VERSION ""

NS_ :

BS_:

BU_:

BO_ 258 VCLEFT_doorStatus: 8 Vector__XXX
 SG_ VCLEFT_mirrorDipped : 63|1@1+ (1,0) [0|0] "" Vector__XXX
 SG_ VCLEFT_frontHandlePulledPersist : 62|1@1+ (1,0) [0|0] "" Vector__XXX
 SG_ VCLEFT_rearHandlePulledPersist : 61|1@1+ (1,0) [0|0] "" Vector__XXX
 SG_ VCLEFT_mirrorHeatState : 58|3@1+ (1,0) [0|0] "" Vector__XXX
 SG_ VCLEFT_mirrorRecallState : 55|3@1+ (1,0) [0|0] "" Vector__XXX
 SG_ VCLEFT_mirrorFoldState : 52|3@1+ (1,0) [0|0] "" Vector__XXX
 SG_ VCLEFT_mirrorState : 49|3@1+ (1,0) [0|0] "" Vector__XXX
 SG_ VCLEFT_mirrorTiltYPosition : 41|8@1+ (0.02,0) [0|0] "" Vector__XXX
 SG_ VCLEFT_mirrorTiltXPosition : 33|8@1+ (0.02,0) [0|0] "" Vector__XXX
 SG_ VCLEFT_rearIntSwitchPressed : 32|1@1+ (1,0) [0|0] "" Vector__XXX
 SG_ VCLEFT_frontIntSwitchPressed : 31|1@1+ (1,0) [0|0] "" Vector__XXX
 SG_ VCLEFT_rearIntSwitchFaulted : 29|1@1+ (1,0) [0|0] "" Vector__XXX
 SG_ VCLEFT_frontIntSwitchFaulted : 28|1@1+ (1,0) [0|0] "" Vector__XXX
 SG_ VCLEFT_lastDoorReqSourceRear : 25|3@1+ (1,0) [0|0] "" Vector__XXX
 SG_ VCLEFT_lastDoorReqSourceFront : 22|3@1+ (1,0) [0|0] "" Vector__XXX
 SG_ VCLEFT_rearLatchStatus : 18|4@1+ (1,0) [0|0] "" Vector__XXX
 SG_ VCLEFT_frontLatchStatus : 14|4@1+ (1,0) [0|0] "" Vector__XXX
 SG_ VCLEFT_rearRelActuatorSwitch : 13|1@1+ (1,0) [0|0] "" Vector__XXX
 SG_ VCLEFT_frontRelActuatorSwitch : 12|1@1+ (1,0) [0|0] "" Vector__XXX
 SG_ VCLEFT_rearHandlePulled : 11|1@1+ (1,0) [0|0] "" Vector__XXX
 SG_ VCLEFT_frontHandlePulled : 10|1@1+ (1,0) [0|0] "" Vector__XXX
 SG_ VCLEFT_rearLatchSwitch : 9|1@1+ (1,0) [0|0] "" Vector__XXX
 SG_ VCLEFT_frontLatchSwitch : 8|1@1+ (1,0) [0|0] "" Vector__XXX
 SG_ VCLEFT_doorClosureStatusRear : 4|4@1+ (1,0) [0|0] "" Vector__XXX
 SG_ VCLEFT_doorClosureStatusFront : 0|4@1+ (1,0) [0|0] "" Vector__XXX

BO_ 259 VCRIGHT_doorStatus: 8 Vector__XXX
 SG_ VCRIGHT_rearHandlePulledPersist : 63|1@1+ (1,0) [0|0] "" Vector__XXX
 SG_ VCRIGHT_mirrorRecallState : 60|3@1+ (1,0) [0|0] "" Vector__XXX
 SG_ VCRIGHT_trunkLatchStatus : 56|4@1+ (1,0) [0|0] "" Vector__XXX
 SG_ VCRIGHT_mirrorDipped : 55|1@1+ (1,0) [0|0] "" Vector__XXX
 SG_ VCRIGHT_mirrorFoldState : 52|3@1+ (1,0) [0|0] "" Vector__XXX
 SG_ VCRIGHT_mirrorState : 49|3@1+ (1,0) [0|0] "" Vector__XXX
 SG_ VCRIGHT_mirrorTiltYPosition : 41|8@1+ (0.02,0) [0|0] "" Vector__XXX
 SG_ VCRIGHT_mirrorTiltXPosition : 33|8@1+ (0.02,0) [0|0] "" Vector__XXX
 SG_ VCRIGHT_rearIntSwitchPressed : 32|1@1+ (1,0) [0|0] "" Vector__XXX
 SG_ VCRIGHT_frontIntSwitchPressed : 31|1@1+ (1,0) [0|0] "" Vector__XXX
 SG_ VCRIGHT_frontHandlePulledPersist : 30|1@1+ (1,0) [0|0] "" Vector__XXX
 SG_ VCRIGHT_rearIntSwitchFaulted : 29|1@1+ (1,0) [0|0] "" Vector__XXX
 SG_ VCRIGHT_frontIntSwitchFaulted : 28|1@1+ (1,0) [0|0] "" Vector__XXX
 SG_ VCRIGHT_lastDoorReqSourceRear : 25|3@1+ (1,0) [0|0] "" Vector__XXX
 SG_ VCRIGHT_lastDoorReqSourceFront : 22|3@1+ (1,0) [0|0] "" Vector__XXX
 SG_ VCRIGHT_rearLatchStatus : 18|4@1+ (1,0) [0|0] "" Vector__XXX
 SG_ VCRIGHT_frontLatchStatus : 14|4@1+ (1,0) [0|0] "" Vector__XXX
 SG_ VCRIGHT_rearRelActuatorSwitch : 13|1@1+ (1,0) [0|0] "" Vector__XXX
 SG_ VCRIGHT_frontRelActuatorSwitch : 12|1@1+ (1,0) [0|0] "" Vector__XXX
 SG_ VCRIGHT_rearHandlePulled : 11|1@1+ (1,0) [0|0] "" Vector__XXX
 SG_ VCRIGHT_frontHandlePulled : 10|1@1+ (1,0) [0|0] "" Vector__XXX
 SG_ VCRIGHT_rearLatchSwitch : 9|1@1+ (1,0) [0|0] "" Vector__XXX
 SG_ VCRIGHT_frontLatchSwitch : 8|1@1+ (1,0) [0|0] "" Vector__XXX
 SG_ VCRIGHT_doorClosureStatusRear : 4|4@1+ (1,0) [0|0] "" Vector__XXX
 SG_ VCRIGHT_doorClosureStatusFront : 0|4@1+ (1,0) [0|0] "" Vector__XXX

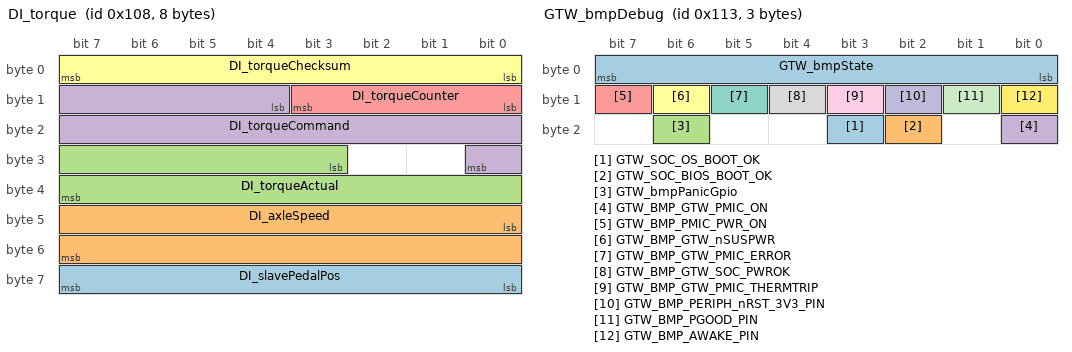
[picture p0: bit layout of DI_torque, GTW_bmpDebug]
BO_ 264 DI_torque: 8 VEH
 SG_ DI_slavePedalPos : 56|8@1+ (0.4,0) [0|100] "%"  X
 SG_ DI_axleSpeed : 40|16@1- (0.1,0) [0|0] "RPM"  X
 SG_ DI_torqueActual : 27|13@1- (2,0) [0|0] "Nm"  X
 SG_ DI_torqueCommand : 12|13@1- (2,0) [0|0] "Nm"  X
 SG_ DI_torqueCounter : 8|4@1+ (1,0) [0|0] ""  X
 SG_ DI_torqueChecksum : 0|8@1+ (1,0) [0|0] ""  X

BO_ 275 GTW_bmpDebug: 3 Vector__XXX
 SG_ GTW_SOC_OS_BOOT_OK : 19|1@1+ (1,0) [0|0] "" Vector__XXX
 SG_ GTW_SOC_BIOS_BOOT_OK : 18|1@1+ (1,0) [0|0] "" Vector__XXX
 SG_ GTW_bmpPanicGpio : 22|1@0+ (1,0) [0|0] "" Vector__XXX
 SG_ GTW_BMP_GTW_PMIC_ON : 16|1@1+ (1,0) [0|0] "" Vector__XXX
 SG_ GTW_BMP_PMIC_PWR_ON : 15|1@1+ (1,0) [0|0] "" Vector__XXX
 SG_ GTW_BMP_GTW_nSUSPWR : 14|1@1+ (1,0) [0|0] "" Vector__XXX
 SG_ GTW_BMP_GTW_PMIC_ERROR : 13|1@1+ (1,0) [0|0] "" Vector__XXX
 SG_ GTW_BMP_GTW_SOC_PWROK : 12|1@1+ (1,0) [0|0] "" Vector__XXX
 SG_ GTW_BMP_GTW_PMIC_THERMTRIP : 11|1@1+ (1,0) [0|0] "" Vector__XXX
 SG_ GTW_BMP_PERIPH_nRST_3V3_PIN : 10|1@1+ (1,0) [0|0] "" Vector__XXX
 SG_ GTW_BMP_PGOOD_PIN : 9|1@1+ (1,0) [0|0] "" Vector__XXX
 SG_ GTW_BMP_AWAKE_PIN : 8|1@1+ (1,0) [0|0] "" Vector__XXX
 SG_ GTW_bmpState : 7|8@0+ (1,0) [0|0] "" Vector__XXX

BO_ 280 DI_systemStatus: 8 Vector__XXX
 SG_ DI_vehicleAcceleration : 52|12@1- (0.01,0) [0|0] "" Vector__XXX
 SG_ DI_regenLight : 51|1@1+ (1,0) [0|0] "" Vector__XXX
 SG_ DI_autonomyControlActive : 50|1@1+ (1,0) [0|0] "" Vector__XXX
 SG_ DI_trackModeState : 48|2@1+ (1,0) [0|0] "" Vector__XXX
 SG_ DI_keepDrivePowerStateRequest : 47|1@1+ (1,0) [0|0] "" Vector__XXX
 SG_ DI_brakeSource : 46|1@1+ (1,0) [0|0] "" Vector__XXX
 SG_ DI_epbRequest : 44|2@1+ (1,0) [0|0] "" Vector__XXX
 SG_ DI_dynoModeAvailable : 43|1@1+ (1,0) [0|0] "" Vector__XXX
 SG_ DI_tractionControlMode : 40|3@1+ (1,0) [0|0] "" Vector__XXX
 SG_ DI_accelPedalPos : 32|8@1+ (0.4,0) [0|0] "" Vector__XXX
 SG_ DI_hvilSystemStatus : 27|2@1+ (1,0) [0|0] "" Vector__XXX
 SG_ DI_driveBlocked : 24|3@1+ (1,0) [0|0] "" Vector__XXX
 SG_ DI_gear : 21|3@1+ (1,0) [0|0] "" Vector__XXX
 SG_ DI_brakePedalState : 19|2@1+ (1,0) [0|0] "" Vector__XXX
 SG_ DI_systemState : 16|3@1+ (1,0) [0|0] "" Vector__XXX
 SG_ DI_immobilizerState : 13|3@1+ (1,0) [0|0] "" Vector__XXX
 SG_ DI_systemStatusCounter : 8|4@1+ (1,0) [0|0] "" Vector__XXX
 SG_ DI_systemStatusChecksum : 0|8@1+ (1,0) [0|0] "" Vector__XXX

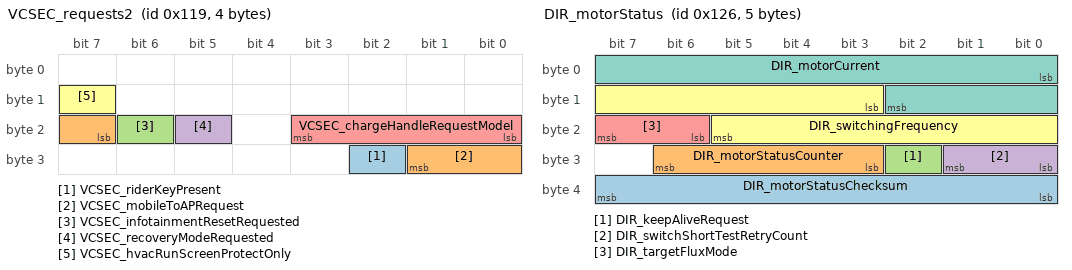
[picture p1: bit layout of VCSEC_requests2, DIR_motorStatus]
BO_ 281 VCSEC_requests2: 4 Vector__XXX
 SG_ VCSEC_riderKeyPresent : 26|1@1+ (1,0) [0|0] "" Vector__XXX
 SG_ VCSEC_mobileToAPRequest : 23|3@1+ (1,0) [0|0] "" Vector__XXX
 SG_ VCSEC_infotainmentResetRequested : 22|1@1+ (1,0) [0|0] "" Vector__XXX
 SG_ VCSEC_recoveryModeRequested : 21|1@1+ (1,0) [0|0] "" Vector__XXX
 SG_ VCSEC_chargeHandleRequestModel : 16|4@1+ (1,0) [0|0] "" Vector__XXX
 SG_ VCSEC_hvacRunScreenProtectOnly : 15|1@1+ (1,0) [0|0] "" Vector__XXX

BO_ 290 VCLEFT_doorStatus2: 8 Vector__XXX
 SG_ VCLEFT_mirrorTiltYOffset m1 : 56|8@1- (0.02,0) [0|0] "" Vector__XXX
 SG_ VCLEFT_rearHandlePWM m0 : 56|7@1+ (1,0) [0|0] "" Vector__XXX
 SG_ VCLEFT_frontHandlePWM m0 : 48|7@1+ (1,0) [0|0] "" Vector__XXX
 SG_ VCLEFT_mirrorTiltXOffset m1 : 48|8@1- (0.02,0) [0|0] "" Vector__XXX
 SG_ VCLEFT_mirrorDimmed m0 : 47|1@1+ (1,0) [0|0] "" Vector__XXX
 SG_ VCLEFT_BPillarCameraHeaterCurrent m1 : 40|6@1+ (0.02,0) [0|0] "" Vector__XXX
 SG_ VCLEFT_mirrorFoldCurrent m0 : 40|7@1- (0.05,0) [0|0] "" Vector__XXX
 SG_ VCLEFT_rearHandle5vEnable m0 : 39|1@1+ (1,0) [0|0] "" Vector__XXX
 SG_ VCLEFT_frontHandle5vEnable m0 : 38|1@1+ (1,0) [0|0] "" Vector__XXX
 SG_ VCLEFT_rearHandleDebounceStatus m0 : 35|3@1+ (1,0) [0|0] "" Vector__XXX
 SG_ VCLEFT_frontHandleDebounceStatus m0 : 32|3@1+ (1,0) [0|0] "" Vector__XXX
 SG_ VCLEFT_mirrorFoldType m0 : 30|2@1+ (1,0) [0|0] "" Vector__XXX
 SG_ VCLEFT_rearHandleRawStatus m0 : 27|3@1+ (1,0) [0|0] "" Vector__XXX
 SG_ VCLEFT_frontHandleRawStatus m0 : 24|3@1+ (1,0) [0|0] "" Vector__XXX
 SG_ VCLEFT_rearDoorState m0 : 20|3@1+ (1,0) [0|0] "" Vector__XXX
 SG_ VCLEFT_frontDoorState m0 : 17|3@1+ (1,0) [0|0] "" Vector__XXX
 SG_ VCLEFT_BPillarCameraHeaterState m1 : 16|3@1+ (1,0) [0|0] "" Vector__XXX
 SG_ VCLEFT_vehicleInMotion m0 : 16|1@1+ (1,0) [0|0] "" Vector__XXX
 SG_ VCLEFT_frontLatchRelDuty m1 : 8|8@1+ (1,0) [0|0] "" Vector__XXX
 SG_ VCLEFT_rearLatchRelDuty m0 : 8|8@1+ (1,0) [0|0] "" Vector__XXX
 SG_ VCLEFT_doorStatus2Index M : 0|1@1+ (1,0) [0|0] "" Vector__XXX

BO_ 291 VCRIGHT_doorStatus2: 8 Vector__XXX
 SG_ VCRIGHT_trunkHomeSwitch m0 : 63|1@1+ (1,0) [0|0] "" Vector__XXX
 SG_ VCRIGHT_trunkPawlSwitch m0 : 62|1@1+ (1,0) [0|0] "" Vector__XXX
 SG_ VCRIGHT_trunkRatchetSwitch m0 : 61|1@1+ (1,0) [0|0] "" Vector__XXX
 SG_ VCRIGHT_mirrorTiltYOffset m1 : 56|8@1- (0.02,0) [0|0] "" Vector__XXX
 SG_ VCRIGHT_mirrorTiltXOffset m1 : 48|8@1- (0.02,0) [0|0] "" Vector__XXX
 SG_ VCRIGHT_rearDefrostCurrentFiltered m0 : 48|7@1+ (1,0) [0|0] "" Vector__XXX
 SG_ VCRIGHT_gloveboxOutput m0 : 47|1@1+ (1,0) [0|0] "" Vector__XXX
 SG_ VCRIGHT_BPillarCameraHeaterCurrent m1 : 40|6@1+ (0.02,0) [0|0] "" Vector__XXX
 SG_ VCRIGHT_mirrorFoldCurrent m0 : 40|7@1- (0.05,0) [0|0] "" Vector__XXX
 SG_ VCRIGHT_rearHandle5vEnable m0 : 39|1@1+ (1,0) [0|0] "" Vector__XXX
 SG_ VCRIGHT_frontHandle5vEnable m0 : 38|1@1+ (1,0) [0|0] "" Vector__XXX
 SG_ VCRIGHT_rearHandleDebounceStatus m0 : 35|3@1+ (1,0) [0|0] "" Vector__XXX
 SG_ VCRIGHT_frontHandleDebounceStatus m0 : 32|3@1+ (1,0) [0|0] "" Vector__XXX
 SG_ VCRIGHT_mirrorFoldType m0 : 30|2@1+ (1,0) [0|0] "" Vector__XXX
 SG_ VCRIGHT_rearHandleRawStatus m0 : 27|3@1+ (1,0) [0|0] "" Vector__XXX
 SG_ VCRIGHT_frontHandleRawStatus m0 : 24|3@1+ (1,0) [0|0] "" Vector__XXX
 SG_ VCRIGHT_mirrorDimmed m0 : 23|1@1+ (1,0) [0|0] "" Vector__XXX
 SG_ VCRIGHT_rearDoorState m0 : 20|3@1+ (1,0) [0|0] "" Vector__XXX
 SG_ VCRIGHT_frontDoorState m0 : 17|3@1+ (1,0) [0|0] "" Vector__XXX
 SG_ VCRIGHT_BPillarCameraHeaterState m1 : 16|3@1+ (1,0) [0|0] "" Vector__XXX
 SG_ VCRIGHT_vehicleInMotion m0 : 16|1@1+ (1,0) [0|0] "" Vector__XXX
 SG_ VCRIGHT_frontLatchRelDuty m1 : 8|8@1+ (1,0) [0|0] "" Vector__XXX
 SG_ VCRIGHT_rearLatchRelDuty m0 : 8|8@1+ (1,0) [0|0] "" Vector__XXX
 SG_ VCRIGHT_doorStatus2Index M : 0|1@1+ (1,0) [0|0] "" Vector__XXX

BO_ 294 DIR_motorStatus: 5 Vector__XXX
 SG_ DIR_motorStatusChecksum : 32|8@1+ (1,0) [0|0] "" Vector__XXX
 SG_ DIR_motorStatusCounter : 27|4@1+ (1,0) [0|0] "" Vector__XXX
 SG_ DIR_keepAliveRequest : 26|1@1+ (1,0) [0|0] "" Vector__XXX
 SG_ DIR_switchShortTestRetryCount : 24|2@1+ (1,0) [0|0] "" Vector__XXX
 SG_ DIR_targetFluxMode : 22|2@1+ (1,0) [0|0] "" Vector__XXX
 SG_ DIR_switchingFrequency : 11|11@1+ (0.01,0) [0|0] "" Vector__XXX
 SG_ DIR_motorCurrent : 0|11@1+ (1,0) [0|0] "" Vector__XXX

BO_ 296 DI_systemLimits: 6 Vector__XXX
 SG_ DI_immobilizerAuthLevel : 33|2@1+ (1,0) [0|0] "" Vector__XXX
 SG_ DI_undersideAbuse : 32|1@1+ (1,0) [0|0] "" Vector__XXX
 SG_ DI_limitClosureNotClosed : 31|1@1+ (1,0) [0|0] "" Vector__XXX
 SG_ DI_proximity : 30|1@1+ (1,0) [0|0] "" Vector__XXX
 SG_ DI_vehicleSpeedLimitReason : 25|5@1+ (1,0) [0|0] "" Vector__XXX
 SG_ DI_vehicleSpeedLimit : 16|9@1+ (1,0) [0|0] "" Vector__XXX
 SG_ DI_vehicleSpeedLimitType : 14|2@1+ (1,0) [0|0] "" Vector__XXX
 SG_ DI_limitCdp : 13|1@1+ (1,0) [0|0] "" Vector__XXX
 SG_ DI_limitSystemSpinDownLearning : 12|1@1+ (1,0) [0|0] "" Vector__XXX
 SG_ DI_limitBmsMiaFreeze : 11|1@1+ (1,0) [0|0] "" Vector__XXX
 SG_ DI_limitVehicleSpeed : 10|1@1+ (1,0) [0|0] "" Vector__XXX
 SG_ DI_limitRegenTorque : 9|1@1+ (1,0) [0|0] "" Vector__XXX
 SG_ DI_limitDriveTorque : 8|1@1+ (1,0) [0|0] "" Vector__XXX
 SG_ DI_limitShift : 7|1@1+ (1,0) [0|0] "" Vector__XXX
 SG_ DI_limitSystemGPO : 6|1@1+ (1,0) [0|0] "" Vector__XXX
 SG_ DI_limitSystemLimp : 5|1@1+ (1,0) [0|0] "" Vector__XXX
 SG_ DI_limitObstacleDetection : 4|1@1+ (1,0) [0|0] "" Vector__XXX
 SG_ DI_limitVBatHigh : 3|1@1+ (1,0) [0|0] "" Vector__XXX
 SG_ DI_limitVBatLow : 2|1@1+ (1,0) [0|0] "" Vector__XXX
 SG_ DI_limitIBat : 1|1@1+ (1,0) [0|0] "" Vector__XXX
 SG_ DI_limitRegenPower : 0|1@1+ (1,0) [0|0] "" Vector__XXX

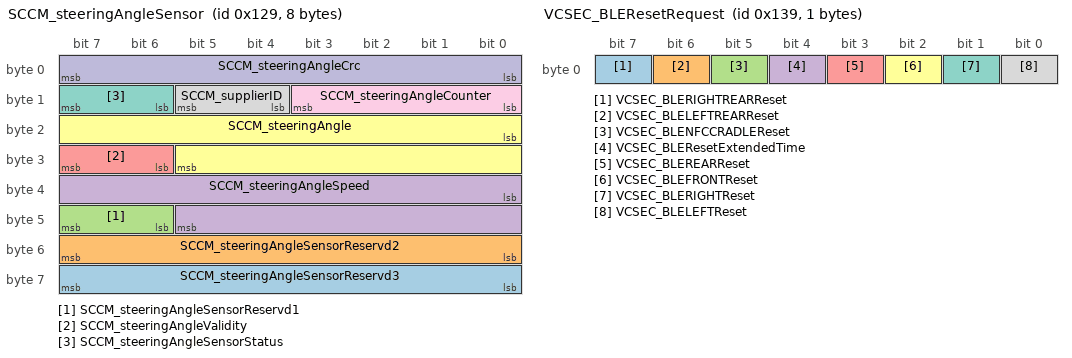
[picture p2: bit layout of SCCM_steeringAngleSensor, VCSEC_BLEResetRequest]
BO_ 297 SCCM_steeringAngleSensor: 8 Vector__XXX
 SG_ SCCM_steeringAngleSensorReservd3 : 56|8@1+ (1,0) [0|0] "" Vector__XXX
 SG_ SCCM_steeringAngleSensorReservd2 : 48|8@1+ (1,0) [0|0] "" Vector__XXX
 SG_ SCCM_steeringAngleSensorReservd1 : 46|2@1+ (1,0) [0|0] "" Vector__XXX
 SG_ SCCM_steeringAngleSpeed : 32|14@1+ (0.5,-4096) [0|0] "" Vector__XXX
 SG_ SCCM_steeringAngleValidity : 30|2@1+ (1,0) [0|0] "" Vector__XXX
 SG_ SCCM_steeringAngle : 16|14@1+ (0.1,-819.2) [0|0] "" Vector__XXX
 SG_ SCCM_steeringAngleSensorStatus : 14|2@1+ (1,0) [0|0] "" Vector__XXX
 SG_ SCCM_supplierID : 12|2@1+ (1,0) [0|0] "" Vector__XXX
 SG_ SCCM_steeringAngleCounter : 8|4@1+ (1,0) [0|0] "" Vector__XXX
 SG_ SCCM_steeringAngleCrc : 0|8@1+ (1,0) [0|0] "" Vector__XXX

BO_ 306 BMS_hvBusStatus: 6 VEH
 SG_ BMS_currentUnfiltered : 32|16@1- (-0.05,822) [0|0] "A"  X
 SG_ BMS_packCurrent : 16|15@1- (-0.1,0) [0|0] "A"  X
 SG_ BMS_packVoltage : 0|16@1+ (0.01,0) [0|0] "V"  X

BO_ 313 VCSEC_BLEResetRequest: 1 Vector__XXX
 SG_ VCSEC_BLERIGHTREARReset : 7|1@1+ (1,0) [0|0] "" Vector__XXX
 SG_ VCSEC_BLELEFTREARReset : 6|1@1+ (1,0) [0|0] "" Vector__XXX
 SG_ VCSEC_BLENFCCRADLEReset : 5|1@1+ (1,0) [0|0] "" Vector__XXX
 SG_ VCSEC_BLEResetExtendedTime : 4|1@1+ (1,0) [0|0] "" Vector__XXX
 SG_ VCSEC_BLEREARReset : 3|1@1+ (1,0) [0|0] "" Vector__XXX
 SG_ VCSEC_BLEFRONTReset : 2|1@1+ (1,0) [0|0] "" Vector__XXX
 SG_ VCSEC_BLERIGHTReset : 1|1@1+ (1,0) [0|0] "" Vector__XXX
 SG_ VCSEC_BLELEFTReset : 0|1@1+ (1,0) [0|0] "" Vector__XXX

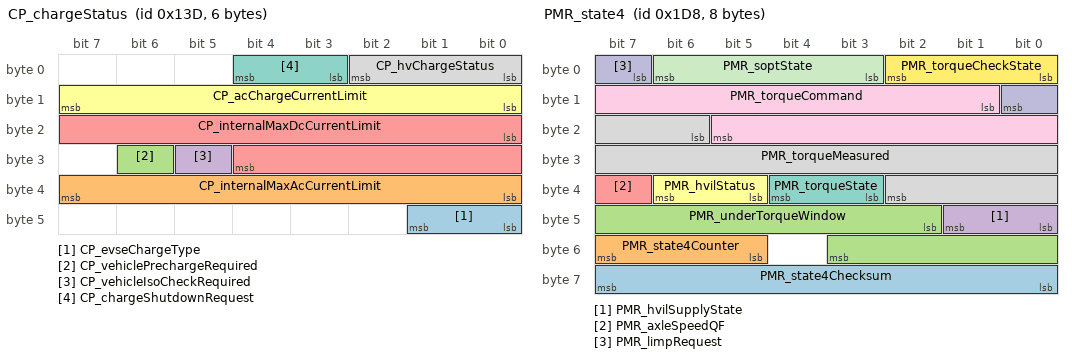
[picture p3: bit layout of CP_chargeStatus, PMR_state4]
BO_ 317 CP_chargeStatus: 6 VEH
 SG_ CP_evseChargeType : 40|2@1+ (1,0) [0|2] ""  Receiver
 SG_ CP_internalMaxAcCurrentLimit : 32|8@1+ (0.5,0) [0|127.5] "A"  Receiver
 SG_ CP_vehiclePrechargeRequired : 30|1@1+ (1,0) [0|1] ""  Receiver
 SG_ CP_vehicleIsoCheckRequired : 29|1@1+ (1,0) [0|1] ""  Receiver
 SG_ CP_internalMaxDcCurrentLimit : 16|13@1+ (0.146502,0) [0|1200] "A"  Receiver
 SG_ CP_acChargeCurrentLimit : 8|8@1+ (0.5,0) [0|127.5] "A"  Receiver
 SG_ CP_chargeShutdownRequest : 3|2@1+ (1,0) [0|2] ""  Receiver
 SG_ CP_hvChargeStatus : 0|3@1+ (1,0) [0|6] ""  Receiver

BO_ 322 VCLEFT_liftgateStatus: 8 Vector__XXX
 SG_ VCLEFT_liftgateLatchRequest m0 : 61|3@1+ (1,0) [0|0] "" Vector__XXX
 SG_ VCLEFT_liftgateAboveCrossoverAngle m0 : 59|1@1+ (1,0) [0|0] "" Vector__XXX
 SG_ VCLEFT_liftgateCloseWarnChimeRequest m0 : 56|1@1+ (1,0) [0|0] "" Vector__XXX
 SG_ VCLEFT_liftgateGeofenceState m0 : 48|2@1+ (1,0) [0|0] "" Vector__XXX
 SG_ VCLEFT_liftgateNewSaveHeight m0 : 40|8@1+ (1,0) [0|0] "" Vector__XXX
 SG_ VCLEFT_liftgateNewHeightNudge m0 : 39|1@1+ (1,0) [0|0] "" Vector__XXX
 SG_ VCLEFT_liftgateHeight m1 : 38|8@1+ (1,0) [0|0] "" Vector__XXX
 SG_ VCLEFT_liftgateRequestSource m0 : 35|4@1+ (1,0) [0|0] "" Vector__XXX
 SG_ VCLEFT_liftgateStaticStrutMode m0 : 32|3@1+ (1,0) [0|0] "" Vector__XXX
 SG_ VCLEFT_liftgateSpeed m1 : 28|10@1- (0.1,0) [0|0] "" Vector__XXX
 SG_ VCLEFT_liftgateEstimatedStrutTemp m0 : 24|8@1+ (1,-60) [0|0] "" Vector__XXX
 SG_ VCLEFT_liftgatePhysicalChimeRequest m0 : 21|3@1+ (1,0) [0|0] "" Vector__XXX
 SG_ VCLEFT_liftgatePosition m1 : 21|7@1- (1,46) [0|0] "" Vector__XXX
 SG_ VCLEFT_liftgateUIChimeRequest m0 : 18|3@1+ (1,0) [0|0] "" Vector__XXX
 SG_ VCLEFT_liftgatePositionCalibrated m0 : 17|1@1+ (1,0) [0|0] "" Vector__XXX
 SG_ VCLEFT_liftgateMvmntNotAllowedCondition m0 : 14|3@1+ (1,0) [0|0] "" Vector__XXX
 SG_ VCLEFT_liftgateStrutCurrent m1 : 11|10@1- (0.1,0) [0|0] "" Vector__XXX
 SG_ VCLEFT_liftgateStoppingCondition m0 : 10|4@1+ (1,0) [0|0] "" Vector__XXX
 SG_ VCLEFT_liftgateState m0 : 3|4@1+ (1,0) [0|0] "" Vector__XXX
 SG_ VCLEFT_liftgateStrutDutyCycle m1 : 3|8@1- (1,0) [0|0] "" Vector__XXX
 SG_ VCLEFT_liftgateStatusIndex M : 0|2@1+ (1,0) [0|0] "" Vector__XXX

BO_ 470 DIR_limits: 8 Vector__XXX
 SG_ DIR_pstgDisableSW3PS : 63|1@1+ (1,0) [0|0] "" Vector__XXX
 SG_ DIR_pstgDisableHW3PS : 62|1@1+ (1,0) [0|0] "" Vector__XXX
 SG_ DIR_currentLimit : 46|16@1+ (0.1,0) [0|0] "" Vector__XXX
 SG_ DIR_magnetFluxError : 38|8@1- (8e-05,0) [0|0] "" Vector__XXX
 SG_ DIR_statorTempFromResist : 30|8@1+ (1,-40) [0|0] "" Vector__XXX
 SG_ DIR_limitStatorHousingTemp : 29|1@1+ (1,0) [0|0] "" Vector__XXX
 SG_ DIR_limitUnitSpinDownLearning : 28|1@1+ (1,0) [0|0] "" Vector__XXX
 SG_ DIR_limithvDcCableTemp : 27|1@1+ (1,0) [0|0] "" Vector__XXX
 SG_ DIR_limitRotorTemp : 26|1@1+ (1,0) [0|0] "" Vector__XXX
 SG_ DIR_limitposDcBusbarTemp : 25|1@1+ (1,0) [0|0] "" Vector__XXX
 SG_ DIR_limitnegDcBusbarTemp : 24|1@1+ (1,0) [0|0] "" Vector__XXX
 SG_ DIR_limitdcLinkCapTemp : 23|1@1+ (1,0) [0|0] "" Vector__XXX
 SG_ DIR_limitphaseOutLugTemp : 22|1@1+ (1,0) [0|0] "" Vector__XXX
 SG_ DIR_limitphaseOutBusBarWeldTemp : 21|1@1+ (1,0) [0|0] "" Vector__XXX
 SG_ DIR_limitphaseOutBusbarTemp : 20|1@1+ (1,0) [0|0] "" Vector__XXX
 SG_ DIR_limitClutch : 19|1@1+ (1,0) [0|0] "" Vector__XXX
 SG_ DIR_limitStatorFrequency : 18|1@1+ (1,0) [0|0] "" Vector__XXX
 SG_ DIR_limitOilPumpFluidTemp : 17|1@1+ (1,0) [0|0] "" Vector__XXX
 SG_ DIR_limitShockTorque : 16|1@1+ (1,0) [0|0] "" Vector__XXX
 SG_ DIR_limitUnitGPO : 15|1@1+ (1,0) [0|0] "" Vector__XXX
 SG_ DIR_limitDiff : 14|1@1+ (1,0) [0|0] "" Vector__XXX
 SG_ DIR_limitMotorSpeed : 13|1@1+ (1,0) [0|0] "" Vector__XXX
 SG_ DIR_limitDcCapTemp : 12|1@1+ (1,0) [0|0] "" Vector__XXX
 SG_ DIR_limitBaseSpeed : 11|1@1+ (1,0) [0|0] "" Vector__XXX
 SG_ DIR_limitTCRegen : 10|1@1+ (1,0) [0|0] "" Vector__XXX
 SG_ DIR_limitTCDrive : 9|1@1+ (1,0) [0|0] "" Vector__XXX
 SG_ DIR_limitMotorVoltage : 8|1@1+ (1,0) [0|0] "" Vector__XXX
 SG_ DIR_limitMotorCurrent : 7|1@1+ (1,0) [0|0] "" Vector__XXX
 SG_ DIR_limitDischargePower : 6|1@1+ (1,0) [0|0] "" Vector__XXX
 SG_ DIR_limitDeltaFluidTemp : 5|1@1+ (1,0) [0|0] "" Vector__XXX
 SG_ DIR_limitUnitLimp : 4|1@1+ (1,0) [0|0] "" Vector__XXX
 SG_ DIR_limitPoleTemp : 3|1@1+ (1,0) [0|0] "" Vector__XXX
 SG_ DIR_limitStatorTemp : 2|1@1+ (1,0) [0|0] "" Vector__XXX
 SG_ DIR_limitInverterTemp : 1|1@1+ (1,0) [0|0] "" Vector__XXX
 SG_ DIR_limitPCBTemp : 0|1@1+ (1,0) [0|0] "" Vector__XXX

BO_ 472 PMR_state4: 8 Vector__XXX
 SG_ PMR_state4Checksum : 56|8@1+ (1,0) [0|0] "" Vector__XXX
 SG_ PMR_state4Counter : 53|3@1+ (1,0) [0|0] "" Vector__XXX
 SG_ PMR_underTorqueWindow : 42|10@1+ (0.005,0) [0|0] "" Vector__XXX
 SG_ PMR_hvilSupplyState : 40|2@1+ (1,0) [0|0] "" Vector__XXX
 SG_ PMR_axleSpeedQF : 39|1@1+ (1,0) [0|0] "" Vector__XXX
 SG_ PMR_hvilStatus : 37|2@1+ (1,0) [0|0] "" Vector__XXX
 SG_ PMR_torqueState : 35|2@1+ (1,0) [0|0] "" Vector__XXX
 SG_ PMR_torqueMeasured : 22|13@1- (2,0) [0|0] "" Vector__XXX
 SG_ PMR_torqueCommand : 9|13@1- (2,0) [0|0] "" Vector__XXX
 SG_ PMR_limpRequest : 7|2@1+ (1,0) [0|0] "" Vector__XXX
 SG_ PMR_soptState : 3|4@1+ (1,0) [0|0] "" Vector__XXX
 SG_ PMR_torqueCheckState : 0|3@1+ (1,0) [0|0] "" Vector__XXX

BO_ 473 VCSEC_IsoTpUDPPipeUI: 3 Vector__XXX
 SG_ VCSEC_IsoTpUDPPipeUI2 : 16|8@1+ (1,0) [0|0] "" Vector__XXX
 SG_ VCSEC_IsoTpUDPPipeUI1 : 8|8@1+ (1,0) [0|0] "" Vector__XXX
 SG_ VCSEC_IsoTpUDPPipeUI0 : 0|8@1+ (1,0) [0|0] "" Vector__XXX

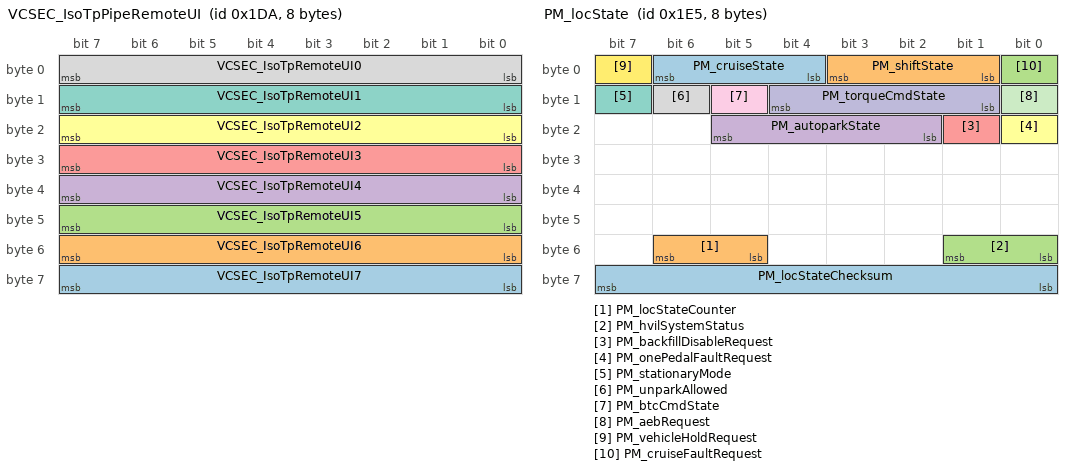
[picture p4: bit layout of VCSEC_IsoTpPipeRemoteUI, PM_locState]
BO_ 474 VCSEC_IsoTpPipeRemoteUI: 8 Vector__XXX
 SG_ VCSEC_IsoTpRemoteUI7 : 56|8@1+ (1,0) [0|0] "" Vector__XXX
 SG_ VCSEC_IsoTpRemoteUI6 : 48|8@1+ (1,0) [0|0] "" Vector__XXX
 SG_ VCSEC_IsoTpRemoteUI5 : 40|8@1+ (1,0) [0|0] "" Vector__XXX
 SG_ VCSEC_IsoTpRemoteUI4 : 32|8@1+ (1,0) [0|0] "" Vector__XXX
 SG_ VCSEC_IsoTpRemoteUI3 : 24|8@1+ (1,0) [0|0] "" Vector__XXX
 SG_ VCSEC_IsoTpRemoteUI2 : 16|8@1+ (1,0) [0|0] "" Vector__XXX
 SG_ VCSEC_IsoTpRemoteUI1 : 8|8@1+ (1,0) [0|0] "" Vector__XXX
 SG_ VCSEC_IsoTpRemoteUI0 : 0|8@1+ (1,0) [0|0] "" Vector__XXX

BO_ 485 PM_locState: 8 Vector__XXX
 SG_ PM_locStateChecksum : 56|8@1+ (1,0) [0|0] "" Vector__XXX
 SG_ PM_locStateCounter : 53|2@1+ (1,0) [0|0] "" Vector__XXX
 SG_ PM_hvilSystemStatus : 48|2@1+ (1,0) [0|0] "" Vector__XXX
 SG_ PM_autoparkState : 18|4@1+ (1,0) [0|0] "" Vector__XXX
 SG_ PM_backfillDisableRequest : 17|1@1+ (1,0) [0|0] "" Vector__XXX
 SG_ PM_onePedalFaultRequest : 16|1@1+ (1,0) [0|0] "" Vector__XXX
 SG_ PM_stationaryMode : 15|1@1+ (1,0) [0|0] "" Vector__XXX
 SG_ PM_unparkAllowed : 14|1@1+ (1,0) [0|0] "" Vector__XXX
 SG_ PM_btcCmdState : 13|1@1+ (1,0) [0|0] "" Vector__XXX
 SG_ PM_torqueCmdState : 9|4@1+ (1,0) [0|0] "" Vector__XXX
 SG_ PM_aebRequest : 8|1@1+ (1,0) [0|0] "" Vector__XXX
 SG_ PM_vehicleHoldRequest : 7|1@1+ (1,0) [0|0] "" Vector__XXX
 SG_ PM_cruiseState : 4|3@1+ (1,0) [0|0] "" Vector__XXX
 SG_ PM_shiftState : 1|3@1+ (1,0) [0|0] "" Vector__XXX
 SG_ PM_cruiseFaultRequest : 0|1@1+ (1,0) [0|0] "" Vector__XXX

BO_ 504 VCLEFT_intrusionSensorStatus: 4 Vector__XXX
 SG_ VCLEFT_intrusionUltraTripped : 26|1@1+ (1,0) [0|0] "" Vector__XXX
 SG_ VCLEFT_intrusionTiltTripped : 25|1@1+ (1,0) [0|0] "" Vector__XXX
 SG_ VCLEFT_sirenMIA : 24|1@1+ (1,0) [0|0] "" Vector__XXX
 SG_ VCLEFT_DBG_System_Error : 23|1@1+ (1,0) [0|0] "" Vector__XXX
 SG_ VCLEFT_DBG_LM_SelfTest_Status : 22|1@1+ (1,0) [0|0] "" Vector__XXX
 SG_ VCLEFT_DBG_USS_SelfTest_Status : 21|1@1+ (1,0) [0|0] "" Vector__XXX
 SG_ VCLEFT_DBG_Eeprom_ST_Status : 20|1@1+ (1,0) [0|0] "" Vector__XXX
 SG_ VCLEFT_DBG_Reserved_08 : 19|1@1+ (1,0) [0|0] "" Vector__XXX
 SG_ VCLEFT_DBG_Reserved_07 : 18|1@1+ (1,0) [0|0] "" Vector__XXX
 SG_ VCLEFT_DBG_Siren_is_sounding : 17|1@1+ (1,0) [0|0] "" Vector__XXX
 SG_ VCLEFT_DBG_Invalid_Parameter : 16|1@1+ (1,0) [0|0] "" Vector__XXX
 SG_ VCLEFT_DBG_Siren_Int_Trigger : 15|1@1+ (1,0) [0|0] "" Vector__XXX
 SG_ VCLEFT_DBG_Siren_ST_Status : 14|1@1+ (1,0) [0|0] "" Vector__XXX
 SG_ VCLEFT_DBG_LM_Alarm_Status : 13|1@1+ (1,0) [0|0] "" Vector__XXX
 SG_ VCLEFT_DBG_USS_Alarm_Status : 12|1@1+ (1,0) [0|0] "" Vector__XXX
 SG_ VCLEFT_DBG_Veh_Settings_Status : 8|4@1+ (1,0) [0|0] "" Vector__XXX
 SG_ VCLEFT_DBG_SelfTest_Status : 7|1@1+ (1,0) [0|0] "" Vector__XXX
 SG_ VCLEFT_DBG_Suspensions_Status : 6|1@1+ (1,0) [0|0] "" Vector__XXX
 SG_ VCLEFT_DBG_Window_Status : 5|1@1+ (1,0) [0|0] "" Vector__XXX
 SG_ VCLEFT_DBG_Heater_Status : 4|1@1+ (1,0) [0|0] "" Vector__XXX
 SG_ VCLEFT_DBG_Air_Cond_Status : 3|1@1+ (1,0) [0|0] "" Vector__XXX
 SG_ VCLEFT_DBG_System_Status : 0|3@1+ (1,0) [0|0] "" Vector__XXX

BO_ 505 VCSEC_requests: 8 Vector__XXX
 SG_ VCSEC_frontTrunkRequestReason : 54|3@1+ (1,0) [0|0] "" Vector__XXX
 SG_ VCSEC_frontTrunkClosureRequest : 51|3@1+ (1,0) [0|0] "" Vector__XXX
 SG_ VCSEC_chargeportRequestReason : 47|3@1+ (1,0) [0|0] "" Vector__XXX
 SG_ VCSEC_snapshotRequested : 43|4@1+ (1,0) [0|0] "" Vector__XXX
 SG_ VCSEC_closeAllStatus : 41|2@1+ (1,0) [0|0] "" Vector__XXX
 SG_ VCSEC_driveAttemptedWithoutAuth : 36|4@1+ (1,0) [0|0] "" Vector__XXX
 SG_ VCSEC_rdMapDumpRequested : 35|1@1+ (1,0) [0|0] "" Vector__XXX
 SG_ VCSEC_rearTrunkRequestReason : 32|3@1+ (1,0) [0|0] "" Vector__XXX
 SG_ VCSEC_rearRightRequestReason : 29|3@1+ (1,0) [0|0] "" Vector__XXX
 SG_ VCSEC_rearLeftRequestReason : 26|3@1+ (1,0) [0|0] "" Vector__XXX
 SG_ VCSEC_frontRightRequestReason : 23|3@1+ (1,0) [0|0] "" Vector__XXX
 SG_ VCSEC_frontLeftRequestReason : 20|3@1+ (1,0) [0|0] "" Vector__XXX
 SG_ VCSEC_rearTrunkClosureRequest : 17|3@1+ (1,0) [0|0] "" Vector__XXX
 SG_ VCSEC_rearRightClosureRequest : 14|3@1+ (1,0) [0|0] "" Vector__XXX
 SG_ VCSEC_rearLeftClosureRequest : 11|3@1+ (1,0) [0|0] "" Vector__XXX
 SG_ VCSEC_frontRightClosureRequest : 8|3@1+ (1,0) [0|0] "" Vector__XXX
 SG_ VCSEC_frontLeftClosureRequest : 5|3@1+ (1,0) [0|0] "" Vector__XXX
 SG_ VCSEC_presentHandles : 4|1@1+ (1,0) [0|0] "" Vector__XXX
 SG_ VCSEC_chargePortRequest : 0|2@1+ (1,0) [0|0] "" Vector__XXX

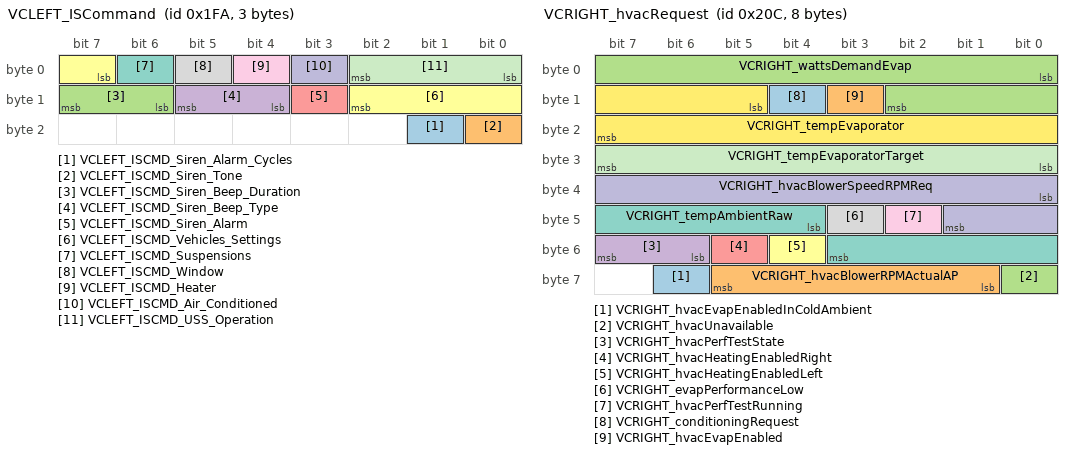
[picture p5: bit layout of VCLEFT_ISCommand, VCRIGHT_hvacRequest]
BO_ 506 VCLEFT_ISCommand: 3 Vector__XXX
 SG_ VCLEFT_ISCMD_Siren_Alarm_Cycles : 17|1@1+ (1,0) [0|0] "" Vector__XXX
 SG_ VCLEFT_ISCMD_Siren_Tone : 16|1@1+ (1,0) [0|0] "" Vector__XXX
 SG_ VCLEFT_ISCMD_Siren_Beep_Duration : 14|2@1+ (1,0) [0|0] "" Vector__XXX
 SG_ VCLEFT_ISCMD_Siren_Beep_Type : 12|2@1+ (1,0) [0|0] "" Vector__XXX
 SG_ VCLEFT_ISCMD_Siren_Alarm : 11|1@1+ (1,0) [0|0] "" Vector__XXX
 SG_ VCLEFT_ISCMD_Vehicles_Settings : 7|4@1+ (1,0) [0|0] "" Vector__XXX
 SG_ VCLEFT_ISCMD_Suspensions : 6|1@1+ (1,0) [0|0] "" Vector__XXX
 SG_ VCLEFT_ISCMD_Window : 5|1@1+ (1,0) [0|0] "" Vector__XXX
 SG_ VCLEFT_ISCMD_Heater : 4|1@1+ (1,0) [0|0] "" Vector__XXX
 SG_ VCLEFT_ISCMD_Air_Conditioned : 3|1@1+ (1,0) [0|0] "" Vector__XXX
 SG_ VCLEFT_ISCMD_USS_Operation : 0|3@1+ (1,0) [0|0] "" Vector__XXX

BO_ 507 VCLEFT_TLCStatus: 8 Vector__XXX
 SG_ VCLEFT_TLCTotalCurrent m0 : 56|8@1+ (0.1,0) [0|0] "" Vector__XXX
 SG_ VCLEFT_TLCReverseCurrent m0 : 48|8@1+ (0.1,0) [0|0] "" Vector__XXX
 SG_ VCLEFT_TLCState_Reverse m1 : 41|3@1+ (1,0) [0|0] "" Vector__XXX
 SG_ VCLEFT_TLCFogCurrent m0 : 40|8@1+ (0.1,0) [0|0] "" Vector__XXX
 SG_ VCLEFT_TLCState_Fog m1 : 38|3@1+ (1,0) [0|0] "" Vector__XXX
 SG_ VCLEFT_TLCState_Stop m1 : 35|3@1+ (1,0) [0|0] "" Vector__XXX
 SG_ VCLEFT_TLCState_Tail m1 : 32|3@1+ (1,0) [0|0] "" Vector__XXX
 SG_ VCLEFT_TLCStopCurrent m0 : 32|8@1+ (0.1,0) [0|0] "" Vector__XXX
 SG_ VCLEFT_TLCState_RightTurn m1 : 29|3@1+ (1,0) [0|0] "" Vector__XXX
 SG_ VCLEFT_TLCState_LeftTurn m1 : 26|3@1+ (1,0) [0|0] "" Vector__XXX
 SG_ VCLEFT_TLCTailCurrent m0 : 24|8@1+ (0.1,0) [0|0] "" Vector__XXX
 SG_ VCLEFT_TLCRightTurnVoltage m1 : 18|8@1+ (0.1,0) [0|0] "" Vector__XXX
 SG_ VCLEFT_TLCRightTurnCurrent m0 : 16|8@1+ (0.1,0) [0|0] "" Vector__XXX
 SG_ VCLEFT_TLCLeftTurnVoltage m1 : 10|8@1+ (0.1,0) [0|0] "" Vector__XXX
 SG_ VCLEFT_TLCLeftTurnCurrent m0 : 8|8@1+ (0.1,0) [0|0] "" Vector__XXX
 SG_ VCLEFT_TLCTemperature m1 : 2|8@1- (1,68) [0|0] "" Vector__XXX
 SG_ VCLEFT_TLCStatusIndex M : 0|2@1+ (1,0) [0|0] "" Vector__XXX

BO_ 513 VCFRONT_loggingAndVitals10Hz: 8 Vector__XXX
 SG_ VCFRONT_frunkSwitchGroupState m1 : 62|2@1+ (1,0) [0|0] "" Vector__XXX
 SG_ VCFRONT_ccrExvState m3 : 59|4@1+ (1,0) [0|0] "" Vector__XXX
 SG_ VCFRONT_recircExvState m2 : 59|4@1+ (1,0) [0|0] "" Vector__XXX
 SG_ VCFRONT_frunkStateDBG m1 : 58|4@1+ (1,0) [0|0] "" Vector__XXX
 SG_ VCFRONT_thermalHvPowerBudget m0 : 57|7@1+ (0.2,0) [0|0] "" Vector__XXX
 SG_ VCFRONT_compSleepRequest m0 : 56|1@1+ (1,0) [0|0] "" Vector__XXX
 SG_ VCFRONT_cclExvState m3 : 55|4@1+ (1,0) [0|0] "" Vector__XXX
 SG_ VCFRONT_compLiqPumpOutState m1 : 55|3@1+ (1,0) [0|0] "" Vector__XXX
 SG_ VCFRONT_evapExvState m2 : 55|4@1+ (1,0) [0|0] "" Vector__XXX
 SG_ VCFRONT_hpReqTransScavenge m1 : 54|1@1+ (1,0) [0|0] "" Vector__XXX
 SG_ VCFRONT_chillerExvState m2 : 51|4@1+ (1,0) [0|0] "" Vector__XXX
 SG_ VCFRONT_hpReqCoolantMode m1 : 51|3@1+ (1,0) [0|0] "" Vector__XXX
 SG_ VCFRONT_lccExvState m3 : 51|4@1+ (1,0) [0|0] "" Vector__XXX
 SG_ VCFRONT_hpBatteryLoadType m1 : 49|2@1+ (1,0) [0|0] "" Vector__XXX
 SG_ VCFRONT_hpCabinLoadType m1 : 47|2@1+ (1,0) [0|0] "" Vector__XXX
 SG_ VCFRONT_pressureRefrigLiquid m0 : 47|9@1+ (0.08,0) [0|0] "" Vector__XXX
 SG_ VCFRONT_hpQuietModeEnabled m1 : 46|1@1+ (1,0) [0|0] "" Vector__XXX
 SG_ VCFRONT_hpBlendType m1 : 44|2@1+ (1,0) [0|0] "" Vector__XXX
 SG_ VCFRONT_ccrExvFlow m2 : 43|8@1+ (0.5,0) [0|0] "" Vector__XXX
 SG_ VCFRONT_ccrExvFlowTarget m3 : 43|8@1+ (0.5,0) [0|0] "" Vector__XXX
 SG_ VCFRONT_hpDominantLoad m1 : 41|3@1+ (1,0) [0|0] "" Vector__XXX
 SG_ VCFRONT_activeLouverOpenPosTarg m0 : 40|7@1+ (1,0) [0|0] "" Vector__XXX
 SG_ VCFRONT_hpLowSideHX m1 : 39|2@1+ (1,0) [0|0] "" Vector__XXX
 SG_ VCFRONT_hpHighSideHX m1 : 37|2@1+ (1,0) [0|0] "" Vector__XXX
 SG_ VCFRONT_solenoidEngaged m1 : 36|1@1+ (1,0) [0|0] "" Vector__XXX
 SG_ VCFRONT_cclExvFlow m2 : 35|8@1+ (0.5,0) [0|0] "" Vector__XXX
 SG_ VCFRONT_cclExvFlowTarget m3 : 35|8@1+ (0.5,0) [0|0] "" Vector__XXX
 SG_ VCFRONT_compFaultSeverity m1 : 34|2@1+ (1,0) [0|0] "" Vector__XXX
 SG_ VCFRONT_coolantValveMode m1 : 32|2@1+ (1,0) [0|0] "" Vector__XXX
 SG_ VCFRONT_exvFlowTarget m0 : 32|8@1+ (0.5,0) [0|0] "" Vector__XXX
 SG_ VCFRONT_lccExvFlow m2 : 27|8@1+ (0.5,0) [0|0] "" Vector__XXX
 SG_ VCFRONT_lccExvFlowTarget m3 : 27|8@1+ (0.5,0) [0|0] "" Vector__XXX
 SG_ VCFRONT_compDemandChiller m1 : 25|7@1+ (1,0) [0|0] "" Vector__XXX
 SG_ VCFRONT_radiatorFanRPMActual m0 : 24|8@1+ (40,0) [0|0] "" Vector__XXX
 SG_ VCFRONT_solenoidEvapState m1 : 23|2@1+ (1,0) [0|0] "" Vector__XXX
 SG_ VCFRONT_exvState m1 : 19|4@1+ (1,0) [0|0] "" Vector__XXX
 SG_ VCFRONT_recircExvFlow m2 : 19|8@1+ (0.5,0) [0|0] "" Vector__XXX
 SG_ VCFRONT_recircExvFlowTarget m3 : 19|8@1+ (0.5,0) [0|0] "" Vector__XXX
 SG_ VCFRONT_pumpPowertrainRPMActual m0 : 16|8@1+ (30,0) [0|0] "" Vector__XXX
 SG_ VCFRONT_compDemandEvap m1 : 12|7@1+ (1,0) [0|0] "" Vector__XXX
 SG_ VCFRONT_evapExvFlow m2 : 11|8@1+ (0.5,0) [0|0] "" Vector__XXX
 SG_ VCFRONT_evapExvFlowTarget m3 : 11|8@1+ (0.5,0) [0|0] "" Vector__XXX
 SG_ VCFRONT_compressorState m1 : 10|2@1+ (1,0) [0|0] "" Vector__XXX
 SG_ VCFRONT_pumpBatteryRPMActual m0 : 8|8@1+ (30,0) [0|0] "" Vector__XXX
 SG_ VCFRONT_chillerExvFlow m2 : 3|8@1+ (0.5,0) [0|0] "" Vector__XXX
 SG_ VCFRONT_chillerExvFlowTarget m3 : 3|8@1+ (0.5,0) [0|0] "" Vector__XXX
 SG_ VCFRONT_fanDemand m1 : 3|7@1+ (1,0) [0|0] "" Vector__XXX
 SG_ VCFRONT_loggingAndVitals10HzIndex M : 0|3@1+ (1,0) [0|0] "" Vector__XXX

BO_ 516 PCS_chgStatus: 8 Vector__XXX
 SG_ PCS_dcacBidirectionalAllowed : 61|1@1+ (1,0) [0|0] "" Vector__XXX
 SG_ PCS_hwVariantType : 59|2@1+ (1,0) [0|0] "" Vector__XXX
 SG_ PCS_powerTransferShutdownRequest : 57|2@1+ (1,0) [0|0] "" Vector__XXX
 SG_ PCS_chgPwmEnableLine : 56|1@1+ (1,0) [0|0] "" Vector__XXX
 SG_ PCS_chgPHCLineCurrentRequest : 48|8@1+ (0.1,0) [0|0] "" Vector__XXX
 SG_ PCS_chgPHBLineCurrentRequest : 40|8@1+ (0.1,0) [0|0] "" Vector__XXX
 SG_ PCS_chgPHALineCurrentRequest : 32|8@1+ (0.1,0) [0|0] "" Vector__XXX
 SG_ PCS_chgMaxAcPowerAvailable : 24|8@1+ (0.1,0) [0|0] "" Vector__XXX
 SG_ PCS_chgInstantAcPowerAvailable : 16|8@1+ (0.1,0) [0|0] "" Vector__XXX
 SG_ PCS_chgPHCEnable : 12|1@1+ (1,0) [0|0] "" Vector__XXX
 SG_ PCS_chgHighPowerActive : 11|1@1+ (1,0) [0|0] "" Vector__XXX
 SG_ PCS_hvInletConductorEnergizedAc : 10|1@1+ (1,0) [0|0] "" Vector__XXX
 SG_ PCS_chgPHBEnable : 9|1@1+ (1,0) [0|0] "" Vector__XXX
 SG_ PCS_chgPHAEnable : 8|1@1+ (1,0) [0|0] "" Vector__XXX
 SG_ PCS_gridConfig : 6|2@1+ (1,0) [0|0] "" Vector__XXX
 SG_ PCS_powerTransferStatus : 4|2@1+ (1,0) [0|0] "" Vector__XXX
 SG_ PCS_chgMainState : 0|4@1+ (1,0) [0|0] "" Vector__XXX

BO_ 522 HVP_contactorState: 6 Vector__XXX
 SG_ HVP_fcLinkAllowedToEnergize : 44|2@1+ (1,0) [0|0] "" Vector__XXX
 SG_ HVP_hvilDiag : 40|4@1+ (1,0) [0|0] "" Vector__XXX
 SG_ HVP_pyroTestInProgress : 37|1@1+ (1,0) [0|0] "" Vector__XXX
 SG_ HVP_dcLinkAllowedToEnergize : 36|1@1+ (1,0) [0|0] "" Vector__XXX
 SG_ HVP_packCtrsClosingAllowed : 35|1@1+ (1,0) [0|0] "" Vector__XXX
 SG_ HVP_packCtrsOpenRequested : 34|1@1+ (1,0) [0|0] "" Vector__XXX
 SG_ HVP_packCtrsOpenNowRequested : 33|1@1+ (1,0) [0|0] "" Vector__XXX
 SG_ HVP_packCtrsResetRequestRequired : 32|1@1+ (1,0) [0|0] "" Vector__XXX
 SG_ HVP_packCtrsRequestStatus : 30|2@1+ (1,0) [0|0] "" Vector__XXX
 SG_ HVP_fcCtrsClosingAllowed : 29|1@1+ (1,0) [0|0] "" Vector__XXX
 SG_ HVP_fcCtrsOpenRequested : 28|1@1+ (1,0) [0|0] "" Vector__XXX
 SG_ HVP_fcCtrsOpenNowRequested : 27|1@1+ (1,0) [0|0] "" Vector__XXX
 SG_ HVP_fcCtrsResetRequestRequired : 26|1@1+ (1,0) [0|0] "" Vector__XXX
 SG_ HVP_fcCtrsRequestStatus : 24|2@1+ (1,0) [0|0] "" Vector__XXX
 SG_ HVP_fcContactorSetState : 19|4@1+ (1,0) [0|0] "" Vector__XXX
 SG_ HVP_fcContPositiveState : 16|3@1+ (1,0) [0|0] "" Vector__XXX
 SG_ HVP_contactorsBlocked : 15|1@1+ (1,0) [0|0] "" Vector__XXX
 SG_ HVP_fcContNegativeState : 12|3@1+ (1,0) [0|0] "" Vector__XXX
 SG_ HVP_packContactorSetState : 8|4@1+ (1,0) [0|0] "" Vector__XXX
 SG_ HVP_fcContNegativeAuxOpen : 7|1@1+ (1,0) [0|0] "" Vector__XXX
 SG_ HVP_fcContPositiveAuxOpen : 6|1@1+ (1,0) [0|0] "" Vector__XXX
 SG_ HVP_packContPositiveState : 3|3@1+ (1,0) [0|0] "" Vector__XXX
 SG_ HVP_packContNegativeState : 0|3@1+ (1,0) [0|0] "" Vector__XXX

BO_ 524 VCRIGHT_hvacRequest: 8 Vector__XXX
 SG_ VCRIGHT_hvacEvapEnabledInColdAmbient : 62|1@1+ (1,0) [0|0] "" Vector__XXX
 SG_ VCRIGHT_hvacBlowerRPMActualAP : 57|5@1+ (200,0) [0|0] "" Vector__XXX
 SG_ VCRIGHT_hvacUnavailable : 56|1@1+ (1,0) [0|0] "" Vector__XXX
 SG_ VCRIGHT_hvacPerfTestState : 54|2@1+ (1,0) [0|0] "" Vector__XXX
 SG_ VCRIGHT_hvacHeatingEnabledRight : 53|1@1+ (1,0) [0|0] "" Vector__XXX
 SG_ VCRIGHT_hvacHeatingEnabledLeft : 52|1@1+ (1,0) [0|0] "" Vector__XXX
 SG_ VCRIGHT_tempAmbientRaw : 44|8@1+ (0.5,-40) [0|0] "" Vector__XXX
 SG_ VCRIGHT_evapPerformanceLow : 43|1@1+ (1,0) [0|0] "" Vector__XXX
 SG_ VCRIGHT_hvacPerfTestRunning : 42|1@1+ (1,0) [0|0] "" Vector__XXX
 SG_ VCRIGHT_hvacBlowerSpeedRPMReq : 32|10@1+ (5,0) [0|0] "" Vector__XXX
 SG_ VCRIGHT_tempEvaporatorTarget : 24|8@1+ (0.2,0) [0|0] "" Vector__XXX
 SG_ VCRIGHT_tempEvaporator : 13|11@1+ (0.1,-40) [0|0] "" Vector__XXX
 SG_ VCRIGHT_conditioningRequest : 12|1@1+ (1,0) [0|0] "" Vector__XXX
 SG_ VCRIGHT_hvacEvapEnabled : 11|1@1+ (1,0) [0|0] "" Vector__XXX
 SG_ VCRIGHT_wattsDemandEvap : 0|11@1+ (5,0) [0|0] "" Vector__XXX

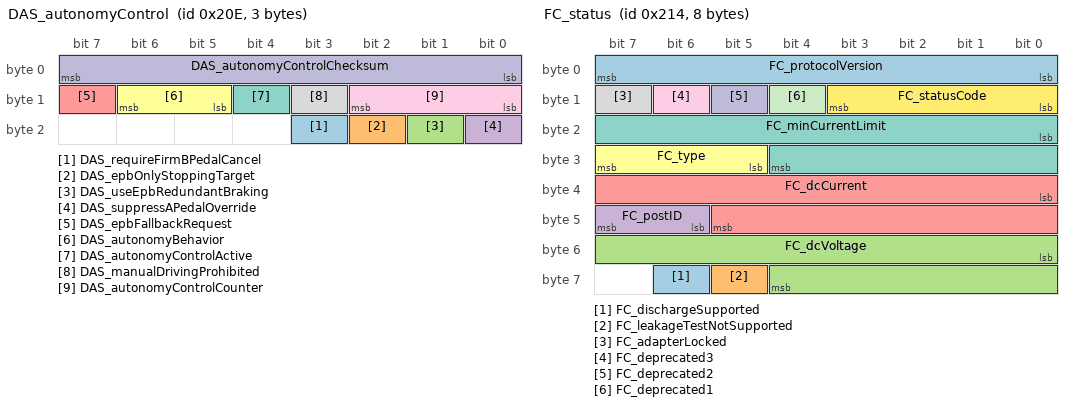
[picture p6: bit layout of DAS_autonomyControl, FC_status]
BO_ 526 DAS_autonomyControl: 3 Vector__XXX
 SG_ DAS_requireFirmBPedalCancel : 19|1@1+ (1,0) [0|0] "" Vector__XXX
 SG_ DAS_epbOnlyStoppingTarget : 18|1@1+ (1,0) [0|0] "" Vector__XXX
 SG_ DAS_useEpbRedundantBraking : 17|1@1+ (1,0) [0|0] "" Vector__XXX
 SG_ DAS_suppressAPedalOverride : 16|1@1+ (1,0) [0|0] "" Vector__XXX
 SG_ DAS_epbFallbackRequest : 15|1@1+ (1,0) [0|0] "" Vector__XXX
 SG_ DAS_autonomyBehavior : 13|2@1+ (1,0) [0|0] "" Vector__XXX
 SG_ DAS_autonomyControlActive : 12|1@1+ (1,0) [0|0] "" Vector__XXX
 SG_ DAS_manualDrivingProhibited : 11|1@1+ (1,0) [0|0] "" Vector__XXX
 SG_ DAS_autonomyControlCounter : 8|3@1+ (1,0) [0|0] "" Vector__XXX
 SG_ DAS_autonomyControlChecksum : 0|8@1+ (1,0) [0|0] "" Vector__XXX

BO_ 529 RCM_status: 6 Vector__XXX
 SG_ RCM_pedProEDR2State : 46|2@1+ (1,0) [0|0] "" Vector__XXX
 SG_ RCM_pedProEDR1State : 44|2@1+ (1,0) [0|0] "" Vector__XXX
 SG_ RCM_occupantClassificationSource : 43|1@1+ (1,0) [0|0] "" Vector__XXX
 SG_ RCM_driverOrientationInitStatus : 40|3@1+ (1,0) [0|0] "" Vector__XXX
 SG_ RCM_edr3State : 38|2@1+ (1,0) [0|0] "" Vector__XXX
 SG_ RCM_imuOffsetLearnState : 36|2@1+ (1,0) [0|0] "" Vector__XXX
 SG_ RCM_keepPowerReason : 32|4@1+ (1,0) [0|0] "" Vector__XXX
 SG_ RCM_edr2State : 30|2@1+ (1,0) [0|0] "" Vector__XXX
 SG_ RCM_edr1State : 28|2@1+ (1,0) [0|0] "" Vector__XXX
 SG_ RCM_seatTrackPositionPass : 26|2@1+ (1,0) [0|0] "" Vector__XXX
 SG_ RCM_seatTrackPositionDrvr : 24|2@1+ (1,0) [0|0] "" Vector__XXX
 SG_ RCM_vinLearnFlag : 22|2@1+ (1,0) [0|0] "" Vector__XXX
 SG_ RCM_alrSwitchStatus : 20|2@1+ (1,0) [0|0] "" Vector__XXX
 SG_ RCM_airbagCutoffStatus : 18|2@1+ (1,0) [0|0] "" Vector__XXX
 SG_ RCM_passAirbagIndicatorRequest : 16|2@1+ (1,0) [0|0] "" Vector__XXX
 SG_ RCM_warningIndicatorState : 14|2@1+ (1,0) [0|0] "" Vector__XXX
 SG_ RCM_armStatus : 12|2@1+ (1,0) [0|0] "" Vector__XXX
 SG_ RCM_statusCounter : 8|4@1+ (1,0) [0|0] "" Vector__XXX
 SG_ RCM_statusChecksum : 0|8@1+ (1,0) [0|0] "" Vector__XXX

BO_ 530 BMS_status: 8 VEH
 SG_ BMS_minPackTemperature : 56|8@1+ (0.5,-40) [0|0] "DegC"  X
 SG_ BMS_ecuLogUploadRequest : 54|2@1+ (1,0) [0|0] ""  X
 SG_ BMS_pcsPwmEnabled : 53|1@1+ (1,0) [0|0] ""  X
 SG_ BMS_chargeRetryCount : 49|4@1+ (1,0) [0|0] ""  X
 SG_ BMS_chgPowerAvailable : 39|12@1+ (0.125,0) [0|0] "kW"  X
 SG_ BMS_okToShipByLand : 37|1@1+ (1,0) [0|0] ""  X
 SG_ BMS_okToShipByAir : 36|1@1+ (1,0) [0|0] ""  X
 SG_ BMS_diLimpRequest : 35|1@1+ (1,0) [0|0] ""  X
 SG_ BMS_uiChargeStatus : 32|3@1+ (1,0) [0|0] ""  X
 SG_ BMS_keepWarmRequest : 30|1@1+ (1,0) [0|0] ""  X
 SG_ BMS_chargeRequest : 29|1@1+ (1,0) [0|0] ""  X
 SG_ BMS_isolationResistance : 19|10@1+ (10,0) [0|0] "kOhm"  X
 SG_ BMS_hvState : 16|3@1+ (1,0) [0|0] ""  X
 SG_ BMS_state : 11|4@1+ (1,0) [0|0] ""  X
 SG_ BMS_contactorState : 8|3@1+ (1,0) [0|0] ""  X
 SG_ BMS_cpMiaOnHvs : 6|1@1+ (1,0) [0|0] ""  X
 SG_ BMS_activeHeatingWorthwhile : 5|1@1+ (1,0) [0|0] ""  X
 SG_ BMS_updateAllowed : 4|1@1+ (1,0) [0|0] ""  X
 SG_ BMS_preconditionAllowed : 3|1@1+ (1,0) [0|0] ""  X
 SG_ BMS_notEnoughPowerForSupport : 2|1@1+ (1,0) [0|0] ""  X
 SG_ BMS_notEnoughPowerForDrive : 1|1@1+ (1,0) [0|0] ""  X
 SG_ BMS_hvacPowerRequest : 0|1@1+ (1,0) [0|0] ""  X

BO_ 531 UI_cruiseControl: 3 VEH
 SG_ UI_cruiseControlChecksum : 16|8@1+ (1,0) [0|0] ""  X
 SG_ UI_cruiseControlCounter : 11|4@1+ (1,0) [0|0] ""  X
 SG_ UI_cruiseSpeedCommand : 8|3@1+ (1,0) [0|0] ""  X
 SG_ UI_speedLimitTick : 0|8@1+ (1,0) [0|0] "speed"  X

BO_ 532 FC_status: 8 Vector__XXX
 SG_ FC_dischargeSupported : 62|1@1+ (1,0) [0|0] "" Vector__XXX
 SG_ FC_leakageTestNotSupported : 61|1@1+ (1,0) [0|0] "" Vector__XXX
 SG_ FC_dcVoltage : 48|13@1+ (0.07324218755,0) [0|0] "" Vector__XXX
 SG_ FC_postID : 46|2@1+ (1,0) [0|0] "" Vector__XXX
 SG_ FC_dcCurrent : 32|14@1- (0.0732421875,0) [0|0] "" Vector__XXX
 SG_ FC_type : 29|3@1+ (1,0) [0|0] "" Vector__XXX
 SG_ FC_minCurrentLimit : 16|13@1+ (0.1,0) [0|0] "" Vector__XXX
 SG_ FC_adapterLocked : 15|1@1+ (1,0) [0|0] "" Vector__XXX
 SG_ FC_deprecated3 : 14|1@1+ (1,0) [0|0] "" Vector__XXX
 SG_ FC_deprecated2 : 13|1@1+ (1,0) [0|0] "" Vector__XXX
 SG_ FC_deprecated1 : 12|1@1+ (1,0) [0|0] "" Vector__XXX
 SG_ FC_statusCode : 8|4@1+ (1,0) [0|0] "" Vector__XXX
 SG_ FC_protocolVersion : 0|8@1+ (1,0) [0|0] "" Vector__XXX

BO_ 533 FC_status2: 1 Vector__XXX
 SG_ FC_externalIsolationResistance : 0|8@1+ (40,0) [0|0] "" Vector__XXX

BO_ 535 FC_status3: 8 Vector__XXX
 SG_ FC_generation m0 : 32|8@1+ (1,0) [0|0] "" Vector__XXX
 SG_ FC_evRelocationRecommended m1 : 29|1@1+ (1,0) [0|0] "" Vector__XXX
 SG_ FC_emergencyShutdownSupported m0 : 28|1@1+ (1,0) [0|0] "" Vector__XXX
 SG_ FC_evseDeratingReason m1 : 24|5@1+ (1,0) [0|0] "" Vector__XXX
 SG_ FC_uiStopType m0 : 24|4@1+ (1,0) [0|0] "" Vector__XXX
 SG_ FC_coolingType m0 : 20|4@1+ (1,0) [0|0] "" Vector__XXX
 SG_ FC_brand m0 : 16|4@1+ (1,0) [0|0] "" Vector__XXX
 SG_ FC_billingEnergy m1 : 8|16@1+ (0.0152590219,0) [0|0] "" Vector__XXX
 SG_ FC_class m0 : 8|8@1+ (1,0) [0|0] "" Vector__XXX
 SG_ FC_status3DummySig : 7|1@1+ (1,0) [0|0] "" Vector__XXX
 SG_ FC_status3DataSelect M : 0|7@1+ (1,0) [0|0] "" Vector__XXX

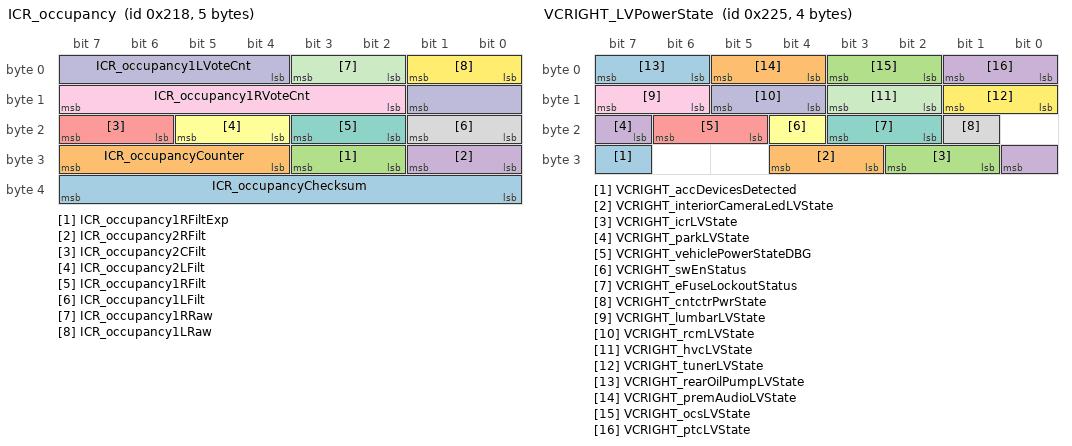
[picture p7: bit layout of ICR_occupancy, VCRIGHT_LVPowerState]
BO_ 536 ICR_occupancy: 5 Vector__XXX
 SG_ ICR_occupancyChecksum : 32|8@1+ (1,0) [0|0] "" Vector__XXX
 SG_ ICR_occupancyCounter : 28|4@1+ (1,0) [0|0] "" Vector__XXX
 SG_ ICR_occupancy1RFiltExp : 26|2@1+ (1,0) [0|0] "" Vector__XXX
 SG_ ICR_occupancy2RFilt : 24|2@1+ (1,0) [0|0] "" Vector__XXX
 SG_ ICR_occupancy2CFilt : 22|2@1+ (1,0) [0|0] "" Vector__XXX
 SG_ ICR_occupancy2LFilt : 20|2@1+ (1,0) [0|0] "" Vector__XXX
 SG_ ICR_occupancy1RFilt : 18|2@1+ (1,0) [0|0] "" Vector__XXX
 SG_ ICR_occupancy1LFilt : 16|2@1+ (1,0) [0|0] "" Vector__XXX
 SG_ ICR_occupancy1RVoteCnt : 10|6@1- (1,0) [0|0] "" Vector__XXX
 SG_ ICR_occupancy1LVoteCnt : 4|6@1- (1,0) [0|0] "" Vector__XXX
 SG_ ICR_occupancy1RRaw : 2|2@1+ (1,0) [0|0] "" Vector__XXX
 SG_ ICR_occupancy1LRaw : 0|2@1+ (1,0) [0|0] "" Vector__XXX

BO_ 537 VCSEC_TPMSData: 7 Vector__XXX
 SG_ VCSEC_TPMSTemperatureCompensatedPressure0 m0 : 43|9@1+ (0.025,0) [0|0] "" Vector__XXX
 SG_ VCSEC_TPMSTemperatureCompensatedPressure1 m1 : 43|9@1+ (0.025,0) [0|0] "" Vector__XXX
 SG_ VCSEC_TPMSTemperatureCompensatedPressure2 m2 : 43|9@1+ (0.025,0) [0|0] "" Vector__XXX
 SG_ VCSEC_TPMSTemperatureCompensatedPressure3 m3 : 43|9@1+ (0.025,0) [0|0] "" Vector__XXX
 SG_ VCSEC_TPMSLastKnownPressureRR m5 : 40|8@1+ (0.025,0) [0|0] "" Vector__XXX
 SG_ VCSEC_TPMSLocation0 m0 : 40|3@1+ (1,0) [0|0] "" Vector__XXX
 SG_ VCSEC_TPMSLocation1 m1 : 40|3@1+ (1,0) [0|0] "" Vector__XXX
 SG_ VCSEC_TPMSLocation2 m2 : 40|3@1+ (1,0) [0|0] "" Vector__XXX
 SG_ VCSEC_TPMSLocation3 m3 : 40|3@1+ (1,0) [0|0] "" Vector__XXX
 SG_ VCSEC_TPMSFeature0TimeS m4 : 36|11@1+ (1,0) [0|0] "" Vector__XXX
 SG_ VCSEC_TPMSBatVoltage0 m0 : 32|8@1+ (0.01,1.5) [0|0] "" Vector__XXX
 SG_ VCSEC_TPMSBatVoltage1 m1 : 32|8@1+ (0.01,1.5) [0|0] "" Vector__XXX
 SG_ VCSEC_TPMSBatVoltage2 m2 : 32|8@1+ (0.01,1.5) [0|0] "" Vector__XXX
 SG_ VCSEC_TPMSBatVoltage3 m3 : 32|8@1+ (0.01,1.5) [0|0] "" Vector__XXX
 SG_ VCSEC_TPMSFeature0Count m4 : 32|4@1+ (1,0) [0|0] "" Vector__XXX
 SG_ VCSEC_TPMSLastKnownPressureRL m5 : 32|8@1+ (0.025,0) [0|0] "" Vector__XXX
 SG_ VCSEC_TPMSFeature1 m4 : 27|3@1+ (1,0) [0|0] "" Vector__XXX
 SG_ VCSEC_TPMSFeature0 m4 : 24|3@1+ (1,0) [0|0] "" Vector__XXX
 SG_ VCSEC_TPMSLastKnownPressureFR m5 : 24|8@1+ (0.025,0) [0|0] "" Vector__XXX
 SG_ VCSEC_TPMSTemperature0 m0 : 24|8@1+ (1,-40) [0|0] "" Vector__XXX
 SG_ VCSEC_TPMSTemperature1 m1 : 24|8@1+ (1,-40) [0|0] "" Vector__XXX
 SG_ VCSEC_TPMSTemperature2 m2 : 24|8@1+ (1,-40) [0|0] "" Vector__XXX
 SG_ VCSEC_TPMSTemperature3 m3 : 24|8@1+ (1,-40) [0|0] "" Vector__XXX
 SG_ VCSEC_TPMSLastKnownPressureFL m5 : 16|8@1+ (0.025,0) [0|0] "" Vector__XXX
 SG_ VCSEC_TPMSRecommendedColdPressureRear m4 : 16|8@1+ (0.025,0) [0|0] "" Vector__XXX
 SG_ VCSEC_TPMSPressure0 m0 : 15|9@1+ (0.025,0) [0|0] "" Vector__XXX
 SG_ VCSEC_TPMSPressure1 m1 : 15|9@1+ (0.025,0) [0|0] "" Vector__XXX
 SG_ VCSEC_TPMSPressure2 m2 : 15|9@1+ (0.025,0) [0|0] "" Vector__XXX
 SG_ VCSEC_TPMSPressure3 m3 : 15|9@1+ (0.025,0) [0|0] "" Vector__XXX
 SG_ VCSEC_TPMSRecommendedColdPressureFront m4 : 8|8@1+ (0.025,0) [0|0] "" Vector__XXX
 SG_ VCSEC_TPMSAutonomyStatusMIATimeS m5 : 5|9@1+ (1,0) [0|0] "" Vector__XXX
 SG_ VCSEC_TPMSPressureRateOfChange0 m0 : 5|10@1- (0.02,0) [0|0] "" Vector__XXX
 SG_ VCSEC_TPMSPressureRateOfChange1 m1 : 5|10@1- (0.02,0) [0|0] "" Vector__XXX
 SG_ VCSEC_TPMSPressureRateOfChange2 m2 : 5|10@1- (0.02,0) [0|0] "" Vector__XXX
 SG_ VCSEC_TPMSPressureRateOfChange3 m3 : 5|10@1- (0.02,0) [0|0] "" Vector__XXX
 SG_ VCSEC_TPMSCapabilityConfigurablePressure0 m0 : 4|1@1+ (1,0) [0|0] "" Vector__XXX
 SG_ VCSEC_TPMSCapabilityConfigurablePressure1 m1 : 4|1@1+ (1,0) [0|0] "" Vector__XXX
 SG_ VCSEC_TPMSCapabilityConfigurablePressure2 m2 : 4|1@1+ (1,0) [0|0] "" Vector__XXX
 SG_ VCSEC_TPMSCapabilityConfigurablePressure3 m3 : 4|1@1+ (1,0) [0|0] "" Vector__XXX
 SG_ VCSEC_TPMSAutonomyStatus m5 : 3|2@1+ (1,0) [0|0] "" Vector__XXX
 SG_ VCSEC_TPMSCapabilityPressureInAdv0 m0 : 3|1@1+ (1,0) [0|0] "" Vector__XXX
 SG_ VCSEC_TPMSCapabilityPressureInAdv1 m1 : 3|1@1+ (1,0) [0|0] "" Vector__XXX
 SG_ VCSEC_TPMSCapabilityPressureInAdv2 m2 : 3|1@1+ (1,0) [0|0] "" Vector__XXX
 SG_ VCSEC_TPMSCapabilityPressureInAdv3 m3 : 3|1@1+ (1,0) [0|0] "" Vector__XXX
 SG_ VCSEC_TPMSDataIndex M : 0|3@1+ (1,0) [0|0] "" Vector__XXX

BO_ 541 CP_evseStatus: 8 Vector__XXX
 SG_ CP_teslaDcState : 58|4@1+ (1,0) [0|0] "" Vector__XXX
 SG_ CP_acChargeType : 56|2@1+ (1,0) [0|0] "" Vector__XXX
 SG_ CP_acChargeState : 52|3@1+ (1,0) [0|0] "" Vector__XXX
 SG_ CP_gbdcChargeAttempts : 50|2@1+ (1,0) [0|0] "" Vector__XXX
 SG_ CP_gbdcFailureReason : 48|2@1+ (1,0) [0|0] "" Vector__XXX
 SG_ CP_gbdcStopChargeReason : 44|4@1+ (1,0) [0|0] "" Vector__XXX
 SG_ CP_gbState : 40|4@1+ (1,0) [0|0] "" Vector__XXX
 SG_ CP_evseChargeType_UI : 38|2@1+ (1,0) [0|0] "" Vector__XXX
 SG_ CP_teslaSwcanState : 34|4@1+ (1,0) [0|0] "" Vector__XXX
 SG_ CP_cableCurrentLimit : 24|7@1+ (1,0) [0|0] "" Vector__XXX
 SG_ CP_plcSupported : 23|1@1+ (1,0) [0|0] "" Vector__XXX
 SG_ CP_iecPilotState : 19|4@1+ (1,0) [0|0] "" Vector__XXX
 SG_ CP_cableType : 16|3@1+ (1,0) [0|0] "" Vector__XXX
 SG_ CP_pilotCurrent : 8|8@1+ (0.5,0) [0|0] "" Vector__XXX
 SG_ CP_digitalCommsEstablished : 7|1@1+ (1,0) [0|0] "" Vector__XXX
 SG_ CP_pilot : 4|3@1+ (1,0) [0|0] "" Vector__XXX
 SG_ CP_proximity : 2|2@1+ (1,0) [0|0] "" Vector__XXX
 SG_ CP_evseRequest : 1|1@1+ (1,0) [0|0] "" Vector__XXX
 SG_ CP_evseAccept : 0|1@1+ (1,0) [0|0] "" Vector__XXX

BO_ 545 VCFRONT_LVPowerState: 8 Vector__XXX
 SG_ VCFRONT_LVPowerStateChecksum : 56|8@1+ (1,0) [0|0] "" Vector__XXX
 SG_ VCFRONT_LVPowerStateCounter : 52|4@1+ (1,0) [0|0] "" Vector__XXX
 SG_ VCFRONT_LVShuttingDown : 51|1@1+ (1,0) [0|0] "" Vector__XXX
 SG_ VCFRONT_inAccessoryPlus : 50|1@1+ (1,0) [0|0] "" Vector__XXX
 SG_ VCFRONT_uiHiCurrentLVState m0 : 48|2@1+ (1,0) [0|0] "" Vector__XXX
 SG_ VCFRONT_vcrightHiCurrentLVState m0 : 46|2@1+ (1,0) [0|0] "" Vector__XXX
 SG_ VC_noAccDeviceDetectedWhileIdle m1 : 46|1@1+ (1,0) [0|0] "" Vector__XXX
 SG_ VCFRONT_vcleftHiCurrentLVState m0 : 44|2@1+ (1,0) [0|0] "" Vector__XXX
 SG_ VCFRONT_ocsLVRequest m0 : 42|2@1+ (1,0) [0|0] "" Vector__XXX
 SG_ VC_persistAccPortPowerState m1 : 41|3@1+ (1,0) [0|0] "" Vector__XXX
 SG_ VCFRONT_oilPumpRearLVRequest m0 : 40|2@1+ (1,0) [0|0] "" Vector__XXX
 SG_ VC_accPortPowerRequest m1 : 40|1@1+ (1,0) [0|0] "" Vector__XXX
 SG_ VC_persistAccPowerRequestOverridden m1 : 39|1@1+ (1,0) [0|0] "" Vector__XXX
 SG_ VCFRONT_oilPumpFrontLVState m0 : 38|2@1+ (1,0) [0|0] "" Vector__XXX
 SG_ VCFRONT_difLVState m0 : 36|2@1+ (1,0) [0|0] "" Vector__XXX
 SG_ VCFRONT_dirLVRequest m0 : 34|2@1+ (1,0) [0|0] "" Vector__XXX
 SG_ VC_autonomyBehavior m1 : 34|2@1+ (1,0) [0|0] "" Vector__XXX
 SG_ VCFRONT_das2HighCurrentLVState m0 : 32|2@1+ (1,0) [0|0] "" Vector__XXX
 SG_ VC_hvStateRequest m1 : 31|3@1+ (1,0) [0|0] "" Vector__XXX
 SG_ VCFRONT_das1HighCurrentLVState m0 : 30|2@1+ (1,0) [0|0] "" Vector__XXX
 SG_ VC_dcdcSupportRequest m1 : 30|1@1+ (1,0) [0|0] "" Vector__XXX
 SG_ VCFRONT_MCUGraphicsLVState m1 : 28|2@1+ (1,0) [0|0] "" Vector__XXX
 SG_ VCFRONT_amplifierLVRequest m0 : 28|2@1+ (1,0) [0|0] "" Vector__XXX
 SG_ VCFRONT_espValveLVState m1 : 26|2@1+ (1,0) [0|0] "" Vector__XXX
 SG_ VCFRONT_tunerLVRequest m0 : 26|2@1+ (1,0) [0|0] "" Vector__XXX
 SG_ VCFRONT_MCUAudioLVState m1 : 24|2@1+ (1,0) [0|0] "" Vector__XXX
 SG_ VCFRONT_iBoosterLVState m0 : 24|2@1+ (1,0) [0|0] "" Vector__XXX
 SG_ VCFRONT_hcmrLVState m1 : 22|2@1+ (1,0) [0|0] "" Vector__XXX
 SG_ VCFRONT_rcmLVRequest m0 : 22|2@1+ (1,0) [0|0] "" Vector__XXX
 SG_ VCFRONT_hcmlLVState m1 : 20|2@1+ (1,0) [0|0] "" Vector__XXX
 SG_ VCFRONT_tpmsLVRequest m0 : 20|2@1+ (1,0) [0|0] "" Vector__XXX
 SG_ VCFRONT_CMPDLVState m1 : 18|2@1+ (1,0) [0|0] "" Vector__XXX
 SG_ VCFRONT_sccmLVRequest m0 : 18|2@1+ (1,0) [0|0] "" Vector__XXX
 SG_ VCFRONT_pcsLVState m1 : 16|2@1+ (1,0) [0|0] "" Vector__XXX
 SG_ VCFRONT_ptcLVRequest m0 : 16|2@1+ (1,0) [0|0] "" Vector__XXX
 SG_ VCFRONT_hvacCompLVState m0 : 14|2@1+ (1,0) [0|0] "" Vector__XXX
 SG_ VCFRONT_tasLVState m1 : 14|2@1+ (1,0) [0|0] "" Vector__XXX
 SG_ VCFRONT_hvcLVRequest m1 : 12|2@1+ (1,0) [0|0] "" Vector__XXX
 SG_ VCFRONT_radcLVState m0 : 12|2@1+ (1,0) [0|0] "" Vector__XXX
 SG_ VCFRONT_epasLVState m1 : 10|2@1+ (1,0) [0|0] "" Vector__XXX
 SG_ VCFRONT_espLVState m0 : 10|2@1+ (1,0) [0|0] "" Vector__XXX
 SG_ VCFRONT_cpLVRequest m1 : 8|2@1+ (1,0) [0|0] "" Vector__XXX
 SG_ VCFRONT_parkLVState m0 : 8|2@1+ (1,0) [0|0] "" Vector__XXX
 SG_ VCFRONT_vehiclePowerState : 5|2@1+ (1,0) [0|0] "" Vector__XXX
 SG_ VCFRONT_LVPowerStateIndex M : 0|5@1+ (1,0) [0|0] "" Vector__XXX

BO_ 548 PCS_dcdcStatus: 8 Vector__XXX
 SG_ PCS_dcdcInitialPrechargeSubState : 59|5@1+ (1,0) [0|0] "" Vector__XXX
 SG_ PCS_dcdcPrechargeRestartCnt : 56|3@1+ (1,0) [0|0] "" Vector__XXX
 SG_ PCS_ecuLogUploadRequest : 54|2@1+ (1,0) [0|0] "" Vector__XXX
 SG_ PCS_dcdcSupportingFixedLvTarget : 53|1@1+ (1,0) [0|0] "" Vector__XXX
 SG_ PCS_dcdcPwmEnableLine : 52|1@1+ (1,0) [0|0] "" Vector__XXX
 SG_ PCS_dcdcDischargeRtyCnt : 48|4@1+ (1,0) [0|0] "" Vector__XXX
 SG_ PCS_dcdcLvSupportRtyCnt : 44|4@1+ (1,0) [0|0] "" Vector__XXX
 SG_ PCS_dcdcPrechargeRtyCnt : 41|3@1+ (1,0) [0|0] "" Vector__XXX
 SG_ PCS_dcdcMaxOutputCurrentAllowed : 29|12@1+ (0.1,0) [0|0] "" Vector__XXX
 SG_ PCS_dcdcOutputIsLimited : 28|1@1+ (1,0) [0|0] "" Vector__XXX
 SG_ PCS_okToBePowerCycled : 27|1@1+ (1,0) [0|0] "" Vector__XXX
 SG_ PCS_dcdcFaulted : 15|1@1+ (1,0) [0|0] "" Vector__XXX
 SG_ PCS_dcdcSubState : 10|5@1+ (1,0) [0|0] "" Vector__XXX
 SG_ PCS_dcdcPchgHVBusLowRDetected : 9|1@1+ (1,0) [0|0] "" Vector__XXX
 SG_ PCS_coldSleepAllowed : 8|1@1+ (1,0) [0|0] "" Vector__XXX
 SG_ PCS_dcdcHvBusDischargeStatus : 4|2@1+ (1,0) [0|0] "" Vector__XXX
 SG_ PCS_dcdcLvSupportStatus : 2|2@1+ (1,0) [0|0] "" Vector__XXX
 SG_ PCS_dcdcPrechargeStatus : 0|2@1+ (1,0) [0|0] "" Vector__XXX

BO_ 549 VCRIGHT_LVPowerState: 4 Vector__XXX
 SG_ VCRIGHT_accDevicesDetected : 31|1@1+ (1,0) [0|0] "" Vector__XXX
 SG_ VCRIGHT_interiorCameraLedLVState : 27|2@1+ (1,0) [0|0] "" Vector__XXX
 SG_ VCRIGHT_icrLVState : 25|2@1+ (1,0) [0|0] "" Vector__XXX
 SG_ VCRIGHT_parkLVState : 23|2@1+ (1,0) [0|0] "" Vector__XXX
 SG_ VCRIGHT_vehiclePowerStateDBG : 21|2@1+ (1,0) [0|0] "" Vector__XXX
 SG_ VCRIGHT_swEnStatus : 20|1@1+ (1,0) [0|0] "" Vector__XXX
 SG_ VCRIGHT_eFuseLockoutStatus : 18|2@1+ (1,0) [0|0] "" Vector__XXX
 SG_ VCRIGHT_cntctrPwrState : 17|1@1+ (1,0) [0|0] "" Vector__XXX
 SG_ VCRIGHT_lumbarLVState : 14|2@1+ (1,0) [0|0] "" Vector__XXX
 SG_ VCRIGHT_rcmLVState : 12|2@1+ (1,0) [0|0] "" Vector__XXX
 SG_ VCRIGHT_hvcLVState : 10|2@1+ (1,0) [0|0] "" Vector__XXX
 SG_ VCRIGHT_tunerLVState : 8|2@1+ (1,0) [0|0] "" Vector__XXX
 SG_ VCRIGHT_rearOilPumpLVState : 6|2@1+ (1,0) [0|0] "" Vector__XXX
 SG_ VCRIGHT_premAudioLVState : 4|2@1+ (1,0) [0|0] "" Vector__XXX
 SG_ VCRIGHT_ocsLVState : 2|2@1+ (1,0) [0|0] "" Vector__XXX
 SG_ VCRIGHT_ptcLVState : 0|2@1+ (1,0) [0|0] "" Vector__XXX

BO_ 552 EPBR_internalStatus: 8 Vector__XXX
 SG_ EPBR_internalStatusChecksum : 56|8@1+ (1,0) [0|0] "" Vector__XXX
 SG_ EPBR_internalStatusCounter : 52|4@1+ (1,0) [0|0] "" Vector__XXX
 SG_ EPBR_learnedEpbConfig : 48|4@1+ (1,0) [0|0] "" Vector__XXX
 SG_ EPBR_esmSpeedClass : 45|3@1+ (1,0) [0|0] "" Vector__XXX
 SG_ EPBR_internalCDPRequest : 44|1@1+ (1,0) [0|0] "" Vector__XXX
 SG_ EPBR_driverIsLeavingAnySpeedLocal : 43|1@1+ (1,0) [0|0] "" Vector__XXX
 SG_ EPBR_driverIsLeavingLocal : 42|1@1+ (1,0) [0|0] "" Vector__XXX
 SG_ EPBR_telltaleLocal : 39|3@1+ (1,0) [0|0] "" Vector__XXX
 SG_ EPBR_chimeRequestLocal : 33|3@1+ (1,0) [0|0] "" Vector__XXX
 SG_ EPBR_localCdpState : 30|2@1+ (1,0) [0|0] "" Vector__XXX
 SG_ EPBR_localServiceModeActive : 29|1@1+ (1,0) [0|0] "" Vector__XXX
 SG_ EPBR_summonFaultReason : 24|5@1+ (1,0) [0|0] "" Vector__XXX
 SG_ EPBR_esmOperationTrigger : 18|6@1+ (1,0) [0|0] "" Vector__XXX
 SG_ EPBR_csmFaultReason : 13|5@1+ (1,0) [0|0] "" Vector__XXX
 SG_ EPBR_pistonTouchingRotor : 12|1@1+ (1,0) [0|0] "" Vector__XXX
 SG_ EPBR_disconnected : 11|1@1+ (1,0) [0|0] "" Vector__XXX
 SG_ EPBR_summonState : 8|3@1+ (1,0) [0|0] "" Vector__XXX
 SG_ EPBR_unitFaultStatus : 5|2@1+ (1,0) [0|0] "" Vector__XXX
 SG_ EPBR_unitStatus : 0|5@1+ (1,0) [0|0] "" Vector__XXX

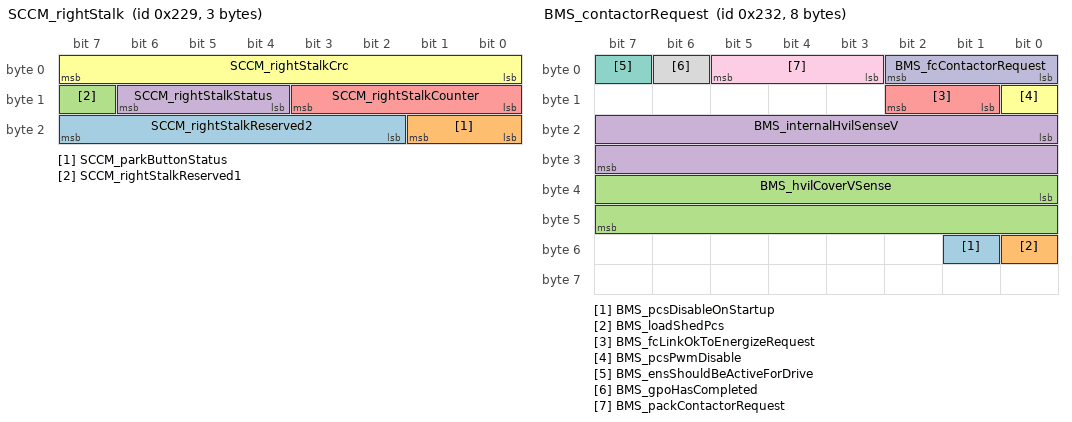
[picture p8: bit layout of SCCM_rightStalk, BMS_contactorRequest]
BO_ 553 SCCM_rightStalk: 3 Vector__XXX
 SG_ SCCM_rightStalkReserved2 : 18|6@1+ (1,0) [0|0] "" Vector__XXX
 SG_ SCCM_parkButtonStatus : 16|2@1+ (1,0) [0|0] "" Vector__XXX
 SG_ SCCM_rightStalkReserved1 : 15|1@1+ (1,0) [0|0] "" Vector__XXX
 SG_ SCCM_rightStalkStatus : 12|3@1+ (1,0) [0|0] "" Vector__XXX
 SG_ SCCM_rightStalkCounter : 8|4@1+ (1,0) [0|0] "" Vector__XXX
 SG_ SCCM_rightStalkCrc : 0|8@1+ (1,0) [0|0] "" Vector__XXX

BO_ 554 HVP_hvsControl: 4 Vector__XXX
 SG_ HVP_dcLinkVoltageFiltered : 20|11@1- (1,0) [0|0] "" Vector__XXX
 SG_ HVP_pcsDcdcHwEnabled : 19|1@1+ (1,0) [0|0] "" Vector__XXX
 SG_ HVP_pcsChargeHwEnabled : 18|1@1+ (1,0) [0|0] "" Vector__XXX
 SG_ HVP_pcsControlRequest : 16|2@1+ (1,0) [0|0] "" Vector__XXX
 SG_ HVP_dcLinkVoltageRequest : 0|16@1- (0.1,0) [0|0] "" Vector__XXX

BO_ 555 DAS_matrixHighBeamRequest: 8 Vector__XXX
 SG_ DAS_azimuthSegmentLightRequests : 0|64@1+ (1,0) [0|0] "" Vector__XXX

BO_ 562 BMS_contactorRequest: 8 Vector__XXX
 SG_ BMS_pcsDisableOnStartup : 49|1@1+ (1,0) [0|0] "" Vector__XXX
 SG_ BMS_loadShedPcs : 48|1@1+ (1,0) [0|0] "" Vector__XXX
 SG_ BMS_hvilCoverVSense : 32|16@1+ (0.001,0) [0|0] "" Vector__XXX
 SG_ BMS_internalHvilSenseV : 16|16@1+ (0.001,0) [0|0] "" Vector__XXX
 SG_ BMS_fcLinkOkToEnergizeRequest : 9|2@1+ (1,0) [0|0] "" Vector__XXX
 SG_ BMS_pcsPwmDisable : 8|1@1+ (1,0) [0|0] "" Vector__XXX
 SG_ BMS_ensShouldBeActiveForDrive : 7|1@1+ (1,0) [0|0] "" Vector__XXX
 SG_ BMS_gpoHasCompleted : 6|1@1+ (1,0) [0|0] "" Vector__XXX
 SG_ BMS_packContactorRequest : 3|3@1+ (1,0) [0|0] "" Vector__XXX
 SG_ BMS_fcContactorRequest : 0|3@1+ (1,0) [0|0] "" Vector__XXX

BO_ 564 DCDC_power: 8 Vector__XXX
 SG_ DCDC_powerChecksum : 56|8@1+ (1,0) [0|0] "" Vector__XXX
 SG_ DCDC_powerCounter : 52|4@1+ (1,0) [0|0] "" Vector__XXX
 SG_ DCDC_powerMuxIndex M : 50|2@1+ (1,0) [0|0] "" Vector__XXX
 SG_ DCDC_type m0 : 45|2@1+ (1,0) [0|0] "" Vector__XXX
 SG_ DCDC_auxiliaryStageSaturationWarning m0 : 44|1@1+ (1,0) [0|0] "" Vector__XXX
 SG_ DCDC_packSideContLvOutputPowerLimit m1 : 40|10@1+ (10,0) [0|0] "" Vector__XXX
 SG_ DCDC_instantLvOutputPowerLimit m0 : 34|10@1+ (10,0) [0|0] "" Vector__XXX
 SG_ DCDC_minTargetContLvOutputPowerLimit m1 : 30|10@1+ (10,0) [0|0] "" Vector__XXX
 SG_ DCDC_continuousLvOutputPowerLimit m0 : 24|10@1+ (10,0) [0|0] "" Vector__XXX
 SG_ DCDC_severeOvLvInputPowerLimit m1 : 20|10@1+ (10,0) [0|0] "" Vector__XXX
 SG_ DCDC_filteredLvOutputPowerEstimated m0 : 12|12@1- (10,0) [0|0] "" Vector__XXX
 SG_ DCDC_severeUvLvOutputPowerLimit m1 : 10|10@1+ (10,0) [0|0] "" Vector__XXX
 SG_ DCDC_instantLvOutputPowerEstimated m0 : 0|12@1- (10,0) [0|0] "" Vector__XXX
 SG_ DCDC_transientLvOutputPowerLimit m1 : 0|10@1+ (10,0) [0|0] "" Vector__XXX

BO_ 568 UI_driverAssistMapData: 8 Vector__XXX
 SG_ UI_mapDataChecksum : 56|8@1+ (1,0) [0|0] "" Vector__XXX
 SG_ UI_mapDataCounter : 52|4@1+ (1,0) [0|0] "" Vector__XXX
 SG_ UI_scaEnabled : 51|1@1+ (1,0) [0|0] "" Vector__XXX
 SG_ UI_pmmEnabled : 50|1@1+ (1,0) [0|0] "" Vector__XXX
 SG_ UI_autosteerRestricted : 49|1@1+ (1,0) [0|0] "" Vector__XXX
 SG_ UI_acceptBottsDots : 48|1@1+ (1,0) [0|0] "" Vector__XXX
 SG_ UI_rejectHandsOn : 47|1@1+ (1,0) [0|0] "" Vector__XXX
 SG_ UI_rejectAutosteer : 46|1@1+ (1,0) [0|0] "" Vector__XXX
 SG_ UI_rejectRightFreeSpace : 45|1@1+ (1,0) [0|0] "" Vector__XXX
 SG_ UI_rejectLeftFreeSpace : 44|1@1+ (1,0) [0|0] "" Vector__XXX
 SG_ UI_rejectNav : 43|1@1+ (1,0) [0|0] "" Vector__XXX
 SG_ UI_rejectHPP : 42|1@1+ (1,0) [0|0] "" Vector__XXX
 SG_ UI_rejectRightLane : 41|1@1+ (1,0) [0|0] "" Vector__XXX
 SG_ UI_rejectLeftLane : 40|1@1+ (1,0) [0|0] "" Vector__XXX
 SG_ UI_nextBranchRightOffRamp : 39|1@1+ (1,0) [0|0] "" Vector__XXX
 SG_ UI_nextBranchLeftOffRamp : 38|1@1+ (1,0) [0|0] "" Vector__XXX
 SG_ UI_controlledAccess : 37|1@1+ (1,0) [0|0] "" Vector__XXX
 SG_ UI_nextBranchDist : 32|5@1+ (10,0) [0|0] "" Vector__XXX
 SG_ UI_perpendicularAutoparkEnabled : 31|1@1+ (1,0) [0|0] "" Vector__XXX
 SG_ UI_parallelAutoparkEnabled : 30|1@1+ (1,0) [0|0] "" Vector__XXX
 SG_ UI_navRouteActive : 29|1@1+ (1,0) [0|0] "" Vector__XXX
 SG_ UI_gpsRoadMatch : 28|1@1+ (1,0) [0|0] "" Vector__XXX
 SG_ UI_streetCount : 26|2@1+ (1,0) [0|0] "" Vector__XXX
 SG_ UI_countryCode : 16|10@1+ (1,0) [0|0] "" Vector__XXX
 SG_ UI_mapSpeedLimitType : 13|3@1+ (1,0) [0|0] "" Vector__XXX
 SG_ UI_mapSpeedLimit : 8|5@1+ (1,0) [0|0] "" Vector__XXX
 SG_ UI_mapSpeedUnits : 7|1@1+ (1,0) [0|0] "" Vector__XXX
 SG_ UI_inSuperchargerGeofence : 6|1@1+ (1,0) [0|0] "" Vector__XXX
 SG_ UI_roadClass : 3|3@1+ (1,0) [0|0] "" Vector__XXX
 SG_ UI_mapSpeedLimitDependency : 0|3@1+ (1,0) [0|0] "" Vector__XXX

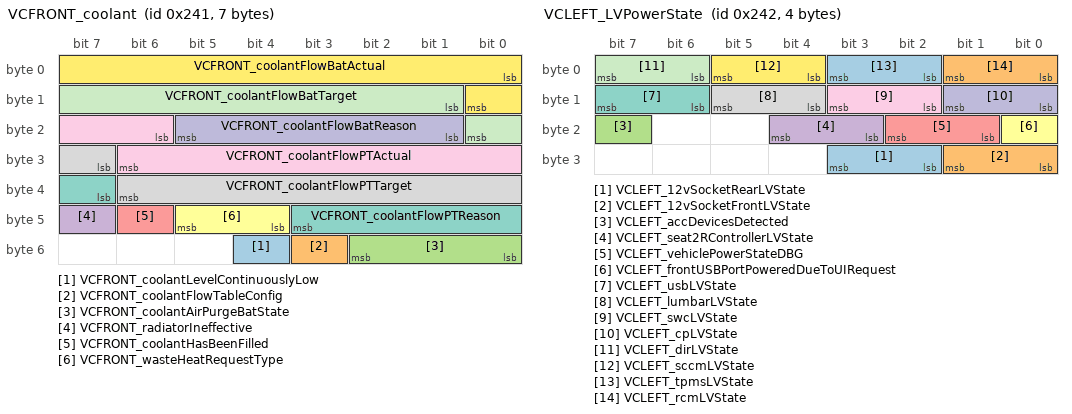
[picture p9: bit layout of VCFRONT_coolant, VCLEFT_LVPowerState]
BO_ 577 VCFRONT_coolant: 7 Vector__XXX
 SG_ VCFRONT_coolantLevelContinuouslyLow : 52|1@1+ (1,0) [0|0] "" Vector__XXX
 SG_ VCFRONT_coolantFlowTableConfig : 51|1@1+ (1,0) [0|0] "" Vector__XXX
 SG_ VCFRONT_coolantAirPurgeBatState : 48|3@1+ (1,0) [0|0] "" Vector__XXX
 SG_ VCFRONT_radiatorIneffective : 47|1@1+ (1,0) [0|0] "" Vector__XXX
 SG_ VCFRONT_coolantHasBeenFilled : 46|1@1+ (1,0) [0|0] "" Vector__XXX
 SG_ VCFRONT_wasteHeatRequestType : 44|2@1+ (1,0) [0|0] "" Vector__XXX
 SG_ VCFRONT_coolantFlowPTReason : 39|5@1+ (1,0) [0|0] "" Vector__XXX
 SG_ VCFRONT_coolantFlowPTTarget : 31|8@1+ (0.2,0) [0|0] "" Vector__XXX
 SG_ VCFRONT_coolantFlowPTActual : 22|9@1+ (0.1,0) [0|0] "" Vector__XXX
 SG_ VCFRONT_coolantFlowBatReason : 17|5@1+ (1,0) [0|0] "" Vector__XXX
 SG_ VCFRONT_coolantFlowBatTarget : 9|8@1+ (0.2,0) [0|0] "" Vector__XXX
 SG_ VCFRONT_coolantFlowBatActual : 0|9@1+ (0.1,0) [0|0] "" Vector__XXX

BO_ 578 VCLEFT_LVPowerState: 4 Vector__XXX
 SG_ VCLEFT_12vSocketRearLVState : 26|2@1+ (1,0) [0|0] "" Vector__XXX
 SG_ VCLEFT_12vSocketFrontLVState : 24|2@1+ (1,0) [0|0] "" Vector__XXX
 SG_ VCLEFT_accDevicesDetected : 23|1@1+ (1,0) [0|0] "" Vector__XXX
 SG_ VCLEFT_seat2RControllerLVState : 19|2@1+ (1,0) [0|0] "" Vector__XXX
 SG_ VCLEFT_vehiclePowerStateDBG : 17|2@1+ (1,0) [0|0] "" Vector__XXX
 SG_ VCLEFT_frontUSBPortPoweredDueToUIRequest : 16|1@1+ (1,0) [0|0] "" Vector__XXX
 SG_ VCLEFT_usbLVState : 14|2@1+ (1,0) [0|0] "" Vector__XXX
 SG_ VCLEFT_lumbarLVState : 12|2@1+ (1,0) [0|0] "" Vector__XXX
 SG_ VCLEFT_swcLVState : 10|2@1+ (1,0) [0|0] "" Vector__XXX
 SG_ VCLEFT_cpLVState : 8|2@1+ (1,0) [0|0] "" Vector__XXX
 SG_ VCLEFT_dirLVState : 6|2@1+ (1,0) [0|0] "" Vector__XXX
 SG_ VCLEFT_sccmLVState : 4|2@1+ (1,0) [0|0] "" Vector__XXX
 SG_ VCLEFT_tpmsLVState : 2|2@1+ (1,0) [0|0] "" Vector__XXX
 SG_ VCLEFT_rcmLVState : 0|2@1+ (1,0) [0|0] "" Vector__XXX

BO_ 579 VCRIGHT_hvacStatus: 8 Vector__XXX
 SG_ VCRIGHT_hvacOverheatProtActive m3 : 63|1@1+ (1,0) [0|0] "" Vector__XXX
 SG_ VCRIGHT_hvacModelInitStatus m0 : 60|4@1+ (1,0) [0|0] "" Vector__XXX
 SG_ VCRIGHT_extendedHvacPerfTestSupportState m2 : 59|4@1+ (1,0) [0|0] "" Vector__XXX
 SG_ VCRIGHT_hvacLimitedReasonLeft m3 : 59|3@1+ (1,0) [0|0] "" Vector__XXX
 SG_ VCRIGHT_hvacSystemNominal m0 : 59|1@1+ (1,0) [0|0] "" Vector__XXX
 SG_ VCRIGHT_hvacDuctTargetRight m1 : 56|8@1+ (0.5,-40) [0|0] "" Vector__XXX
 SG_ VCRIGHT_hvacLimitedReasonRight m3 : 56|3@1+ (1,0) [0|0] "" Vector__XXX
 SG_ VCRIGHT_hvacSecondRowState m0 : 56|3@1+ (1,0) [0|0] "" Vector__XXX
 SG_ VCRIGHT_tempDuctRightLower m4 : 56|8@1+ (0.5,-22) [0|0] "" Vector__XXX
 SG_ VCRIGHT_hvacVentStatus m0 : 54|2@1+ (1,0) [0|0] "" Vector__XXX
 SG_ VCRIGHT_windshieldCameraHeaterDutyRequest m2 : 54|5@1+ (5,0) [0|0] "" Vector__XXX
 SG_ VCRIGHT_hvacRefHighPowerRequest m2 : 53|1@1+ (1,0) [0|0] "" Vector__XXX
 SG_ VCRIGHT_hvacPowerState m0 : 51|3@1+ (1,0) [0|0] "" Vector__XXX
 SG_ VCRIGHT_hvacACRunning m0 : 50|1@1+ (1,0) [0|0] "" Vector__XXX
 SG_ VCRIGHT_hvacDuctTargetLeft m1 : 48|8@1+ (0.5,-40) [0|0] "" Vector__XXX
 SG_ VCRIGHT_hvacRecirc m0 : 48|2@1+ (1,0) [0|0] "" Vector__XXX
 SG_ VCRIGHT_minsToSunset m3 : 48|8@1+ (10,0) [0|0] "" Vector__XXX
 SG_ VCRIGHT_refrigDistCommanded m2 : 48|1@1+ (1,0) [0|0] "" Vector__XXX
 SG_ VCRIGHT_tempDuctLeftLower m4 : 48|8@1+ (0.5,-22) [0|0] "" Vector__XXX
 SG_ VCRIGHT_hvacBlowerSegment m0 : 44|4@1+ (1,0) [0|0] "" Vector__XXX
 SG_ VCRIGHT_hvacAirDistributionMode m0 : 41|3@1+ (1,0) [0|0] "" Vector__XXX
 SG_ VCRIGHT_minsToSunrise m3 : 40|8@1+ (10,0) [0|0] "" Vector__XXX
 SG_ VCRIGHT_solarLoadOnVehicle m2 : 40|8@1+ (4,0) [0|0] "" Vector__XXX
 SG_ VCRIGHT_autoHvacBlowerShouldLimit m2 : 37|1@1+ (1,0) [0|0] "" Vector__XXX
 SG_ VCRIGHT_hvacQdotRight m4 : 34|14@1+ (1,-8191) [0|0] "" Vector__XXX
 SG_ VCRIGHT_blowerTorqueIndex m5 : 32|7@1+ (1,0) [0|0] "" Vector__XXX
 SG_ VCRIGHT_hvacAirflowReason m2 : 32|5@1+ (1,0) [0|0] "" Vector__XXX
 SG_ VCRIGHT_tempDuctRight m1 : 32|8@1+ (0.5,-22) [0|0] "" Vector__XXX
 SG_ VCRIGHT_solarElevation m3 : 31|9@1- (0.5,0) [0|0] "" Vector__XXX
 SG_ VCRIGHT_hvacCabinAtTempTarget m2 : 30|1@1+ (1,0) [0|0] "" Vector__XXX
 SG_ VCRIGHT_hvacCabinTempEst m0 : 30|11@1+ (0.1,-40) [0|0] "" Vector__XXX
 SG_ VCRIGHT_tempMonitorNotNominal m2 : 29|1@1+ (1,0) [0|0] "" Vector__XXX
 SG_ VCRIGHT_COPNotRunningReasonFiltered m0 : 27|3@1+ (1,0) [0|0] "" Vector__XXX
 SG_ VCRIGHT_autoDefogStatus m3 : 26|2@1+ (1,0) [0|0] "" Vector__XXX
 SG_ VCRIGHT_hvacCabinTempEstValid m0 : 26|1@1+ (1,0) [0|0] "" Vector__XXX
 SG_ VCRIGHT_hvacMassflowRefrigSystem m1 : 24|8@1+ (1,0) [0|0] "" Vector__XXX
 SG_ VCRIGHT_steeringWheelHeatStatus m3 : 24|2@1+ (1,0) [0|0] "" Vector__XXX
 SG_ VCRIGHT_dogModeState m0 : 22|4@1+ (1,0) [0|0] "" Vector__XXX
 SG_ VCRIGHT_hvacRequestsAutoIntake m3 : 22|1@1+ (1,0) [0|0] "" Vector__XXX
 SG_ VCRIGHT_passengerPresentHvacCycle m3 : 21|1@1+ (1,0) [0|0] "" Vector__XXX
 SG_ VCRIGHT_childModeHVACState m0 : 20|2@1+ (1,0) [0|0] "" Vector__XXX
 SG_ VCRIGHT_hvacQdotLeft m4 : 20|14@1+ (1,-8191) [0|0] "" Vector__XXX
 SG_ VCRIGHT_hvacEvapInletTempEstimate m2 : 19|10@1+ (0.13,-40) [0|0] "" Vector__XXX
 SG_ VCRIGHT_hpSplitTempsEnabled m2 : 18|1@1+ (1,0) [0|0] "" Vector__XXX
 SG_ VCRIGHT_hvacFrontLeftSeatHeatStatus m4 : 18|2@1+ (1,0) [0|0] "" Vector__XXX
 SG_ VCRIGHT_hvacRequestsFullAuto m3 : 17|3@1+ (1,0) [0|0] "" Vector__XXX
 SG_ VCRIGHT_tempDuctLeft m1 : 16|8@1+ (0.5,-22) [0|0] "" Vector__XXX
 SG_ VCRIGHT_coolingDownStatus m0 : 15|5@1+ (3,7) [0|0] "" Vector__XXX
 SG_ VCRIGHT_hvacManualToAutoNotify m3 : 14|3@1+ (1,0) [0|0] "" Vector__XXX
 SG_ VCRIGHT_hvacRecircDoorPercent m1 : 10|6@1+ (1.6,0) [0|0] "" Vector__XXX
 SG_ VCRIGHT_tempDuctLeftUpper m4 : 10|8@1+ (0.5,-22) [0|0] "" Vector__XXX
 SG_ VCRIGHT_tempDuctRightUpper m2 : 10|8@1+ (0.5,-22) [0|0] "" Vector__XXX
 SG_ VCRIGHT_warmingUpStatus m0 : 10|5@1+ (3,7) [0|0] "" Vector__XXX
 SG_ VCRIGHT_autoSwingAvailable m4 : 9|1@1+ (1,0) [0|0] "" Vector__XXX
 SG_ VCRIGHT_enableTripleCameraFanPowerInSleep m2 : 9|1@1+ (1,0) [0|0] "" Vector__XXX
 SG_ VCRIGHT_foggingControllerResetReason m5 : 9|15@1+ (1,0) [0|0] "" Vector__XXX
 SG_ VCRIGHT_hvacSeatFrontLeftTempTarget m3 : 6|8@1+ (0.5,-40) [0|0] "" Vector__XXX
 SG_ VCRIGHT_hvacFrontRightSeatHeatStatus m3 : 4|2@1+ (1,0) [0|0] "" Vector__XXX
 SG_ VCRIGHT_hvacStatusIndex M : 0|3@1+ (1,0) [0|0] "" Vector__XXX

BO_ 580 FC_limits: 8 Vector__XXX
 SG_ FC_minVoltageLimit : 48|13@1+ (0.0732421875,0) [0|0] "" Vector__XXX
 SG_ FC_maxVoltageLimit : 32|13@1+ (0.07324218755,0) [0|0] "" Vector__XXX
 SG_ FC_currentLimit : 16|13@1+ (0.0732421875,0) [0|0] "" Vector__XXX
 SG_ FC_powerLimit : 0|13@1+ (0.062255859376,0) [0|0] "" Vector__XXX

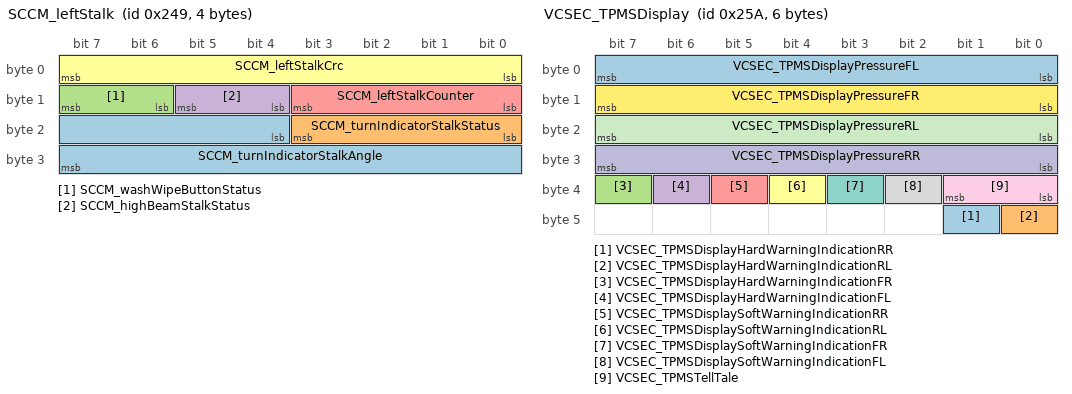
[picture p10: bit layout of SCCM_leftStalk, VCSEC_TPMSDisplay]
BO_ 585 SCCM_leftStalk: 4 Vector__XXX
 SG_ SCCM_turnIndicatorStalkAngle : 20|12@1+ (0.1,-180) [0|0] "" Vector__XXX
 SG_ SCCM_turnIndicatorStalkStatus : 16|4@1+ (1,0) [0|0] "" Vector__XXX
 SG_ SCCM_washWipeButtonStatus : 14|2@1+ (1,0) [0|0] "" Vector__XXX
 SG_ SCCM_highBeamStalkStatus : 12|2@1+ (1,0) [0|0] "" Vector__XXX
 SG_ SCCM_leftStalkCounter : 8|4@1+ (1,0) [0|0] "" Vector__XXX
 SG_ SCCM_leftStalkCrc : 0|8@1+ (1,0) [0|0] "" Vector__XXX

BO_ 586 HVP_cpControl: 1 Vector__XXX
 SG_ HVP_cpFaultLine : 2|1@1+ (1,0) [0|0] "" Vector__XXX
 SG_ HVP_cpLatchDriveHwEnabled : 1|1@1+ (1,0) [0|0] "" Vector__XXX
 SG_ HVP_cpDoorDriveEnable : 0|1@1+ (1,0) [0|0] "" Vector__XXX

BO_ 594 BMS_powerAvailable: 8 VEH
 SG_ BMS_inverterTQF : 56|2@1+ (1,0) [0|3] ""  X
 SG_ BMS_hvacPowerBudget : 50|10@1+ (0.02,0) [0|0] "kW"  X
 SG_ BMS_powerLimitsState : 48|1@1+ (1,0) [0|0] ""  X
 SG_ BMS_maxStationaryHeatPower : 32|10@1+ (0.01,0) [0|0] "kW"  X
 SG_ BMS_maxDischargePower : 16|16@1+ (0.01,0) [0|0] "kW"  X
 SG_ BMS_maxRegenPower : 0|16@1+ (0.01,0) [0|0] "kW"  X

BO_ 595 UI_ventPanelControlRequest: 8 Vector__XXX
 SG_ UI_hvacReqActiveVents m0 : 60|2@1+ (1,0) [0|0] "" Vector__XXX
 SG_ UI_ventPanelRightLateralMode m0 : 58|2@1+ (1,0) [0|0] "" Vector__XXX
 SG_ UI_ventPanelLeftLateralMode m0 : 56|2@1+ (1,0) [0|0] "" Vector__XXX
 SG_ UI_ventPanelRightLateralSplit m0 : 48|8@1+ (0.5,0) [0|0] "" Vector__XXX
 SG_ UI_ventPanelRightPositionY m0 : 40|8@1+ (0.5,0) [0|0] "" Vector__XXX
 SG_ UI_ventPanelRightPositionX m0 : 32|8@1+ (0.5,0) [0|0] "" Vector__XXX
 SG_ UI_ventPanelLeftLateralSplit m0 : 24|8@1+ (0.5,0) [0|0] "" Vector__XXX
 SG_ UI_ventPanelLeftPositionY m0 : 16|8@1+ (0.5,0) [0|0] "" Vector__XXX
 SG_ UI_ventPanelLeftPositionX m0 : 8|8@1+ (0.5,0) [0|0] "" Vector__XXX
 SG_ UI_ventPanelControlRequestIndex M : 0|1@1+ (1,0) [0|0] "" Vector__XXX

BO_ 599 DI_speed: 8 VEH
 SG_ DI_uiSpeedUnits : 32|1@1+ (1,0) [0|0] ""  X
 SG_ DI_uiSpeed : 24|8@1+ (1,0) [0|0] ""  X
 SG_ DI_vehicleSpeed : 12|12@1+ (0.08,-40) [0|0] "kph"  X
 SG_ DI_speedCounter : 8|4@1+ (1,0) [0|0] ""  X
 SG_ DI_speedChecksum : 0|8@1+ (1,0) [0|0] ""  X

BO_ 602 VCSEC_TPMSDisplay: 6 Vector__XXX
 SG_ VCSEC_TPMSDisplayHardWarningIndicationRR : 41|1@1+ (1,0) [0|0] "" Vector__XXX
 SG_ VCSEC_TPMSDisplayHardWarningIndicationRL : 40|1@1+ (1,0) [0|0] "" Vector__XXX
 SG_ VCSEC_TPMSDisplayHardWarningIndicationFR : 39|1@1+ (1,0) [0|0] "" Vector__XXX
 SG_ VCSEC_TPMSDisplayHardWarningIndicationFL : 38|1@1+ (1,0) [0|0] "" Vector__XXX
 SG_ VCSEC_TPMSDisplaySoftWarningIndicationRR : 37|1@1+ (1,0) [0|0] "" Vector__XXX
 SG_ VCSEC_TPMSDisplaySoftWarningIndicationRL : 36|1@1+ (1,0) [0|0] "" Vector__XXX
 SG_ VCSEC_TPMSDisplaySoftWarningIndicationFR : 35|1@1+ (1,0) [0|0] "" Vector__XXX
 SG_ VCSEC_TPMSDisplaySoftWarningIndicationFL : 34|1@1+ (1,0) [0|0] "" Vector__XXX
 SG_ VCSEC_TPMSTellTale : 32|2@1+ (1,0) [0|0] "" Vector__XXX
 SG_ VCSEC_TPMSDisplayPressureRR : 24|8@1+ (0.025,0) [0|0] "" Vector__XXX
 SG_ VCSEC_TPMSDisplayPressureRL : 16|8@1+ (0.025,0) [0|0] "" Vector__XXX
 SG_ VCSEC_TPMSDisplayPressureFR : 8|8@1+ (0.025,0) [0|0] "" Vector__XXX
 SG_ VCSEC_TPMSDisplayPressureFL : 0|8@1+ (0.025,0) [0|0] "" Vector__XXX

BO_ 603 APP_status: 8 Vector__XXX
 SG_ APP_statusChecksum : 56|8@1+ (1,0) [0|0] "" Vector__XXX
 SG_ APP_statusCounter : 52|4@1+ (1,0) [0|0] "" Vector__XXX
 SG_ APP_suspendResumeAvailable : 51|1@1+ (1,0) [0|0] "" Vector__XXX
 SG_ APP_uiEthFailoverDisabled : 50|1@1+ (1,0) [0|0] "" Vector__XXX
 SG_ APP_autonomySystemHealth : 49|1@1+ (1,0) [0|0] "" Vector__XXX
 SG_ APP_autoparkVersionIdentifier : 47|2@1+ (1,0) [0|0] "" Vector__XXX
 SG_ APP_sentryState : 44|3@1+ (1,0) [0|0] "" Vector__XXX
 SG_ APP_summonVersionIdentifier : 42|2@1+ (1,0) [0|0] "" Vector__XXX
 SG_ APP_socOperatingMode : 40|2@1+ (1,0) [0|0] "" Vector__XXX
 SG_ APP_DDAWSystemStatus : 37|3@1+ (1,0) [0|0] "" Vector__XXX
 SG_ APP_sendingBUCStream : 35|1@1+ (1,0) [0|0] "" Vector__XXX
 SG_ APP_unifiedObjectStackSupported : 33|2@1+ (1,0) [0|0] "" Vector__XXX
 SG_ APP_excessiveAccelPedalWarning : 32|1@1+ (1,0) [0|0] "" Vector__XXX
 SG_ APP_fsdRevokeCount : 29|3@1+ (1,0) [0|0] "" Vector__XXX
 SG_ APP_teslaVisionUnsupportedReason : 26|3@1+ (1,0) [0|0] "" Vector__XXX
 SG_ APP_teslaVisionSupported : 24|2@1+ (1,0) [0|0] "" Vector__XXX
 SG_ APP_fsdRevokeStrikeoutCount : 21|3@1+ (1,0) [0|0] "" Vector__XXX
 SG_ APP_fsdSuspendState : 19|2@1+ (1,0) [0|0] "" Vector__XXX
 SG_ APP_summonUnavailableReason : 14|5@1+ (1,0) [0|0] "" Vector__XXX
 SG_ APP_allowApActivationWithBrake : 13|1@1+ (1,0) [0|0] "" Vector__XXX
 SG_ APP_clipRecordingStatus : 10|3@1+ (1,0) [0|0] "" Vector__XXX
 SG_ APP_factorySummonStatus : 6|4@1+ (1,0) [0|0] "" Vector__XXX
 SG_ APP_cameraHeaterRequest : 5|1@1+ (1,0) [0|0] "" Vector__XXX
 SG_ APP_fusedState : 3|2@1+ (1,0) [0|0] "" Vector__XXX
 SG_ APP_watchdogState : 0|3@1+ (1,0) [0|0] "" Vector__XXX

BO_ 605 CP_status: 8 Vector__XXX
 SG_ CP_evseGridFormHardwareType : 44|4@1+ (1,0) [0|0] "" Vector__XXX
 SG_ CP_userEvseModelType : 40|4@1+ (1,0) [0|0] "" Vector__XXX
 SG_ CP_inletHeaterUiState : 37|3@1+ (1,0) [0|0] "" Vector__XXX
 SG_ CP_latchEngaged : 34|1@1+ (1,0) [0|0] "" Vector__XXX
 SG_ CP_coldWeatherMode : 33|1@1+ (1,0) [0|0] "" Vector__XXX
 SG_ CP_vehicleUnlockRequest : 32|1@1+ (1,0) [0|0] "" Vector__XXX
 SG_ CP_chargeDoorOpenUI : 31|1@1+ (1,0) [0|0] "" Vector__XXX
 SG_ CP_inductiveSensorState : 28|3@1+ (1,0) [0|0] "" Vector__XXX
 SG_ CP_doorPresenceState : 25|3@1+ (1,0) [0|0] "" Vector__XXX
 SG_ CP_faultLineSensed : 24|1@1+ (1,0) [0|0] "" Vector__XXX
 SG_ CP_UHF_handleFound : 23|1@1+ (1,0) [0|0] "" Vector__XXX
 SG_ CP_ledColor : 19|4@1+ (1,0) [0|0] "" Vector__XXX
 SG_ CP_latchControlState : 16|3@1+ (1,0) [0|0] "" Vector__XXX
 SG_ CP_chargeCableState : 14|2@1+ (1,0) [0|0] "" Vector__XXX
 SG_ CP_inhibitOta : 13|1@1+ (1,0) [0|0] "" Vector__XXX
 SG_ CP_swcanRelayClosed : 12|1@1+ (1,0) [0|0] "" Vector__XXX
 SG_ CP_doorButtonPressed : 11|1@1+ (1,0) [0|0] "" Vector__XXX
 SG_ CP_doorControlState : 8|3@1+ (1,0) [0|0] "" Vector__XXX
 SG_ CP_chargeDoorOpen : 6|1@1+ (1,0) [0|0] "" Vector__XXX
 SG_ CP_permanentPowerRequest : 5|1@1+ (1,0) [0|0] "" Vector__XXX
 SG_ CP_latchState : 3|2@1+ (1,0) [0|0] "" Vector__XXX
 SG_ CP_insertEnableLine : 2|1@1+ (1,0) [0|0] "" Vector__XXX
 SG_ CP_type : 0|2@1+ (1,0) [0|0] "" Vector__XXX

BO_ 609 VCFRONT_12VBatteryStatus: 8 Vector__XXX
 SG_ VCFRONT_12VBatteryStatusChecksum : 56|8@1+ (1,0) [0|0] "" Vector__XXX
 SG_ VCFRONT_12VBatteryStatusCounter : 52|4@1+ (1,0) [0|0] "" Vector__XXX
 SG_ VCFRONT_LVBatterySPICommsDetectedDBG m4 : 51|1@1+ (1,0) [0|0] "" Vector__XXX
 SG_ VCFRONT_goodTemp12VforUpdate m1 : 51|1@1+ (1,0) [0|0] "" Vector__XXX
 SG_ VCFRONT_opportunisticDCRTestNeeded m3 : 51|1@1+ (1,0) [0|0] "" Vector__XXX
 SG_ VCFRONT_resistanceEstimationNeeded m2 : 51|1@1+ (1,0) [0|0] "" Vector__XXX
 SG_ VCFRONT_LVBatteryCannotSupportVehicle m1 : 50|1@1+ (1,0) [0|0] "" Vector__XXX
 SG_ VCFRONT_LVBatteryFctryLimOverrideOk m4 : 50|1@1+ (1,0) [0|0] "" Vector__XXX
 SG_ VCFRONT_goodLVChargeForUpdate m3 : 50|1@1+ (1,0) [0|0] "" Vector__XXX
 SG_ VCFRONT_LVBatterySupported m1 : 49|1@1+ (1,0) [0|0] "" Vector__XXX
 SG_ VCFRONT_resistanceEstimationTestsExpended m3 : 49|1@1+ (1,0) [0|0] "" Vector__XXX
 SG_ VCFRONT_LVBatteryType m2 : 48|3@1+ (1,0) [0|0] "" Vector__XXX
 SG_ VCFRONT_resistanceEstimationTestValid m3 : 48|1@1+ (1,0) [0|0] "" Vector__XXX
 SG_ VCFRONT_reverseBatteryFault m1 : 48|1@1+ (1,0) [0|0] "" Vector__XXX
 SG_ VCFRONT_voltageFloorReachedCounter m0 : 48|4@1+ (1,0) [0|0] "" Vector__XXX
 SG_ VCFRONT_LVLoadRequest : 47|1@1+ (1,0) [0|0] "" Vector__XXX
 SG_ VCFRONT_good12VforUpdate : 46|1@1+ (1,0) [0|0] "" Vector__XXX
 SG_ VCFRONT_LVBusControlsFutile m3 : 45|1@1+ (1,0) [0|0] "" Vector__XXX
 SG_ VCFRONT_firstChargePOR m0 : 45|1@1+ (1,0) [0|0] "" Vector__XXX
 SG_ VCFRONT_LVBatteryStatusForDrive m2 : 44|2@1+ (1,0) [0|0] "" Vector__XXX
 SG_ VCFRONT_firstChargeOTA m0 : 44|1@1+ (1,0) [0|0] "" Vector__XXX
 SG_ VCFRONT_LVBusControlMode m4 : 41|4@1+ (1,0) [0|0] "" Vector__XXX
 SG_ VCFRONT_goodForPCSPowerCycleLeakyBktDBG m3 : 40|5@1+ (0.0005,0) [0|0] "" Vector__XXX
 SG_ VCFRONT_LVBatteryEnergyRemainingPCT m2 : 37|7@1+ (1,0) [0|0] "" Vector__XXX
 SG_ VCFRONT_voltageSensorMismatchLeakyBktPctDBG m4 : 34|7@1+ (2,0) [0|0] "" Vector__XXX
 SG_ VCFRONT_LVBatteryLINCommsDetectedDBG m4 : 33|1@1+ (1,0) [0|0] "" Vector__XXX
 SG_ VCFRONT_IBSVoltage m1 : 32|14@1+ (0.005443676098,0) [0|0] "" Vector__XXX
 SG_ VCFRONT_silentWakeIBSCurrent m0 : 32|12@1+ (0.125,-511.875) [0|0] "" Vector__XXX
 SG_ VCFRONT_currentControlLoopIntegrationVal m5 : 30|14@1+ (0.006,0) [0|0] "" Vector__XXX
 SG_ VCFRONT_currentSensorMismatchLeakyBktPctDBG m2 : 27|7@1+ (2,0) [0|0] "" Vector__XXX
 SG_ VCFRONT_LVBatterySupportRqrdTrigger m3 : 24|14@1+ (1,0) [0|0] "" Vector__XXX
 SG_ VCFRONT_IBSVoltageRawDBG m4 : 19|14@1+ (0.005443676098,0) [0|0] "" Vector__XXX
 SG_ VCFRONT_LVBMS_LVPackCurrentSourceDBG m3 : 19|2@1+ (1,0) [0|0] "" Vector__XXX
 SG_ VCFRONT_LVBMS_LVBusVoltageSourceDBG m3 : 17|2@1+ (1,0) [0|0] "" Vector__XXX
 SG_ VCFRONT_IBSCurrent m1 : 16|16@1- (0.005,0) [0|0] "" Vector__XXX
 SG_ VCFRONT_IBSCurrentFiltered m0 : 16|16@1- (0.005,0) [0|0] "" Vector__XXX
 SG_ VCFRONT_IBSTemperature m2 : 16|11@1+ (0.1,-24) [0|0] "" Vector__XXX
 SG_ VCFRONT_voltageControlLoopIntegrationVal m5 : 16|14@1+ (0.006,0) [0|0] "" Vector__XXX
 SG_ VCFRONT_chargeNeeded m5 : 15|1@1+ (1,0) [0|0] "" Vector__XXX
 SG_ VCFRONT_PCSMia m5 : 14|1@1+ (1,0) [0|0] "" Vector__XXX
 SG_ VCFRONT_resistanceEstimationTestCounter m1 : 14|2@1+ (1,0) [0|0] "" Vector__XXX
 SG_ VCFRONT_shortedCellFaultCounter m0 : 13|3@1+ (1,0) [0|0] "" Vector__XXX
 SG_ VCFRONT_isVehicleSupported m0 : 12|1@1+ (1,0) [0|0] "" Vector__XXX
 SG_ VCFRONT_batteryLINScheduleDBG m1 : 11|3@1+ (1,0) [0|0] "" Vector__XXX
 SG_ VCFRONT_eFuseRecoveryStateDBG m1 : 8|3@1+ (1,0) [0|0] "" Vector__XXX
 SG_ VCFRONT_voltageDropCounter m0 : 8|4@1+ (1,0) [0|0] "" Vector__XXX
 SG_ VCFRONT_IBSAmpHours m4 : 5|14@1- (0.005,0) [0|0] "" Vector__XXX
 SG_ VCFRONT_12VOverchargeCounter m0 : 4|4@1+ (1,0) [0|0] "" Vector__XXX
 SG_ VCFRONT_batterySMState m1 : 4|4@1+ (1,0) [0|0] "" Vector__XXX
 SG_ VCFRONT_12VBatteryTargetVoltage m2 : 3|13@1+ (0.01,0) [0|0] "" Vector__XXX
 SG_ VCFRONT_IBSFault m0 : 3|1@1+ (1,0) [0|0] "" Vector__XXX
 SG_ VCFRONT_IBSVoltageFiltered m3 : 3|14@1+ (0.005443676098,0) [0|0] "" Vector__XXX
 SG_ VCFRONT_batterySupportRequest m1 : 3|1@1+ (1,0) [0|0] "" Vector__XXX
 SG_ VCFRONT_targetCurrent m5 : 3|11@1+ (0.125,-127) [0|0] "" Vector__XXX
 SG_ VCFRONT_voltageProfile m4 : 3|2@1+ (1,0) [0|0] "" Vector__XXX
 SG_ VCFRONT_12VBatteryStatusIndex M : 0|3@1+ (1,0) [0|0] "" Vector__XXX

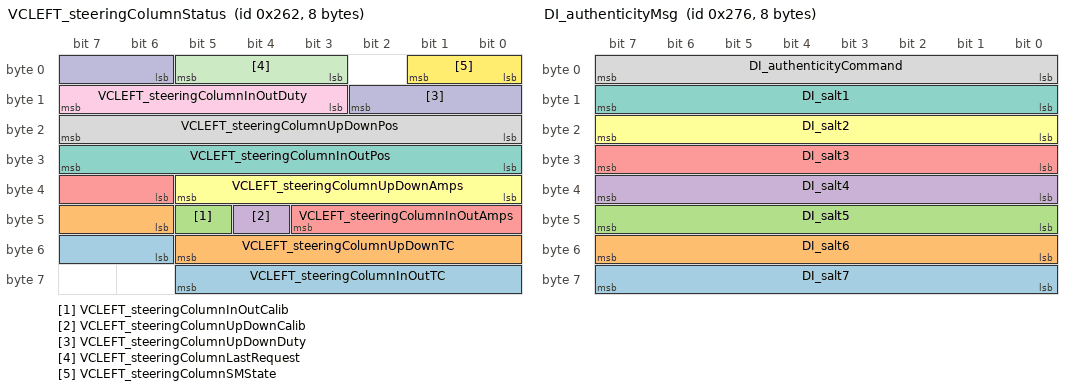
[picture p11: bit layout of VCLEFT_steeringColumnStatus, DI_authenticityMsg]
BO_ 610 VCLEFT_steeringColumnStatus: 8 Vector__XXX
 SG_ VCLEFT_steeringColumnInOutTC : 54|8@1+ (0.5,-10) [0|0] "" Vector__XXX
 SG_ VCLEFT_steeringColumnUpDownTC : 46|8@1+ (0.5,-10) [0|0] "" Vector__XXX
 SG_ VCLEFT_steeringColumnInOutCalib : 45|1@1+ (1,0) [0|0] "" Vector__XXX
 SG_ VCLEFT_steeringColumnUpDownCalib : 44|1@1+ (1,0) [0|0] "" Vector__XXX
 SG_ VCLEFT_steeringColumnInOutAmps : 38|6@1- (0.63,0) [0|0] "" Vector__XXX
 SG_ VCLEFT_steeringColumnUpDownAmps : 32|6@1- (0.63,0) [0|0] "" Vector__XXX
 SG_ VCLEFT_steeringColumnInOutPos : 24|8@1- (1,103) [0|0] "" Vector__XXX
 SG_ VCLEFT_steeringColumnUpDownPos : 16|8@1- (1,103) [0|0] "" Vector__XXX
 SG_ VCLEFT_steeringColumnInOutDuty : 11|5@1- (7,0) [0|0] "" Vector__XXX
 SG_ VCLEFT_steeringColumnUpDownDuty : 6|5@1- (7,0) [0|0] "" Vector__XXX
 SG_ VCLEFT_steeringColumnLastRequest : 3|3@1+ (1,0) [0|0] "" Vector__XXX
 SG_ VCLEFT_steeringColumnSMState : 0|2@1+ (1,0) [0|0] "" Vector__XXX

BO_ 611 VCRIGHT_logging10Hz: 8 Vector__XXX
 SG_ VCRIGHT_ptcHeaterBadRodDetectionState m2 : 56|4@1+ (1,0) [0|0] "" Vector__XXX
 SG_ VCRIGHT_windshieldRHExteriorSurface m3 : 56|8@1+ (1,0) [0|0] "" Vector__XXX
 SG_ VCRIGHT_hvacIntakePosition m1 : 53|8@1+ (0.4,0) [0|0] "" Vector__XXX
 SG_ VCRIGHT_hvacIntakeTarget m0 : 53|8@1+ (0.4,0) [0|0] "" Vector__XXX
 SG_ VCRIGHT_tempDuctRightEst m2 : 48|8@1+ (0.5,-22) [0|0] "" Vector__XXX
 SG_ VCRIGHT_hvacLowerModePosition m1 : 45|8@1+ (0.4,0) [0|0] "" Vector__XXX
 SG_ VCRIGHT_hvacLowerModeTarget m0 : 45|8@1+ (0.4,0) [0|0] "" Vector__XXX
 SG_ VCRIGHT_frontRightSeatTempTargetQuasiSS m4 : 42|6@1+ (1,20) [0|0] "" Vector__XXX
 SG_ VCRIGHT_tempDuctLeftEst m2 : 40|8@1+ (0.5,-22) [0|0] "" Vector__XXX
 SG_ VCRIGHT_frontLeftSeatTempTargetQuasiSS m4 : 36|6@1+ (0.75,20) [0|0] "" Vector__XXX
 SG_ VCRIGHT_hvacUpperModePosition m1 : 35|10@1+ (0.1,0) [0|0] "" Vector__XXX
 SG_ VCRIGHT_hvacUpperModeTarget m0 : 35|10@1+ (0.1,0) [0|0] "" Vector__XXX
 SG_ VCRIGHT_tempDatRightEst m2 : 30|9@1+ (0.5,-22) [0|0] "" Vector__XXX
 SG_ VCRIGHT_hvacRHVanePosition m1 : 27|8@1+ (0.4,0) [0|0] "" Vector__XXX
 SG_ VCRIGHT_hvacRHVaneTarget m0 : 27|8@1+ (0.4,0) [0|0] "" Vector__XXX
 SG_ VCRIGHT_tempDatLeftEst m2 : 21|9@1+ (0.5,-22) [0|0] "" Vector__XXX
 SG_ VCRIGHT_EvapPulldownBiasActive m2 : 20|1@1+ (1,0) [0|0] "" Vector__XXX
 SG_ VCRIGHT_hvacLHVanePosition m1 : 19|8@1+ (0.4,0) [0|0] "" Vector__XXX
 SG_ VCRIGHT_hvacLHVaneTarget m0 : 19|8@1+ (0.4,0) [0|0] "" Vector__XXX
 SG_ VCRIGHT_hvacIntakeActuatorState m2 : 16|2@1+ (1,0) [0|0] "" Vector__XXX
 SG_ VCRIGHT_hvacLowerModeActState m2 : 14|2@1+ (1,0) [0|0] "" Vector__XXX
 SG_ VCRIGHT_hvacUpperModeActState m2 : 12|2@1+ (1,0) [0|0] "" Vector__XXX
 SG_ VCRIGHT_hvacRHBleedPosition m1 : 11|8@1+ (0.4,0) [0|0] "" Vector__XXX
 SG_ VCRIGHT_hvacRHBleedTarget m0 : 11|8@1+ (0.4,0) [0|0] "" Vector__XXX
 SG_ VCRIGHT_hvacRHVaneActuatorState m2 : 10|2@1+ (1,0) [0|0] "" Vector__XXX
 SG_ VCRIGHT_hvacLHVaneActuatorState m2 : 8|2@1+ (1,0) [0|0] "" Vector__XXX
 SG_ VCRIGHT_hvacRHBleedActuatorState m2 : 5|2@1+ (1,0) [0|0] "" Vector__XXX
 SG_ VCRIGHT_hvacLHBleedActuatorState m2 : 3|2@1+ (1,0) [0|0] "" Vector__XXX
 SG_ VCRIGHT_hvacLHBleedPosition m1 : 3|8@1+ (0.4,0) [0|0] "" Vector__XXX
 SG_ VCRIGHT_hvacLHBleedTarget m0 : 3|8@1+ (0.4,0) [0|0] "" Vector__XXX
 SG_ VCRIGHT_logging10HzIndex M : 0|3@1+ (1,0) [0|0] "" Vector__XXX

BO_ 612 PCS_chgLineStatus: 6 Vector__XXX
 SG_ PCS_chgAcCurrentLimit : 32|10@1+ (0.1,0) [0|0] "" Vector__XXX
 SG_ PCS_chgInputPower : 24|8@1+ (0.1,0) [0|0] "" Vector__XXX
 SG_ PCS_chgAcVoltagePresent : 23|1@1+ (1,0) [0|0] "" Vector__XXX
 SG_ PCS_chgLineCurrent : 14|9@1+ (0.1,0) [0|0] "" Vector__XXX
 SG_ PCS_chgInputVoltage : 0|14@1+ (0.033,0) [0|0] "" Vector__XXX

BO_ 614 DIR_power: 8 Vector__XXX
 SG_ DIR_drivePowerMax : 48|9@1+ (1,0) [0|0] "" Vector__XXX
 SG_ DIR_excessHeatCommand : 40|8@1+ (0.08,0) [0|0] "" Vector__XXX
 SG_ DIR_heatPowerActual : 32|8@1+ (0.08,0) [0|0] "" Vector__XXX
 SG_ DIR_heatPowerMax : 24|8@1+ (0.08,0) [0|0] "" Vector__XXX
 SG_ DIR_heatPowerOptimal : 16|8@1+ (0.08,0) [0|0] "" Vector__XXX
 SG_ DIR_elecPower : 0|11@1- (0.5,0) [0|0] "" Vector__XXX

BO_ 616 DI_systemPower: 5 Vector__XXX
 SG_ DI_sysRegenPowerMax : 32|8@1+ (1,-100) [0|0] "" Vector__XXX
 SG_ DI_primaryUnitSiliconType : 26|1@1+ (1,0) [0|0] "" Vector__XXX
 SG_ DI_sysDrivePowerMax : 16|10@1+ (1,0) [0|0] "" Vector__XXX
 SG_ DI_sysHeatPowerActual : 8|8@1+ (0.08,0) [0|0] "" Vector__XXX
 SG_ DI_sysHeatPowerMax : 0|8@1+ (0.08,0) [0|0] "" Vector__XXX

BO_ 626 VCLEFT_epbmDebug: 8 Vector__XXX
 SG_ VCLEFT_epbmAutonomyBehavior m0 : 62|2@1+ (1,0) [0|0] "" Vector__XXX
 SG_ VCLEFT_epbmSystemStatus m0 : 58|4@1+ (1,0) [0|0] "" Vector__XXX
 SG_ VCLEFT_epbFaultStatus m0 : 56|2@1+ (1,0) [0|0] "" Vector__XXX
 SG_ VCLEFT_epbmFaultStatus m0 : 54|2@1+ (1,0) [0|0] "" Vector__XXX
 SG_ VCLEFT_epbUnitStatus m0 : 49|5@1+ (1,0) [0|0] "" Vector__XXX
 SG_ VCLEFT_epbmSummonState m0 : 46|3@1+ (1,0) [0|0] "" Vector__XXX
 SG_ VCLEFT_epbSummonState m0 : 43|3@1+ (1,0) [0|0] "" Vector__XXX
 SG_ VCLEFT_summonFaultReason m0 : 38|5@1+ (1,0) [0|0] "" Vector__XXX
 SG_ VCLEFT_epbmReleaseVoltage m0 : 27|11@1+ (0.01,0) [0|0] "" Vector__XXX
 SG_ VCLEFT_activeDecelAllowedLatch m1 : 23|1@1+ (1,0) [0|0] "" Vector__XXX
 SG_ VCLEFT_summonUnavailableAllowed m1 : 22|1@1+ (1,0) [0|0] "" Vector__XXX
 SG_ VCLEFT_summonFaultAllowed m1 : 21|1@1+ (1,0) [0|0] "" Vector__XXX
 SG_ VCLEFT_summonCompleteAllowed m1 : 20|1@1+ (1,0) [0|0] "" Vector__XXX
 SG_ VCLEFT_summonActiveAllowed m1 : 19|1@1+ (1,0) [0|0] "" Vector__XXX
 SG_ VCLEFT_summonArmedAllowed m1 : 18|1@1+ (1,0) [0|0] "" Vector__XXX
 SG_ VCLEFT_summonIdleAllowed m1 : 17|1@1+ (1,0) [0|0] "" Vector__XXX
 SG_ VCLEFT_epbmApplyVoltage m0 : 16|11@1+ (0.01,0) [0|0] "" Vector__XXX
 SG_ VCLEFT_epbmUnknownAllowed m1 : 16|1@1+ (1,0) [0|0] "" Vector__XXX
 SG_ VCLEFT_summonInitAllowed m1 : 15|1@1+ (1,0) [0|0] "" Vector__XXX
 SG_ VCLEFT_epbmSummonReleaseAllowed m1 : 14|1@1+ (1,0) [0|0] "" Vector__XXX
 SG_ VCLEFT_epbmSummonParkAllowed m1 : 13|1@1+ (1,0) [0|0] "" Vector__XXX
 SG_ VCLEFT_epbmSummonAllowed m1 : 12|1@1+ (1,0) [0|0] "" Vector__XXX
 SG_ VCLEFT_epbmFaultAllowed m1 : 11|1@1+ (1,0) [0|0] "" Vector__XXX
 SG_ VCLEFT_epbmReleasingAllowed m1 : 10|1@1+ (1,0) [0|0] "" Vector__XXX
 SG_ VCLEFT_epbmDynApplyingAllowed m1 : 9|1@1+ (1,0) [0|0] "" Vector__XXX
 SG_ VCLEFT_epbmParkingAllowed m1 : 8|1@1+ (1,0) [0|0] "" Vector__XXX
 SG_ VCLEFT_epbmWinchReleaseAllowed m1 : 7|1@1+ (1,0) [0|0] "" Vector__XXX
 SG_ VCLEFT_epbmWinchAllowed m1 : 6|1@1+ (1,0) [0|0] "" Vector__XXX
 SG_ VCLEFT_epbMotorCurrent m0 : 5|11@1+ (0.01,0) [0|0] "" Vector__XXX
 SG_ VCLEFT_epbmServiceAllowed m1 : 5|1@1+ (1,0) [0|0] "" Vector__XXX
 SG_ VCLEFT_epbmMotorEnabled m0 : 4|1@1+ (1,0) [0|0] "" Vector__XXX
 SG_ VCLEFT_epbmStartAllowed m1 : 4|1@1+ (1,0) [0|0] "" Vector__XXX
 SG_ VCLEFT_epbmParkAllowed m1 : 3|1@1+ (1,0) [0|0] "" Vector__XXX
 SG_ VCLEFT_epbmDynamicAllowed m1 : 2|1@1+ (1,0) [0|0] "" Vector__XXX
 SG_ VCLEFT_epbmCaliperState m0 : 1|3@1+ (1,0) [0|0] "" Vector__XXX
 SG_ VCLEFT_epbmOpenAllowed m1 : 1|1@1+ (1,0) [0|0] "" Vector__XXX
 SG_ VCLEFT_epbmDebugIndex M : 0|1@1+ (1,0) [0|0] "" Vector__XXX

BO_ 627 UI_vehicleControl: 8 Vector__XXX
 SG_ UI_rearWindowLockout : 63|1@1+ (1,0) [0|0] "" Vector__XXX
 SG_ UI_driveStateRequest : 62|1@1+ (1,0) [0|0] "" Vector__XXX
 SG_ UI_honkHorn : 61|1@1+ (1,0) [0|0] "" Vector__XXX
 SG_ UI_domeLightSwitch : 59|2@1+ (1,0) [0|0] "" Vector__XXX
 SG_ UI_wiperRequest : 56|3@1+ (1,0) [0|0] "" Vector__XXX
 SG_ UI_remoteClosureRequest : 54|2@1+ (1,0) [0|0] "" Vector__XXX
 SG_ UI_mirrorDipOnReverse : 53|1@1+ (1,0) [0|0] "" Vector__XXX
 SG_ UI_autoFoldMirrorsOn : 52|1@1+ (1,0) [0|0] "" Vector__XXX
 SG_ UI_rearRightSeatHeatReq : 50|2@1+ (1,0) [0|0] "" Vector__XXX
 SG_ UI_rearCenterSeatHeatReq : 48|2@1+ (1,0) [0|0] "" Vector__XXX
 SG_ UI_rearLeftSeatHeatReq : 46|2@1+ (1,0) [0|0] "" Vector__XXX
 SG_ UI_frontRightSeatHeatReq : 44|2@1+ (1,0) [0|0] "" Vector__XXX
 SG_ UI_frontLeftSeatHeatReq : 42|2@1+ (1,0) [0|0] "" Vector__XXX
 SG_ UI_autoHighBeamEnabled : 41|1@1+ (1,0) [0|0] "" Vector__XXX
 SG_ UI_ambientLightingEnabled : 40|1@1+ (1,0) [0|0] "" Vector__XXX
 SG_ UI_displayBrightnessLevel : 32|8@1+ (0.5,0) [0|0] "" Vector__XXX
 SG_ UI_powerOff : 31|1@1+ (1,0) [0|0] "" Vector__XXX
 SG_ UI_seeYouHomeLightingOn : 30|1@1+ (1,0) [0|0] "" Vector__XXX
 SG_ UI_remoteStartRequest : 27|3@1+ (1,0) [0|0] "" Vector__XXX
 SG_ UI_mirrorHeatRequest : 26|1@1+ (1,0) [0|0] "" Vector__XXX
 SG_ UI_mirrorFoldRequest : 24|2@1+ (1,0) [0|0] "" Vector__XXX
 SG_ UI_rearFogSwitch : 23|1@1+ (1,0) [0|0] "" Vector__XXX
 SG_ UI_stop12vSupport : 22|1@1+ (1,0) [0|0] "" Vector__XXX
 SG_ UI_intrusionSensorOn : 21|1@1+ (1,0) [0|0] "" Vector__XXX
 SG_ UI_alarmEnabled : 20|1@1+ (1,0) [0|0] "" Vector__XXX
 SG_ UI_lockRequest : 17|3@1+ (1,0) [0|0] "" Vector__XXX
 SG_ UI_childDoorLockOnLeft : 16|1@1+ (1,0) [0|0] "" Vector__XXX
 SG_ UI_globalUnlockOn : 15|1@1+ (1,0) [0|0] "" Vector__XXX
 SG_ UI_unlockOnPark : 14|1@1+ (1,0) [0|0] "" Vector__XXX
 SG_ UI_walkAwayLock : 13|1@1+ (1,0) [0|0] "" Vector__XXX
 SG_ UI_walkUpUnlock : 12|1@1+ (1,0) [0|0] "" Vector__XXX
 SG_ UI_steeringButtonMode : 9|3@1+ (1,0) [0|0] "" Vector__XXX
 SG_ UI_steeringBacklightEnabled : 8|1@1+ (1,0) [0|0] "" Vector__XXX
 SG_ UI_wiperMode : 6|2@1+ (1,0) [0|0] "" Vector__XXX
 SG_ UI_frunkRequest : 5|1@1+ (1,0) [0|0] "" Vector__XXX
 SG_ UI_summonActive : 4|1@1+ (1,0) [0|0] "" Vector__XXX
 SG_ UI_frontFogSwitch : 3|1@1+ (1,0) [0|0] "" Vector__XXX
 SG_ UI_childDoorLockOnRight : 2|1@1+ (1,0) [0|0] "" Vector__XXX
 SG_ UI_powerStateRequest : 0|2@1+ (1,0) [0|0] "" Vector__XXX

BO_ 630 DI_authenticityMsg: 8 Vector__XXX
 SG_ DI_salt7 : 56|8@1+ (1,0) [0|0] "" Vector__XXX
 SG_ DI_salt6 : 48|8@1+ (1,0) [0|0] "" Vector__XXX
 SG_ DI_salt5 : 40|8@1+ (1,0) [0|0] "" Vector__XXX
 SG_ DI_salt4 : 32|8@1+ (1,0) [0|0] "" Vector__XXX
 SG_ DI_salt3 : 24|8@1+ (1,0) [0|0] "" Vector__XXX
 SG_ DI_salt2 : 16|8@1+ (1,0) [0|0] "" Vector__XXX
 SG_ DI_salt1 : 8|8@1+ (1,0) [0|0] "" Vector__XXX
 SG_ DI_authenticityCommand : 0|8@1+ (1,0) [0|0] "" Vector__XXX

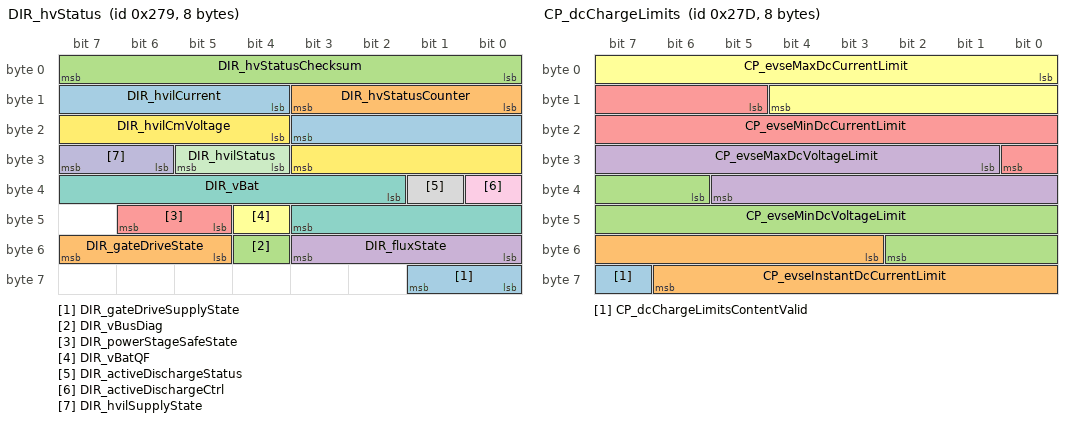
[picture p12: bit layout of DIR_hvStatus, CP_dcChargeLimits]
BO_ 633 DIR_hvStatus: 8 Vector__XXX
 SG_ DIR_gateDriveSupplyState : 56|2@1+ (1,0) [0|0] "" Vector__XXX
 SG_ DIR_gateDriveState : 53|3@1+ (1,0) [0|0] "" Vector__XXX
 SG_ DIR_vBusDiag : 52|1@1+ (1,0) [0|0] "" Vector__XXX
 SG_ DIR_fluxState : 48|4@1+ (1,0) [0|0] "" Vector__XXX
 SG_ DIR_powerStageSafeState : 45|2@1+ (1,0) [0|0] "" Vector__XXX
 SG_ DIR_vBatQF : 44|1@1+ (1,0) [0|0] "" Vector__XXX
 SG_ DIR_vBat : 34|10@1+ (1,0) [0|0] "" Vector__XXX
 SG_ DIR_activeDischargeStatus : 33|1@1+ (1,0) [0|0] "" Vector__XXX
 SG_ DIR_activeDischargeCtrl : 32|1@1+ (1,0) [0|0] "" Vector__XXX
 SG_ DIR_hvilSupplyState : 30|2@1+ (1,0) [0|0] "" Vector__XXX
 SG_ DIR_hvilStatus : 28|2@1+ (1,0) [0|0] "" Vector__XXX
 SG_ DIR_hvilCmVoltage : 20|8@1+ (0.08,0) [0|0] "" Vector__XXX
 SG_ DIR_hvilCurrent : 12|8@1+ (0.1,0) [0|0] "" Vector__XXX
 SG_ DIR_hvStatusCounter : 8|4@1+ (1,0) [0|0] "" Vector__XXX
 SG_ DIR_hvStatusChecksum : 0|8@1+ (1,0) [0|0] "" Vector__XXX

BO_ 637 CP_dcChargeLimits: 8 Vector__XXX
 SG_ CP_dcChargeLimitsContentValid : 63|1@1+ (1,0) [0|0] "" Vector__XXX
 SG_ CP_evseInstantDcCurrentLimit : 51|12@1+ (0.5,0) [0|0] "" Vector__XXX
 SG_ CP_evseMinDcVoltageLimit : 38|13@1+ (0.07324218755,0) [0|0] "" Vector__XXX
 SG_ CP_evseMaxDcVoltageLimit : 25|13@1+ (0.07324218755,0) [0|0] "" Vector__XXX
 SG_ CP_evseMinDcCurrentLimit : 13|12@1+ (0.5,0) [0|0] "" Vector__XXX
 SG_ CP_evseMaxDcCurrentLimit : 0|13@1+ (0.25,0) [0|0] "" Vector__XXX

BO_ 642 VCLEFT_hvacBlowerFeedback: 8 Vector__XXX
 SG_ VCLEFT_hvacBlowerPowerOn m0 : 61|1@1+ (1,0) [0|0] "" Vector__XXX
 SG_ VCLEFT_hvacBlowerLimitFETTemps m0 : 60|1@1+ (1,0) [0|0] "" Vector__XXX
 SG_ VCLEFT_hvacBlowerFault m0 : 59|1@1+ (1,0) [0|0] "" Vector__XXX
 SG_ VCLEFT_hvacBlowerInitd m0 : 58|1@1+ (1,0) [0|0] "" Vector__XXX
 SG_ VCLEFT_hvacBlowerIDc m0 : 51|7@1+ (0.5,0) [0|0] "" Vector__XXX
 SG_ VCLEFT_hvacBlowerFETTemp m0 : 44|7@1+ (2,-50) [0|0] "" Vector__XXX
 SG_ VCLEFT_hvacBlowerTorque m0 : 34|10@1+ (0.006,-1.5) [0|0] "" Vector__XXX
 SG_ VCLEFT_hvacBlowerRPMActual m0 : 20|10@1+ (10,0) [0|0] "" Vector__XXX
 SG_ VCLEFT_hvacBlowerRPMTarget m0 : 10|10@1+ (10,0) [0|0] "" Vector__XXX
 SG_ VCLEFT_hvacBlowerOutputDuty m0 : 3|7@1+ (1,0) [0|0] "" Vector__XXX
 SG_ VCLEFT_hvacBlowerEnabled m0 : 2|1@1+ (1,0) [0|0] "" Vector__XXX
 SG_ VCLEFT_hvacBlowerFeedbackIndex M : 0|1@1+ (1,0) [0|0] "" Vector__XXX

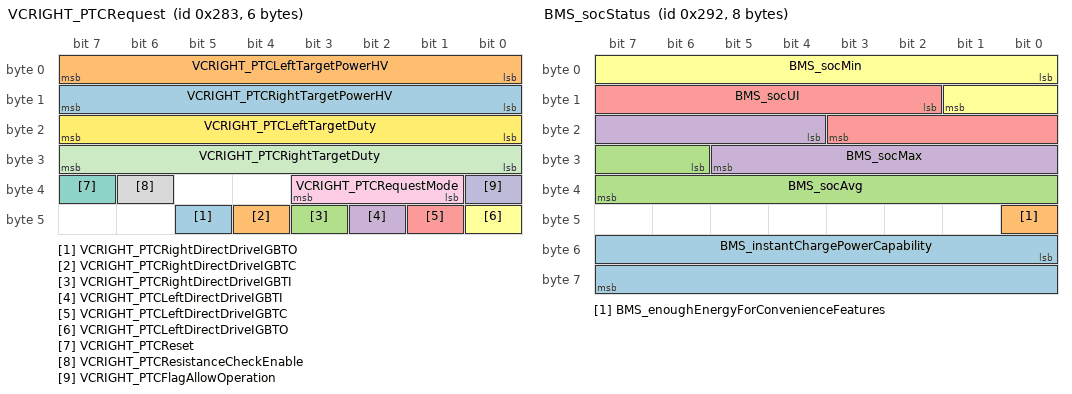
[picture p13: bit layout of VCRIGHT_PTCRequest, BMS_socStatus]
BO_ 643 VCRIGHT_PTCRequest: 6 Vector__XXX
 SG_ VCRIGHT_PTCRightDirectDriveIGBTO : 45|1@1+ (1,0) [0|0] "" Vector__XXX
 SG_ VCRIGHT_PTCRightDirectDriveIGBTC : 44|1@1+ (1,0) [0|0] "" Vector__XXX
 SG_ VCRIGHT_PTCRightDirectDriveIGBTI : 43|1@1+ (1,0) [0|0] "" Vector__XXX
 SG_ VCRIGHT_PTCLeftDirectDriveIGBTI : 42|1@1+ (1,0) [0|0] "" Vector__XXX
 SG_ VCRIGHT_PTCLeftDirectDriveIGBTC : 41|1@1+ (1,0) [0|0] "" Vector__XXX
 SG_ VCRIGHT_PTCLeftDirectDriveIGBTO : 40|1@1+ (1,0) [0|0] "" Vector__XXX
 SG_ VCRIGHT_PTCReset : 39|1@1+ (1,0) [0|0] "" Vector__XXX
 SG_ VCRIGHT_PTCResistanceCheckEnable : 38|1@1+ (1,0) [0|0] "" Vector__XXX
 SG_ VCRIGHT_PTCRequestMode : 33|3@1+ (1,0) [0|0] "" Vector__XXX
 SG_ VCRIGHT_PTCFlagAllowOperation : 32|1@1+ (1,0) [0|0] "" Vector__XXX
 SG_ VCRIGHT_PTCRightTargetDuty : 24|8@1+ (0.5,0) [0|0] "" Vector__XXX
 SG_ VCRIGHT_PTCLeftTargetDuty : 16|8@1+ (0.5,0) [0|0] "" Vector__XXX
 SG_ VCRIGHT_PTCRightTargetPowerHV : 8|8@1+ (30,0) [0|0] "" Vector__XXX
 SG_ VCRIGHT_PTCLeftTargetPowerHV : 0|8@1+ (30,0) [0|0] "" Vector__XXX

BO_ 644 UI_vehicleModes: 8 Vector__XXX
 SG_ UI_vehicleModesChecksum : 56|8@1+ (1,0) [0|0] "" Vector__XXX
 SG_ UI_vehicleModesCounter : 52|4@1+ (1,0) [0|0] "" Vector__XXX
 SG_ UI_upkeepMode : 46|1@1+ (1,0) [0|0] "" Vector__XXX
 SG_ UI_sohTestRequest : 45|1@1+ (1,0) [0|0] "" Vector__XXX
 SG_ UI_lightShowType : 42|3@1+ (1,0) [0|0] "" Vector__XXX
 SG_ UI_closureEasterEggStatus : 40|2@1+ (1,0) [0|0] "" Vector__XXX
 SG_ UI_signedCmdServiceMode : 39|1@1+ (1,0) [0|0] "" Vector__XXX
 SG_ UI_signedCmdHardLocked : 38|1@1+ (1,0) [0|0] "" Vector__XXX
 SG_ UI_premiumAmpPowerOff : 37|1@1+ (1,0) [0|0] "" Vector__XXX
 SG_ UI_serviceModePlus : 36|1@1+ (1,0) [0|0] "" Vector__XXX
 SG_ UI_diagnosticsAllowed : 35|1@1+ (1,0) [0|0] "" Vector__XXX
 SG_ UI_gameMode : 34|1@1+ (1,0) [0|0] "" Vector__XXX
 SG_ UI_valetMode : 33|1@1+ (1,0) [0|0] "" Vector__XXX
 SG_ UI_carWashMode : 32|1@1+ (1,0) [0|0] "" Vector__XXX
 SG_ UI_homelinkV2Command2 : 24|8@1+ (1,0) [0|0] "" Vector__XXX
 SG_ UI_homelinkV2Command1 : 16|8@1+ (1,0) [0|0] "" Vector__XXX
 SG_ UI_homelinkV2Command0 : 8|8@1+ (1,0) [0|0] "" Vector__XXX
 SG_ UI_hasEverBeenDelivered : 5|1@1+ (1,0) [0|0] "" Vector__XXX
 SG_ UI_isDelivered : 4|1@1+ (1,0) [0|0] "" Vector__XXX
 SG_ UI_serviceMode : 3|1@1+ (1,0) [0|0] "" Vector__XXX
 SG_ UI_showroomMode : 2|1@1+ (1,0) [0|0] "" Vector__XXX
 SG_ UI_transportMode : 1|1@1+ (1,0) [0|0] "" Vector__XXX
 SG_ UI_factoryMode : 0|1@1+ (1,0) [0|0] "" Vector__XXX

BO_ 645 UI_driverProfileRecall: 8 Vector__XXX
 SG_ UI_frontSeatTiltPos m1 : 48|12@1- (0.1,0) [0|0] "" Vector__XXX
 SG_ UI_steeringColumnInOutPos m2 : 48|8@1- (1,103) [0|0] "" Vector__XXX
 SG_ UI_modifyMirrorDipRequest m4 : 40|2@1+ (1,0) [0|0] "" Vector__XXX
 SG_ UI_frontSeatLiftPos m1 : 32|10@1- (4,0) [0|0] "" Vector__XXX
 SG_ UI_lumbarBPressurePercentage m2 : 32|7@1+ (1,0) [0|0] "" Vector__XXX
 SG_ UI_rightMirrorDipYPosition m4 : 32|8@1+ (0.02,0) [0|0] "" Vector__XXX
 SG_ UI_rightMirrorTiltYPosition m3 : 32|8@1+ (0.02,0) [0|0] "" Vector__XXX
 SG_ UI_rightMirrorDipXPosition m4 : 24|8@1+ (0.02,0) [0|0] "" Vector__XXX
 SG_ UI_rightMirrorTiltXPosition m3 : 24|8@1+ (0.02,0) [0|0] "" Vector__XXX
 SG_ UI_frontSeatBackPos m1 : 16|12@1- (0.1,0) [0|0] "" Vector__XXX
 SG_ UI_leftMirrorDipYPosition m4 : 16|8@1+ (0.02,0) [0|0] "" Vector__XXX
 SG_ UI_leftMirrorTiltYPosition m3 : 16|8@1+ (0.02,0) [0|0] "" Vector__XXX
 SG_ UI_lumbarAPressurePercentage m2 : 16|7@1+ (1,0) [0|0] "" Vector__XXX
 SG_ UI_leftMirrorDipXPosition m4 : 8|8@1+ (0.02,0) [0|0] "" Vector__XXX
 SG_ UI_leftMirrorTiltXPosition m3 : 8|8@1+ (0.02,0) [0|0] "" Vector__XXX
 SG_ UI_steeringColumnUpDownPos m2 : 8|8@1- (1,103) [0|0] "" Vector__XXX
 SG_ UI_customMirrorDipPositionsSet m4 : 5|1@1+ (1,0) [0|0] "" Vector__XXX
 SG_ UI_frontSeatTrackPos m1 : 5|10@1- (4,0) [0|0] "" Vector__XXX
 SG_ UI_columnAndLumbarRecallActive m2 : 4|1@1+ (1,0) [0|0] "" Vector__XXX
 SG_ UI_frontSeatRecallActive m1 : 4|1@1+ (1,0) [0|0] "" Vector__XXX
 SG_ UI_mirrorRecallActive m4 : 4|1@1+ (1,0) [0|0] "" Vector__XXX
 SG_ UI_driverProfileRecallStop : 3|1@1+ (1,0) [0|0] "" Vector__XXX
 SG_ UI_driverProfileRecallIndex M : 0|3@1+ (1,0) [0|0] "" Vector__XXX

BO_ 646 UI_driverProfileRecall2: 5 Vector__XXX
 SG_ UI_activeKeyRequested : 39|1@1+ (1,0) [0|0] "" Vector__XXX
 SG_ UI_driverProfilePositionAdjusted : 38|1@1+ (1,0) [0|0] "" Vector__XXX
 SG_ UI_driverProfileSelectionType : 36|2@1+ (1,0) [0|0] "" Vector__XXX
 SG_ UI_driverProfileIndex : 32|4@1+ (1,0) [0|0] "" Vector__XXX
 SG_ UI_driverProfileLinkedKeySHA1 : 0|32@1+ (1,0) [0|0] "" Vector__XXX

BO_ 648 EPBL_internalStatus: 8 Vector__XXX
 SG_ EPBL_internalStatusChecksum : 56|8@1+ (1,0) [0|0] "" Vector__XXX
 SG_ EPBL_internalStatusCounter : 52|4@1+ (1,0) [0|0] "" Vector__XXX
 SG_ EPBL_learnedEpbConfig : 48|4@1+ (1,0) [0|0] "" Vector__XXX
 SG_ EPBL_esmSpeedClass : 45|3@1+ (1,0) [0|0] "" Vector__XXX
 SG_ EPBL_internalCDPRequest : 44|1@1+ (1,0) [0|0] "" Vector__XXX
 SG_ EPBL_driverIsLeavingAnySpeedLocal : 43|1@1+ (1,0) [0|0] "" Vector__XXX
 SG_ EPBL_driverIsLeavingLocal : 42|1@1+ (1,0) [0|0] "" Vector__XXX
 SG_ EPBL_telltaleLocal : 39|3@1+ (1,0) [0|0] "" Vector__XXX
 SG_ EPBL_chimeRequestLocal : 33|3@1+ (1,0) [0|0] "" Vector__XXX
 SG_ EPBL_localCdpState : 30|2@1+ (1,0) [0|0] "" Vector__XXX
 SG_ EPBL_localServiceModeActive : 29|1@1+ (1,0) [0|0] "" Vector__XXX
 SG_ EPBL_summonFaultReason : 24|5@1+ (1,0) [0|0] "" Vector__XXX
 SG_ EPBL_esmOperationTrigger : 18|6@1+ (1,0) [0|0] "" Vector__XXX
 SG_ EPBL_csmFaultReason : 13|5@1+ (1,0) [0|0] "" Vector__XXX
 SG_ EPBL_pistonTouchingRotor : 12|1@1+ (1,0) [0|0] "" Vector__XXX
 SG_ EPBL_disconnected : 11|1@1+ (1,0) [0|0] "" Vector__XXX
 SG_ EPBL_summonState : 8|3@1+ (1,0) [0|0] "" Vector__XXX
 SG_ EPBL_unitFaultStatus : 5|2@1+ (1,0) [0|0] "" Vector__XXX
 SG_ EPBL_unitStatus : 0|5@1+ (1,0) [0|0] "" Vector__XXX

BO_ 649 VCLEFT_logging10Hz: 8 Vector__XXX
 SG_ VCLEFT_hvacBlowerRsOnlineActive m0 : 63|1@1+ (1,0) [0|0] "" Vector__XXX
 SG_ VCLEFT_hvacBlowerSpiError m0 : 62|1@1+ (1,0) [0|0] "" Vector__XXX
 SG_ VCLEFT_hvacBlowerITerm m0 : 55|7@1+ (0.05,-1.5) [0|0] "" Vector__XXX
 SG_ VCLEFT_hvacBlowerCBCCtrlState m0 : 52|3@1+ (1,0) [0|0] "" Vector__XXX
 SG_ VCLEFT_hvacBlowerCBCEstState m0 : 48|4@1+ (1,0) [0|0] "" Vector__XXX
 SG_ VCLEFT_hvacBlower_IO_CBC_numUartErr m0 : 40|8@1+ (1,0) [0|0] "" Vector__XXX
 SG_ VCLEFT_hvacBlower_IO_CBC_Status m0 : 39|1@1+ (1,0) [0|0] "" Vector__XXX
 SG_ VCLEFT_hvacBlower_IO_CBC_TAIL_valid m0 : 38|1@1+ (1,0) [0|0] "" Vector__XXX
 SG_ VCLEFT_hvacBlower_IO_CBC_TAIL m0 : 34|4@1+ (1,0) [0|0] "" Vector__XXX
 SG_ VCLEFT_hvacBlower_IO_CBC_HEAD m0 : 30|4@1+ (1,0) [0|0] "" Vector__XXX
 SG_ VCLEFT_hvacBlowerIPhase2 m0 : 23|7@1+ (0.4,0) [0|0] "" Vector__XXX
 SG_ VCLEFT_hvacBlowerIPhase1 m0 : 16|7@1+ (0.4,0) [0|0] "" Vector__XXX
 SG_ VCLEFT_hvacBlowerIPhase0 m0 : 9|7@1+ (0.4,0) [0|0] "" Vector__XXX
 SG_ VCLEFT_hvacBlowerRs m0 : 1|8@1+ (0.25,0) [0|0] "" Vector__XXX
 SG_ VCLEFT_logging10HzIndex M : 0|1@1+ (1,0) [0|0] "" Vector__XXX

BO_ 658 BMS_socStatus: 8 Vector__XXX
 SG_ BMS_instantChargePowerCapability : 48|16@1+ (0.05,0) [0|0] "" Vector__XXX
 SG_ BMS_enoughEnergyForConvenienceFeatures : 40|1@1+ (1,0) [0|0] "" Vector__XXX
 SG_ BMS_socAvg : 30|10@1+ (0.1,0) [0|0] "" Vector__XXX
 SG_ BMS_socMax : 20|10@1+ (0.1,0) [0|0] "" Vector__XXX
 SG_ BMS_socUI : 10|10@1+ (0.1,0) [0|0] "" Vector__XXX
 SG_ BMS_socMin : 0|10@1+ (0.1,0) [0|0] "" Vector__XXX

BO_ 659 UI_chassisControl: 8 Vector__XXX
 SG_ UI_chassisControlChecksum : 56|8@1+ (1,0) [0|0] "" Vector__XXX
 SG_ UI_chassisControlCounter : 52|4@1+ (1,0) [0|0] "" Vector__XXX
 SG_ UI_selfParkTune : 48|4@1+ (1,0) [0|0] "" Vector__XXX
 SG_ UI_redLightStopSignEnable : 46|2@1+ (1,0) [0|0] "" Vector__XXX
 SG_ UI_pedalMap_epas : 44|2@1+ (1,0) [0|0] "" Vector__XXX
 SG_ UI_pedalSafetyEnable : 42|2@1+ (1,0) [0|0] "" Vector__XXX
 SG_ UI_ldwEnable : 40|2@1+ (1,0) [0|0] "" Vector__XXX
 SG_ UI_latControlEnable : 38|2@1+ (1,0) [0|0] "" Vector__XXX
 SG_ UI_fcwSensitivity : 36|2@1+ (1,0) [0|0] "" Vector__XXX
 SG_ UI_fcwEnable : 34|2@1+ (1,0) [0|0] "" Vector__XXX
 SG_ UI_bsdEnable : 32|2@1+ (1,0) [0|0] "" Vector__XXX
 SG_ UI_autoParkRequest : 28|4@1+ (1,0) [0|0] "" Vector__XXX
 SG_ UI_rebootAutopilot : 27|1@1+ (1,0) [0|0] "" Vector__XXX
 SG_ UI_winchProxUserOverride : 26|1@1+ (1,0) [0|0] "" Vector__XXX
 SG_ UI_autoLaneChangeEnable : 24|2@1+ (1,0) [0|0] "" Vector__XXX
 SG_ UI_ahlbEnable : 22|2@1+ (1,0) [0|0] "" Vector__XXX
 SG_ UI_aesEnable : 20|2@1+ (1,0) [0|0] "" Vector__XXX
 SG_ UI_aebEnable : 18|2@1+ (1,0) [0|0] "" Vector__XXX
 SG_ UI_accOvertakeEnable : 16|2@1+ (1,0) [0|0] "" Vector__XXX
 SG_ UI_dasDebugEnable : 14|1@1+ (1,0) [0|0] "" Vector__XXX
 SG_ UI_distanceUnits : 13|1@1+ (1,0) [0|0] "" Vector__XXX
 SG_ UI_trailerMode : 12|1@1+ (1,0) [0|0] "" Vector__XXX
 SG_ UI_zeroSpeedConfirmed : 10|2@1+ (1,0) [0|0] "" Vector__XXX
 SG_ UI_winchModeRequest : 8|2@1+ (1,0) [0|0] "" Vector__XXX
 SG_ UI_narrowGarages : 7|1@1+ (1,0) [0|0] "" Vector__XXX
 SG_ UI_parkBrakeRequest : 5|2@1+ (1,0) [0|0] "" Vector__XXX
 SG_ UI_tractionControlMode : 2|3@1+ (1,0) [0|0] "" Vector__XXX
 SG_ UI_steeringTuneRequest : 0|2@1+ (1,0) [0|0] "" Vector__XXX

BO_ 660 UI_vehicleControl3: 8 Vector__XXX
 SG_ UI_selfParkStandingBy : 62|1@1+ (1,0) [0|0] "" Vector__XXX
 SG_ UI_derivedLoadshedFeature : 59|1@1+ (1,0) [0|0] "" Vector__XXX
 SG_ UI_closeTrunkRequest : 55|1@1+ (1,0) [0|0] "" Vector__XXX
 SG_ UI_windowRequest : 52|3@1+ (1,0) [0|0] "" Vector__XXX
 SG_ UI_windowRequestedRR : 51|1@1+ (1,0) [0|0] "" Vector__XXX
 SG_ UI_windowRequestedRL : 50|1@1+ (1,0) [0|0] "" Vector__XXX
 SG_ UI_windowRequestedFR : 49|1@1+ (1,0) [0|0] "" Vector__XXX
 SG_ UI_windowRequestedFL : 48|1@1+ (1,0) [0|0] "" Vector__XXX
 SG_ UI_windowPercentageRequest : 42|6@1- (5,0) [0|0] "" Vector__XXX
 SG_ UI_keepOnAccessoryPortsReq : 38|1@1+ (1,0) [0|0] "" Vector__XXX
 SG_ UI_blindSpotIndicatorLightRequest : 35|1@1+ (1,0) [0|0] "" Vector__XXX
 SG_ UI_displayRedShiftActive : 24|1@1+ (1,0) [0|0] "" Vector__XXX
 SG_ UI_UMC3UpdateInhibit : 22|1@1+ (1,0) [0|0] "" Vector__XXX
 SG_ UI_packTempLoggingRequest : 18|1@1+ (1,0) [0|0] "" Vector__XXX
 SG_ UI_shortHornRequest : 17|1@1+ (1,0) [0|0] "" Vector__XXX
 SG_ UI_VCSECFeature5 : 16|1@1+ (1,0) [0|0] "" Vector__XXX
 SG_ UI_VCSECFeature4 : 15|1@1+ (1,0) [0|0] "" Vector__XXX
 SG_ UI_VCSECFeature3 : 14|1@1+ (1,0) [0|0] "" Vector__XXX
 SG_ UI_VCSECFeature2 : 13|1@1+ (1,0) [0|0] "" Vector__XXX
 SG_ UI_headlightPulseRequest : 12|1@1+ (1,0) [0|0] "" Vector__XXX
 SG_ UI_steeringWheelHeatLevelReq : 10|2@1+ (1,0) [0|0] "" Vector__XXX
 SG_ UI_steeringWheelHeatAutoReq : 9|1@1+ (1,0) [0|0] "" Vector__XXX
 SG_ UI_lightShowClosuresEnabled : 8|1@1+ (1,0) [0|0] "" Vector__XXX
 SG_ UI_keyPairResponse : 6|2@1+ (1,0) [0|0] "" Vector__XXX
 SG_ UI_drivingSideVEH : 4|2@1+ (1,0) [0|0] "" Vector__XXX
 SG_ UI_phoneCallActive : 3|1@1+ (1,0) [0|0] "" Vector__XXX
 SG_ UI_keylessDrivingEnabled : 2|1@1+ (1,0) [0|0] "" Vector__XXX
 SG_ UI_lightFlashRequest : 0|2@1+ (1,0) [0|0] "" Vector__XXX

BO_ 661 UI_powerRationalityConfig: 8 Vector__XXX
 SG_ UI_powerRationalityConfigIndex M : 56|8@1+ (1,0) [0|0] "" Vector__XXX
 SG_ UI_vcleftCfgCutoffDynamicC m8 : 32|16@1- (50,0) [0|0] "" Vector__XXX
 SG_ UI_vcleftCfgCutoffStaticC m7 : 32|16@1- (50,0) [0|0] "" Vector__XXX
 SG_ UI_vcleftCfgRationalityDynamicC m2 : 32|16@1- (50,0) [0|0] "" Vector__XXX
 SG_ UI_vcleftCfgRationalityStaticC m1 : 32|16@1- (50,0) [0|0] "" Vector__XXX
 SG_ UI_vcrightCfgCutoffDynamicC m11 : 32|16@1- (50,0) [0|0] "" Vector__XXX
 SG_ UI_vcrightCfgCutoffStaticC m10 : 32|16@1- (50,0) [0|0] "" Vector__XXX
 SG_ UI_vcrightCfgRationalityDynamicC m5 : 32|16@1- (50,0) [0|0] "" Vector__XXX
 SG_ UI_vcrightCfgRationalityStaticC m4 : 32|16@1- (50,0) [0|0] "" Vector__XXX
 SG_ UI_vcleftCfgCutoffDynamicB m8 : 16|16@1- (1,0) [0|0] "" Vector__XXX
 SG_ UI_vcleftCfgCutoffStaticB m7 : 16|16@1- (1,0) [0|0] "" Vector__XXX
 SG_ UI_vcleftCfgRationalityDynamicB m2 : 16|16@1- (1,0) [0|0] "" Vector__XXX
 SG_ UI_vcleftCfgRationalityStaticB m1 : 16|16@1- (1,0) [0|0] "" Vector__XXX
 SG_ UI_vcrightCfgCutoffDynamicB m11 : 16|16@1- (1,0) [0|0] "" Vector__XXX
 SG_ UI_vcrightCfgCutoffStaticB m10 : 16|16@1- (1,0) [0|0] "" Vector__XXX
 SG_ UI_vcrightCfgRationalityDynamicB m5 : 16|16@1- (1,0) [0|0] "" Vector__XXX
 SG_ UI_vcrightCfgRationalityStaticB m4 : 16|16@1- (1,0) [0|0] "" Vector__XXX
 SG_ UI_vcleftCfgCutoffTime1 m6 : 12|4@1+ (1,0) [0|0] "" Vector__XXX
 SG_ UI_vcleftCfgRationalityTime1 m0 : 12|4@1+ (1,0) [0|0] "" Vector__XXX
 SG_ UI_vcrightCfgCutoffTime1 m9 : 12|4@1+ (1,0) [0|0] "" Vector__XXX
 SG_ UI_vcrightCfgRationalityTime1 m3 : 12|4@1+ (1,0) [0|0] "" Vector__XXX
 SG_ UI_vcleftCfgCutoffThreshold1 m6 : 8|4@1+ (1,0) [0|0] "" Vector__XXX
 SG_ UI_vcleftCfgRationalityThreshold1 m0 : 8|4@1+ (1,0) [0|0] "" Vector__XXX
 SG_ UI_vcrightCfgCutoffThreshold1 m9 : 8|4@1+ (1,0) [0|0] "" Vector__XXX
 SG_ UI_vcrightCfgRationalityThreshold1 m3 : 8|4@1+ (1,0) [0|0] "" Vector__XXX
 SG_ UI_vcleftCfgCutoffTime0 m6 : 4|4@1+ (1,0) [0|0] "" Vector__XXX
 SG_ UI_vcleftCfgRationalityTime0 m0 : 4|4@1+ (1,0) [0|0] "" Vector__XXX
 SG_ UI_vcrightCfgCutoffTime0 m9 : 4|4@1+ (1,0) [0|0] "" Vector__XXX
 SG_ UI_vcrightCfgRationalityTime0 m3 : 4|4@1+ (1,0) [0|0] "" Vector__XXX
 SG_ UI_vcleftCfgCutoffDynamicA m8 : 0|16@1+ (50,0) [0|0] "" Vector__XXX
 SG_ UI_vcleftCfgCutoffStaticA m7 : 0|16@1+ (50,0) [0|0] "" Vector__XXX
 SG_ UI_vcleftCfgCutoffThreshold0 m6 : 0|4@1+ (1,0) [0|0] "" Vector__XXX
 SG_ UI_vcleftCfgRationalityDynamicA m2 : 0|16@1+ (50,0) [0|0] "" Vector__XXX
 SG_ UI_vcleftCfgRationalityStaticA m1 : 0|16@1+ (50,0) [0|0] "" Vector__XXX
 SG_ UI_vcleftCfgRationalityThreshold0 m0 : 0|4@1+ (1,0) [0|0] "" Vector__XXX
 SG_ UI_vcrightCfgCutoffDynamicA m11 : 0|16@1+ (50,0) [0|0] "" Vector__XXX
 SG_ UI_vcrightCfgCutoffStaticA m10 : 0|16@1+ (50,0) [0|0] "" Vector__XXX
 SG_ UI_vcrightCfgCutoffThreshold0 m9 : 0|4@1+ (1,0) [0|0] "" Vector__XXX
 SG_ UI_vcrightCfgRationalityDynamicA m5 : 0|16@1+ (50,0) [0|0] "" Vector__XXX
 SG_ UI_vcrightCfgRationalityStaticA m4 : 0|16@1+ (50,0) [0|0] "" Vector__XXX
 SG_ UI_vcrightCfgRationalityThreshold0 m3 : 0|4@1+ (1,0) [0|0] "" Vector__XXX

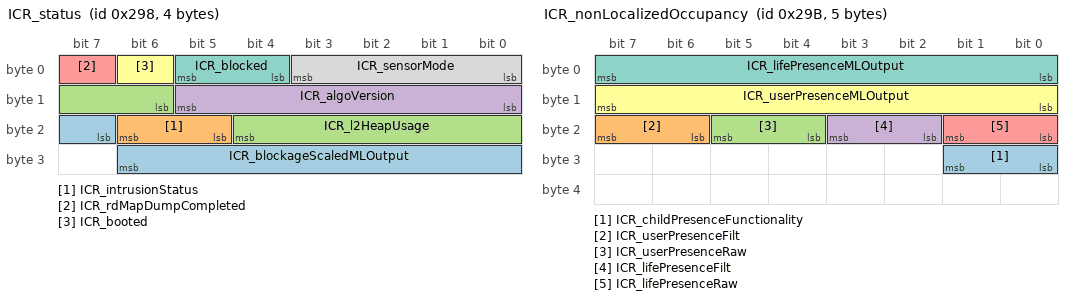
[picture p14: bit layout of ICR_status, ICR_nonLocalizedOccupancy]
BO_ 664 ICR_status: 4 Vector__XXX
 SG_ ICR_blockageScaledMLOutput : 23|8@1+ (0.004,0) [0|0] "" Vector__XXX
 SG_ ICR_intrusionStatus : 21|2@1+ (1,0) [0|0] "" Vector__XXX
 SG_ ICR_l2HeapUsage : 14|7@1+ (1,0) [0|0] "" Vector__XXX
 SG_ ICR_algoVersion : 8|6@1+ (1,0) [0|0] "" Vector__XXX
 SG_ ICR_rdMapDumpCompleted : 7|1@1+ (1,0) [0|0] "" Vector__XXX
 SG_ ICR_booted : 6|1@1+ (1,0) [0|0] "" Vector__XXX
 SG_ ICR_blocked : 4|2@1+ (1,0) [0|0] "" Vector__XXX
 SG_ ICR_sensorMode : 0|4@1+ (1,0) [0|0] "" Vector__XXX

BO_ 667 ICR_nonLocalizedOccupancy: 5 Vector__XXX
 SG_ ICR_childPresenceFunctionality : 24|2@1+ (1,0) [0|0] "" Vector__XXX
 SG_ ICR_userPresenceFilt : 22|2@1+ (1,0) [0|0] "" Vector__XXX
 SG_ ICR_userPresenceRaw : 20|2@1+ (1,0) [0|0] "" Vector__XXX
 SG_ ICR_lifePresenceFilt : 18|2@1+ (1,0) [0|0] "" Vector__XXX
 SG_ ICR_lifePresenceRaw : 16|2@1+ (1,0) [0|0] "" Vector__XXX
 SG_ ICR_userPresenceMLOutput : 8|8@1+ (0.004,0) [0|0] "" Vector__XXX
 SG_ ICR_lifePresenceMLOutput : 0|8@1+ (0.004,0) [0|0] "" Vector__XXX

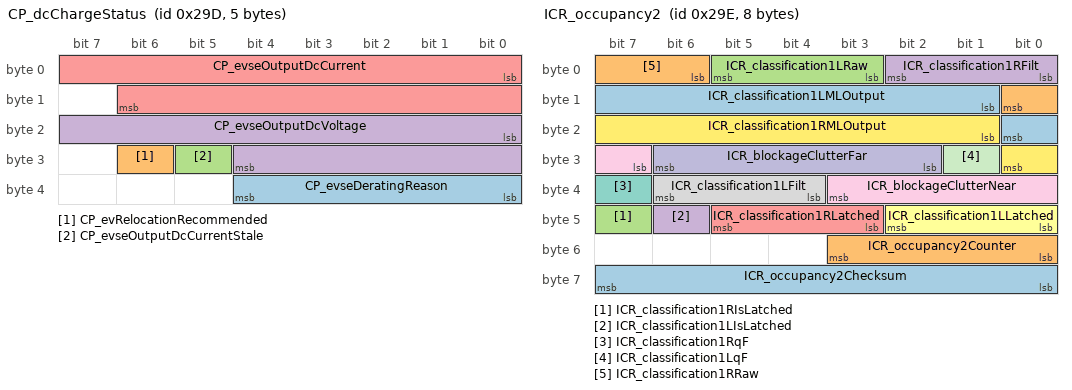
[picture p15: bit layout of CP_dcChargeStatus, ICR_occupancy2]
BO_ 669 CP_dcChargeStatus: 5 Vector__XXX
 SG_ CP_evseDeratingReason : 32|5@1+ (1,0) [0|0] "" Vector__XXX
 SG_ CP_evRelocationRecommended : 30|1@1+ (1,0) [0|0] "" Vector__XXX
 SG_ CP_evseOutputDcCurrentStale : 29|1@1+ (1,0) [0|0] "" Vector__XXX
 SG_ CP_evseOutputDcVoltage : 16|13@1+ (0.07324218755,0) [0|0] "" Vector__XXX
 SG_ CP_evseOutputDcCurrent : 0|15@1- (0.125,0) [0|0] "" Vector__XXX

BO_ 670 ICR_occupancy2: 8 Vector__XXX
 SG_ ICR_occupancy2Checksum : 56|8@1+ (1,0) [0|0] "" Vector__XXX
 SG_ ICR_occupancy2Counter : 48|4@1+ (1,0) [0|0] "" Vector__XXX
 SG_ ICR_classification1RIsLatched : 47|1@1+ (1,0) [0|0] "" Vector__XXX
 SG_ ICR_classification1LIsLatched : 46|1@1+ (1,0) [0|0] "" Vector__XXX
 SG_ ICR_classification1RLatched : 43|3@1+ (1,0) [0|0] "" Vector__XXX
 SG_ ICR_classification1LLatched : 40|3@1+ (1,0) [0|0] "" Vector__XXX
 SG_ ICR_classification1RqF : 39|1@1+ (1,0) [0|0] "" Vector__XXX
 SG_ ICR_classification1LFilt : 36|3@1+ (1,0) [0|0] "" Vector__XXX
 SG_ ICR_blockageClutterNear : 31|5@1- (0.5,-1.5) [0|0] "" Vector__XXX
 SG_ ICR_blockageClutterFar : 26|5@1- (0.5,-1.5) [0|0] "" Vector__XXX
 SG_ ICR_classification1LqF : 25|1@1+ (1,0) [0|0] "" Vector__XXX
 SG_ ICR_classification1RMLOutput : 17|8@1+ (0.004,0) [0|0] "" Vector__XXX
 SG_ ICR_classification1LMLOutput : 9|8@1+ (0.004,0) [0|0] "" Vector__XXX
 SG_ ICR_classification1RRaw : 6|3@1+ (1,0) [0|0] "" Vector__XXX
 SG_ ICR_classification1LRaw : 3|3@1+ (1,0) [0|0] "" Vector__XXX
 SG_ ICR_classification1RFilt : 0|3@1+ (1,0) [0|0] "" Vector__XXX

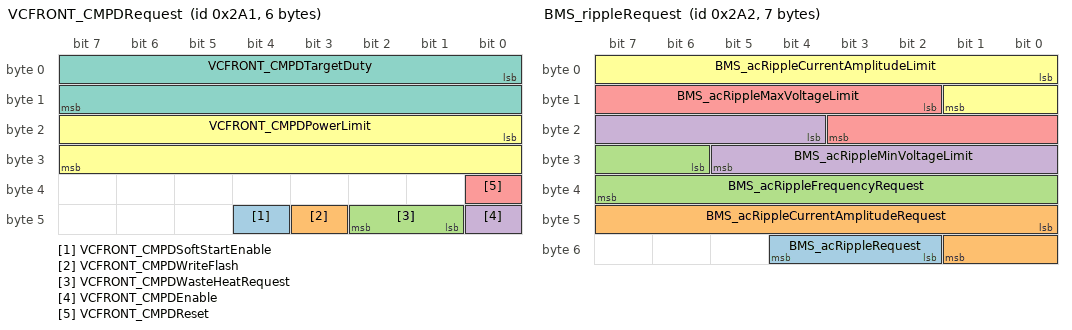
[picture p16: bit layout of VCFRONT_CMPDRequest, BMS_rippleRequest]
BO_ 673 VCFRONT_CMPDRequest: 6 Vector__XXX
 SG_ VCFRONT_CMPDSoftStartEnable : 44|1@1+ (1,0) [0|0] "" Vector__XXX
 SG_ VCFRONT_CMPDWriteFlash : 43|1@1+ (1,0) [0|0] "" Vector__XXX
 SG_ VCFRONT_CMPDWasteHeatRequest : 41|2@1+ (1,0) [0|0] "" Vector__XXX
 SG_ VCFRONT_CMPDEnable : 40|1@1+ (1,0) [0|0] "" Vector__XXX
 SG_ VCFRONT_CMPDReset : 32|1@1+ (1,0) [0|0] "" Vector__XXX
 SG_ VCFRONT_CMPDPowerLimit : 16|16@1+ (1,0) [0|0] "" Vector__XXX
 SG_ VCFRONT_CMPDTargetDuty : 0|16@1+ (0.1,0) [0|0] "" Vector__XXX

BO_ 674 BMS_rippleRequest: 7 Vector__XXX
 SG_ BMS_acRippleRequest : 50|3@1+ (1,0) [0|0] "" Vector__XXX
 SG_ BMS_acRippleCurrentAmplitudeRequest : 40|10@1+ (1,0) [0|0] "" Vector__XXX
 SG_ BMS_acRippleFrequencyRequest : 30|10@1+ (1,0) [0|0] "" Vector__XXX
 SG_ BMS_acRippleMinVoltageLimit : 20|10@1+ (1,0) [0|0] "" Vector__XXX
 SG_ BMS_acRippleMaxVoltageLimit : 10|10@1+ (1,0) [0|0] "" Vector__XXX
 SG_ BMS_acRippleCurrentAmplitudeLimit : 0|10@1+ (1,0) [0|0] "" Vector__XXX

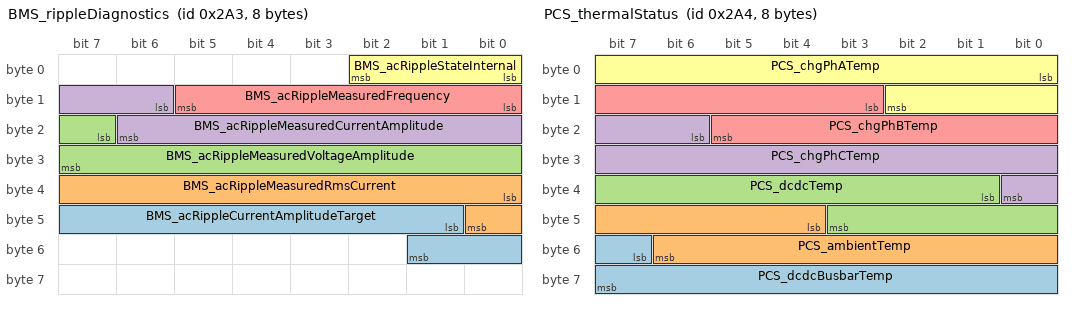
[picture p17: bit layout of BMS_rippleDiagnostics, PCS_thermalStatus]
BO_ 675 BMS_rippleDiagnostics: 8 Vector__XXX
 SG_ BMS_acRippleCurrentAmplitudeTarget : 41|9@1+ (1,0) [0|0] "" Vector__XXX
 SG_ BMS_acRippleMeasuredRmsCurrent : 32|9@1+ (1,0) [0|0] "" Vector__XXX
 SG_ BMS_acRippleMeasuredVoltageAmplitude : 23|9@1+ (1,0) [0|0] "" Vector__XXX
 SG_ BMS_acRippleMeasuredCurrentAmplitude : 14|9@1+ (1,0) [0|0] "" Vector__XXX
 SG_ BMS_acRippleMeasuredFrequency : 8|6@1+ (1,80) [0|0] "" Vector__XXX
 SG_ BMS_acRippleStateInternal : 0|3@1+ (1,0) [0|0] "" Vector__XXX

BO_ 676 PCS_thermalStatus: 8 Vector__XXX
 SG_ PCS_dcdcBusbarTemp : 55|9@1+ (0.29354207436399216,0) [0|0] "" Vector__XXX
 SG_ PCS_ambientTemp : 44|11@1- (0.1,40) [0|0] "" Vector__XXX
 SG_ PCS_dcdcTemp : 33|11@1- (0.1,40) [0|0] "" Vector__XXX
 SG_ PCS_chgPhCTemp : 22|11@1- (0.1,40) [0|0] "" Vector__XXX
 SG_ PCS_chgPhBTemp : 11|11@1- (0.1,40) [0|0] "" Vector__XXX
 SG_ PCS_chgPhATemp : 0|11@1- (0.1,40) [0|0] "" Vector__XXX

BO_ 678 CMPD_motorState: 8 Vector__XXX
 SG_ CMPD_motorOverloadCountdown : 16|13@1+ (1,0) [0|0] "" Vector__XXX
 SG_ CMPD_motorCurrent : 0|16@1+ (0.1,0) [0|0] "" Vector__XXX

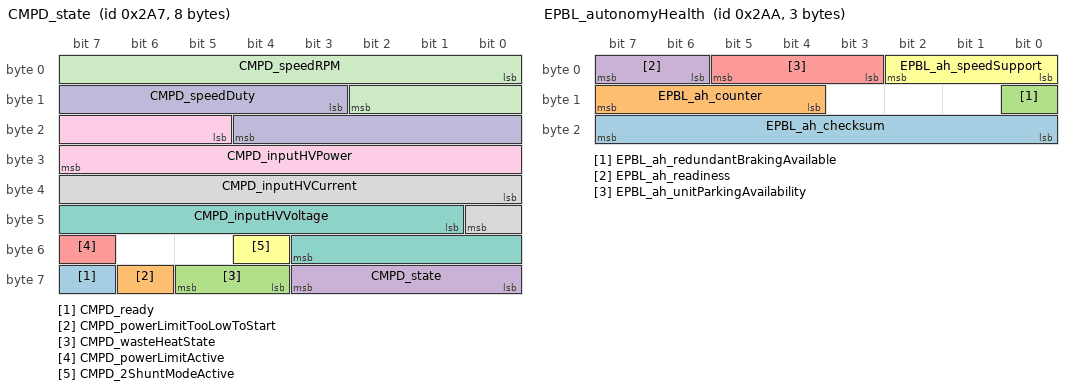
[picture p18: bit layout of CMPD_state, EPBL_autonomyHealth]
BO_ 679 CMPD_state: 8 Vector__XXX
 SG_ CMPD_ready : 63|1@1+ (1,0) [0|0] "" Vector__XXX
 SG_ CMPD_powerLimitTooLowToStart : 62|1@1+ (1,0) [0|0] "" Vector__XXX
 SG_ CMPD_wasteHeatState : 60|2@1+ (1,0) [0|0] "" Vector__XXX
 SG_ CMPD_state : 56|4@1+ (1,0) [0|0] "" Vector__XXX
 SG_ CMPD_powerLimitActive : 55|1@1+ (1,0) [0|0] "" Vector__XXX
 SG_ CMPD_2ShuntModeActive : 52|1@1+ (1,0) [0|0] "" Vector__XXX
 SG_ CMPD_inputHVVoltage : 41|11@1+ (0.5,0) [0|0] "" Vector__XXX
 SG_ CMPD_inputHVCurrent : 32|9@1+ (0.1,0) [0|0] "" Vector__XXX
 SG_ CMPD_inputHVPower : 21|11@1+ (10,0) [0|0] "" Vector__XXX
 SG_ CMPD_speedDuty : 11|10@1+ (0.1,0) [0|0] "" Vector__XXX
 SG_ CMPD_speedRPM : 0|11@1+ (10,0) [0|0] "" Vector__XXX

BO_ 680 EPBL_status: 8 Vector__XXX
 SG_ EPBL_statusChecksum : 56|8@1+ (1,0) [0|0] "" Vector__XXX
 SG_ EPBL_statusCounter : 52|4@1+ (1,0) [0|0] "" Vector__XXX
 SG_ EPBL_blockDrive : 51|1@1+ (1,0) [0|0] "" Vector__XXX
 SG_ EPBL_bothDisconnected : 50|1@1+ (1,0) [0|0] "" Vector__XXX
 SG_ EPBL_winchModeAvailable : 49|1@1+ (1,0) [0|0] "" Vector__XXX
 SG_ EPBL_hornRequest : 48|1@1+ (1,0) [0|0] "" Vector__XXX
 SG_ EPBL_okToPark : 47|1@1+ (1,0) [0|0] "" Vector__XXX
 SG_ EPBL_espPowerRequest : 46|1@1+ (1,0) [0|0] "" Vector__XXX
 SG_ EPBL_showStalkFaultedOnUi : 45|1@1+ (1,0) [0|0] "" Vector__XXX
 SG_ EPBL_autonomyBehavior : 43|2@1+ (1,0) [0|0] "" Vector__XXX
 SG_ EPBL_uiWinchModeLvStatus : 33|2@1+ (1,0) [0|0] "" Vector__XXX
 SG_ EPBL_showUiGearShifter : 32|1@1+ (1,0) [0|0] "" Vector__XXX
 SG_ EPBL_brakeDiscWipeRequest : 30|2@1+ (1,0) [0|0] "" Vector__XXX
 SG_ EPBL_uiParkAvailable : 28|2@1+ (1,0) [0|0] "" Vector__XXX
 SG_ EPBL_cdpRequest : 27|1@1+ (1,0) [0|0] "" Vector__XXX
 SG_ EPBL_winchModePending : 26|1@1+ (1,0) [0|0] "" Vector__XXX
 SG_ EPBL_winchModePermissive : 25|1@1+ (1,0) [0|0] "" Vector__XXX
 SG_ EPBL_updateMode : 24|1@1+ (1,0) [0|0] "" Vector__XXX
 SG_ EPBL_winchModeActive : 23|1@1+ (1,0) [0|0] "" Vector__XXX
 SG_ EPBL_uiWinchModeMiscBlocking : 22|1@1+ (1,0) [0|0] "" Vector__XXX
 SG_ EPBL_requestUserConfirmation : 21|1@1+ (1,0) [0|0] "" Vector__XXX
 SG_ EPBL_brakeConfirmedPressed : 20|1@1+ (1,0) [0|0] "" Vector__XXX
 SG_ EPBL_epbConfigMismatch : 19|1@1+ (1,0) [0|0] "" Vector__XXX
 SG_ EPBL_brakeLight : 18|1@1+ (1,0) [0|0] "" Vector__XXX
 SG_ EPBL_summonEnabled : 17|1@1+ (1,0) [0|0] "" Vector__XXX
 SG_ EPBL_redundantBrakingEnabled : 16|1@1+ (1,0) [0|0] "" Vector__XXX
 SG_ EPBL_contactorCycleNotNeededForWinchEntry : 15|1@1+ (1,0) [0|0] "" Vector__XXX
 SG_ EPBL_telltale : 12|3@1+ (1,0) [0|0] "" Vector__XXX
 SG_ EPBL_chimeRequest : 9|3@1+ (1,0) [0|0] "" Vector__XXX
 SG_ EPBL_systemCdpAvailable : 8|1@1+ (1,0) [0|0] "" Vector__XXX
 SG_ EPBL_driverIsLeavingAnySpeed : 7|1@1+ (1,0) [0|0] "" Vector__XXX
 SG_ EPBL_driverIsLeaving : 6|1@1+ (1,0) [0|0] "" Vector__XXX
 SG_ EPBL_freeRollModeStatus : 4|2@1+ (1,0) [0|0] "" Vector__XXX
 SG_ EPBL_systemStatus : 0|4@1+ (1,0) [0|0] "" Vector__XXX

BO_ 682 EPBL_autonomyHealth: 3 Vector__XXX
 SG_ EPBL_ah_checksum : 16|8@1+ (1,0) [0|0] "" Vector__XXX
 SG_ EPBL_ah_counter : 12|4@1+ (1,0) [0|0] "" Vector__XXX
 SG_ EPBL_ah_redundantBrakingAvailable : 8|1@1+ (1,0) [0|0] "" Vector__XXX
 SG_ EPBL_ah_readiness : 6|2@1+ (1,0) [0|0] "" Vector__XXX
 SG_ EPBL_ah_unitParkingAvailability : 3|3@1+ (1,0) [0|0] "" Vector__XXX
 SG_ EPBL_ah_speedSupport : 0|3@1+ (1,0) [0|0] "" Vector__XXX

BO_ 691 VCRIGHT_logging1Hz: 8 VEH
 SG_ VCRIGHT_rightHeatOvertempProtect m10 : 62|1@1+ (1,0) [0|1] ""  X
 SG_ VCRIGHT_leftHeatOvertempProtect m10 : 61|1@1+ (1,0) [0|1] ""  X
 SG_ VCRIGHT_defrostAirflowBlocked m3 : 57|1@1+ (1,0) [0|1] ""  X
 SG_ VCRIGHT_cabinTempBreathLevel m1 : 56|8@1+ (0.5,-40) [-40|80] "C"  X
 SG_ VCRIGHT_cabinTempTopPadAir m9 : 56|8@1+ (0.6,-40) [-40|100] "C"  X
 SG_ VCRIGHT_evapDryingRoutineRuntime m10 : 56|5@1+ (2,0) [0|60] ""  X
 SG_ VCRIGHT_floorAirflowBlocked m3 : 56|1@1+ (1,0) [0|1] ""  X
 SG_ VCRIGHT_hvacIntakeEndStop m7 : 56|8@1+ (0.02,0) [0|5] "V"  X
 SG_ VCRIGHT_hvacIntakeVoltage m6 : 56|8@1+ (0.02,0) [0|5] "V"  X
 SG_ VCRIGHT_hvacIntakeZeroStop m8 : 56|8@1+ (0.02,0) [0|5] "V"  X
 SG_ VCRIGHT_solarLoadOnVehicle m4 : 56|8@1+ (4,0) [0|1020] "W/m2"  X
 SG_ VCRIGHT_RHPanelAirflowBlocked m3 : 55|1@1+ (1,0) [0|1] ""  X
 SG_ VCRIGHT_LHPanelAirflowBlocked m3 : 54|1@1+ (1,0) [0|1] ""  X
 SG_ VCRIGHT_hvacQdotLimitedRight m3 : 53|1@1+ (1,0) [0|1] ""  X
 SG_ VCRIGHT_hvacQdotLimitedLeft m3 : 52|1@1+ (1,0) [0|1] ""  X
 SG_ VCRIGHT_cabinTempInteriorSunnyL3 m9 : 48|8@1+ (0.6,-40) [-40|100] "C"  X
 SG_ VCRIGHT_cabinTempSideGlassRight m1 : 48|8@1+ (0.5,-40) [-40|80] "C"  X
 SG_ VCRIGHT_hvacAirflowReason m3 : 48|4@1+ (1,0) [0|14] ""  X
 SG_ VCRIGHT_hvacLowerModeEndStop m7 : 48|8@1+ (0.02,0) [0|5] "V"  X
 SG_ VCRIGHT_hvacLowerModeVoltage m6 : 48|8@1+ (0.02,0) [0|5] "V"  X
 SG_ VCRIGHT_hvacLowerModeZeroStop m8 : 48|8@1+ (0.02,0) [0|5] "V"  X
 SG_ VCRIGHT_ptcHeaterPwrDemandRight m2 : 48|8@1+ (20,0) [0|5000] "W"  X
 SG_ VCRIGHT_solarLoadLeftOccupant m4 : 48|7@1+ (2,0) [0|254] "W/m2"  X
 SG_ VCRIGHT_evapCondensationRate m10 : 47|9@1- (0.007,0) [-1|1] "g/s"  X
 SG_ VCRIGHT_cabinTempInteriorL3 m9 : 40|8@1+ (0.5,-40) [-40|80] "C"  X
 SG_ VCRIGHT_cabinTempInteriorSunnyL2 m0 : 40|8@1+ (0.6,-40) [-40|100] "C"  X
 SG_ VCRIGHT_cabinTempSideGlassLeft m1 : 40|8@1+ (0.5,-40) [-40|80] "C"  X
 SG_ VCRIGHT_evapLoadInRecirc m5 : 40|8@1+ (35,0) [0|8000] "W"  X
 SG_ VCRIGHT_evapWaterMass m10 : 40|7@1+ (6,0) [0|380] "Grams"  X
 SG_ VCRIGHT_hvacMassflowTarget m3 : 40|8@1+ (1,0) [0|200] "g/s"  X
 SG_ VCRIGHT_hvacUpperModeEndStop m7 : 40|8@1+ (0.02,0) [0|5] "V"  X
 SG_ VCRIGHT_hvacUpperModeVoltage m6 : 40|8@1+ (0.02,0) [0|5] "V"  X
 SG_ VCRIGHT_hvacUpperModeZeroStop m8 : 40|8@1+ (0.02,0) [0|5] "V"  X
 SG_ VCRIGHT_ptcHeaterPwrDemandLeft m2 : 40|8@1+ (20,0) [0|5000] "W"  X
 SG_ VCRIGHT_solarLoadRightOccupant m4 : 40|7@1+ (2,0) [0|254] "W/m2"  X
 SG_ VCRIGHT_cloudinessProbability m9 : 33|7@1+ (1,0) [0|100] "%"  X
 SG_ VCRIGHT_cabinTempInteriorSunny m1 : 32|8@1+ (0.6,-40) [-40|100] "C"  X
 SG_ VCRIGHT_convectionDeliveredRight m4 : 32|8@1+ (2,-254) [-254|256] "W/m2"  X
 SG_ VCRIGHT_evapLoadInFresh m5 : 32|8@1+ (35,0) [0|8000] "W"  X
 SG_ VCRIGHT_hvacAirFlowModeRow2 m3 : 32|3@1+ (1,0) [0|7] ""  X
 SG_ VCRIGHT_hvacCabOvrheatProtAllowe m9 : 32|1@1+ (1,0) [0|1] ""  X
 SG_ VCRIGHT_hvacRHVaneEndStop m7 : 32|8@1+ (0.02,0) [0|5] "V"  X
 SG_ VCRIGHT_hvacRHVaneVoltage m6 : 32|8@1+ (0.02,0) [0|5] "V"  X
 SG_ VCRIGHT_hvacRHVaneZeroStop m8 : 32|8@1+ (0.02,0) [0|5] "V"  X
 SG_ VCRIGHT_tempIncarCabinMid m0 : 32|8@1+ (0.5,-40) [-40|85] "C"  X
 SG_ VCRIGHT_hvacCabinPurgeAllowed m9 : 31|1@1+ (1,0) [0|1] ""  X
 SG_ VCRIGHT_tempHtrSurfaceModeledR m10 : 31|9@1+ (0.3,-40) [-40|105] "C"  X
 SG_ VCRIGHT_hvacCabOvrheatProtActive m9 : 30|1@1+ (1,0) [0|1] ""  X
 SG_ VCRIGHT_hvacAirFlowModeRow1 m3 : 29|3@1+ (1,0) [0|7] ""  X
 SG_ VCRIGHT_hvacCabinPurgeActive m9 : 29|1@1+ (1,0) [0|1] ""  X
 SG_ VCRIGHT_wattsHeaterRightTotal m2 : 26|10@1+ (5,0) [0|4000] "W"  X
 SG_ VCRIGHT_cabinTempInterior m1 : 24|8@1+ (0.5,-40) [-40|80] "C"  X
 SG_ VCRIGHT_cabinTempInteriorL2 m0 : 24|8@1+ (0.5,-40) [-40|80] "C"  X
 SG_ VCRIGHT_convectionDeliveredLeft m4 : 24|8@1+ (2,-254) [-254|256] "W/m2"  X
 SG_ VCRIGHT_hvacAutoTransitionReason m3 : 24|5@1+ (1,0) [0|19] ""  X
 SG_ VCRIGHT_hvacLHVaneEndStop m7 : 24|8@1+ (0.02,0) [0|5] "V"  X
 SG_ VCRIGHT_hvacLHVaneVoltage m6 : 24|8@1+ (0.02,0) [0|5] "V"  X
 SG_ VCRIGHT_hvacLHVaneZeroStop m8 : 24|8@1+ (0.02,0) [0|5] "V"  X
 SG_ VCRIGHT_tempHtrSurfaceModeledL m10 : 22|9@1+ (0.3,-40) [-40|105] "C"  X
 SG_ VCRIGHT_solarLoadOnVehFiltered m9 : 21|8@1+ (4,0) [0|1020] "W/m2"  X
 SG_ VCRIGHT_cabinTempWindshield m1 : 16|8@1+ (0.5,-40) [-40|80] "C"  X
 SG_ VCRIGHT_convectionTargetRight m4 : 16|8@1+ (2,-254) [-254|256] "W/m2"  X
 SG_ VCRIGHT_hvacQdotFeedforward m5 : 16|16@1+ (1,-32767) [-32767|32767] "W"  X
 SG_ VCRIGHT_hvacRHBleedEndStop m7 : 16|8@1+ (0.02,0) [0|5] "V"  X
 SG_ VCRIGHT_hvacRHBleedVoltage m6 : 16|8@1+ (0.02,0) [0|5] "V"  X
 SG_ VCRIGHT_hvacRHBleedZeroStop m8 : 16|8@1+ (0.02,0) [0|5] "V"  X
 SG_ VCRIGHT_hvacSetTempActualRight m3 : 16|8@1+ (0.1,15) [15|28] "C"  X
 SG_ VCRIGHT_tempIncarCabinDeep m0 : 16|8@1+ (0.5,-40) [-40|85] "C"  X
 SG_ VCRIGHT_wattsHeaterLeftTotal m2 : 16|10@1+ (5,0) [0|4000] "W"  X
 SG_ VCRIGHT_cabinTempFanCurrent m9 : 15|6@1- (0.001,0) [-0.01|0.05] "A"  X
 SG_ VCRIGHT_cabinTempFanOutput m9 : 14|1@1+ (1,0) [0|1] ""  X
 SG_ VCRIGHT_tempDuctModeledRight m10 : 13|9@1+ (0.3,-40) [-40|105] "C"  X
 SG_ VCRIGHT_ptcHeaterReqAirpathBlock m5 : 12|1@1+ (1,0) [0|1] ""  X
 SG_ VCRIGHT_ptcHeaterRAirPathBlocked m5 : 11|1@1+ (1,0) [0|1] ""  X
 SG_ VCRIGHT_ptcHeaterLAirPathBlocked m5 : 10|1@1+ (1,0) [0|1] ""  X
 SG_ VCRIGHT_ptcHeaterNoHighVoltage m5 : 9|1@1+ (1,0) [0|1] ""  X
 SG_ VCRIGHT_cabinTempGlassRoof m1 : 8|8@1+ (0.5,-40) [-40|80] "C"  X
 SG_ VCRIGHT_convectionTargetLeft m4 : 8|8@1+ (2,-254) [-254|256] "W/m2"  X
 SG_ VCRIGHT_hvacLHBleedEndStop m7 : 8|8@1+ (0.02,0) [0|5] "V"  X
 SG_ VCRIGHT_hvacLHBleedVoltage m6 : 8|8@1+ (0.02,0) [0|5] "V"  X
 SG_ VCRIGHT_hvacLHBleedZeroStop m8 : 8|8@1+ (0.02,0) [0|5] "V"  X
 SG_ VCRIGHT_hvacSetTempActualLeft m3 : 8|8@1+ (0.1,15) [15|28] "C"  X
 SG_ VCRIGHT_ptcHeaterNoUiRequest m5 : 8|1@1+ (1,0) [0|1] ""  X
 SG_ VCRIGHT_tempIncarCabinProbe m0 : 8|8@1+ (0.5,-40) [-40|85] "C"  X
 SG_ VCRIGHT_ptcHeaterHvacActNotReady m5 : 7|1@1+ (1,0) [0|1] ""  X
 SG_ VCRIGHT_ptcHeaterNoAirflow m5 : 6|1@1+ (1,0) [0|1] ""  X
 SG_ VCRIGHT_ptcHeaterTempDuctFault m5 : 5|1@1+ (1,0) [0|1] ""  X
 SG_ VCRIGHT_filterLifeBlowerTorque m9 : 4|10@1+ (0.006,-1.5) [-1.5|4.5] "Nm"  X
 SG_ VCRIGHT_pcbaTemperature m2 : 4|11@1+ (0.125,-40) [-40|150] "C"  X
 SG_ VCRIGHT_ptcHeaterTempDuctHigh m5 : 4|1@1+ (1,0) [0|1] ""  X
 SG_ VCRIGHT_tempDuctModeledLeft m10 : 4|9@1+ (0.3,-40) [-40|105] "C"  X
 SG_ VCRIGHT_logging1HzIndex M : 0|5@1+ (1,0) [0|11] ""  X

BO_ 692 PCS_dcdcRailStatus: 6 Vector__XXX
 SG_ PCS_dcdcLvOutputCurrent : 32|13@1- (0.1,0) [0|0] "" Vector__XXX
 SG_ PCS_dcdcHvBusVolt : 16|14@1+ (0.1,0) [0|0] "" Vector__XXX
 SG_ PCS_dcdcLvBusVolt : 0|13@1+ (0.01,0) [0|0] "" Vector__XXX

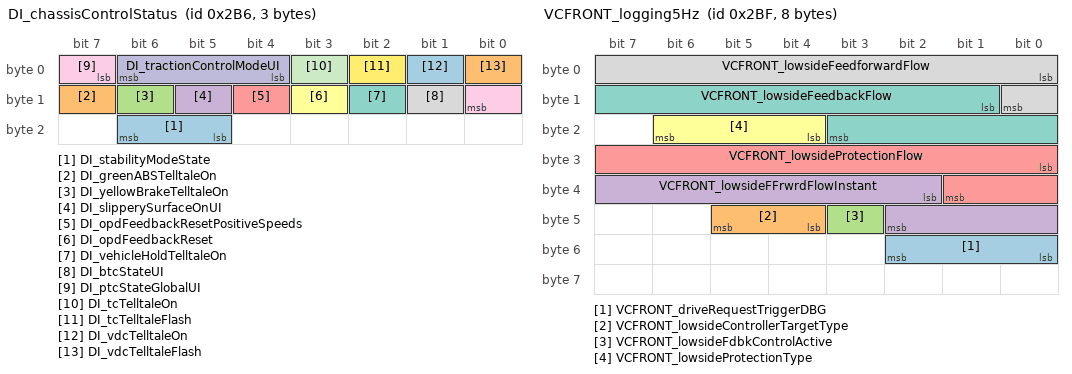
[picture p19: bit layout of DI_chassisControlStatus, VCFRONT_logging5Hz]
BO_ 694 DI_chassisControlStatus: 3 Vector__XXX
 SG_ DI_stabilityModeState : 21|2@1+ (1,0) [0|0] "" Vector__XXX
 SG_ DI_greenABSTelltaleOn : 15|1@1+ (1,0) [0|0] "" Vector__XXX
 SG_ DI_yellowBrakeTelltaleOn : 14|1@1+ (1,0) [0|0] "" Vector__XXX
 SG_ DI_slipperySurfaceOnUI : 13|1@1+ (1,0) [0|0] "" Vector__XXX
 SG_ DI_opdFeedbackResetPositiveSpeeds : 12|1@1+ (1,0) [0|0] "" Vector__XXX
 SG_ DI_opdFeedbackReset : 11|1@1+ (1,0) [0|0] "" Vector__XXX
 SG_ DI_vehicleHoldTelltaleOn : 10|1@1+ (1,0) [0|0] "" Vector__XXX
 SG_ DI_btcStateUI : 9|1@1+ (1,0) [0|0] "" Vector__XXX
 SG_ DI_ptcStateGlobalUI : 7|2@1+ (1,0) [0|0] "" Vector__XXX
 SG_ DI_tractionControlModeUI : 4|3@1+ (1,0) [0|0] "" Vector__XXX
 SG_ DI_tcTelltaleOn : 3|1@1+ (1,0) [0|0] "" Vector__XXX
 SG_ DI_tcTelltaleFlash : 2|1@1+ (1,0) [0|0] "" Vector__XXX
 SG_ DI_vdcTelltaleOn : 1|1@1+ (1,0) [0|0] "" Vector__XXX
 SG_ DI_vdcTelltaleFlash : 0|1@1+ (1,0) [0|0] "" Vector__XXX

BO_ 701 CP_dcPowerLimits: 4 Vector__XXX
 SG_ CP_evseMaxDcPowerLimitValid : 30|1@1+ (1,0) [0|0] "" Vector__XXX
 SG_ CP_evseInstantDcPowerLimitValid : 29|1@1+ (1,0) [0|0] "" Vector__XXX
 SG_ CP_evseMaxDcPowerLimit : 16|13@1+ (0.25,0) [0|0] "" Vector__XXX
 SG_ CP_evseInstantDcPowerLimit : 0|13@1+ (0.25,0) [0|0] "" Vector__XXX

BO_ 702 FC_limitsHighPower: 8 Vector__XXX
 SG_ FC_minVoltageLimit_exp : 54|3@1- (1,0) [0|0] "" Vector__XXX
 SG_ FC_currentLimit_exp : 51|3@1- (1,0) [0|0] "" Vector__XXX
 SG_ FC_powerLimit_exp : 48|3@1- (1,0) [0|0] "" Vector__XXX
 SG_ FC_minVoltageLimit_value : 32|16@1- (1,0) [0|0] "" Vector__XXX
 SG_ FC_currentLimit_value : 16|16@1- (1,0) [0|0] "" Vector__XXX
 SG_ FC_powerLimit_value : 0|16@1- (1,0) [0|0] "" Vector__XXX

BO_ 703 VCFRONT_logging5Hz: 8 Vector__XXX
 SG_ VCFRONT_driveRequestTriggerDBG : 48|3@1+ (1,0) [0|0] "" Vector__XXX
 SG_ VCFRONT_lowsideControllerTargetType : 44|2@1+ (1,0) [0|0] "" Vector__XXX
 SG_ VCFRONT_lowsideFdbkControlActive : 43|1@1+ (1,0) [0|0] "" Vector__XXX
 SG_ VCFRONT_lowsideFFrwrdFlowInstant : 34|9@1+ (0.2,0) [0|0] "" Vector__XXX
 SG_ VCFRONT_lowsideProtectionFlow : 24|10@1+ (0.1,0) [0|0] "" Vector__XXX
 SG_ VCFRONT_lowsideProtectionType : 20|3@1+ (1,0) [0|0] "" Vector__XXX
 SG_ VCFRONT_lowsideFeedbackFlow : 9|11@1- (0.1,0) [0|0] "" Vector__XXX
 SG_ VCFRONT_lowsideFeedforwardFlow : 0|9@1+ (0.2,0) [0|0] "" Vector__XXX

BO_ 706 VCLEFT_windowStatus: 8 Vector__XXX
 SG_ VCLEFT_windowCalibratedLR m0 : 63|1@1+ (1,0) [0|0] "" Vector__XXX
 SG_ VCLEFT_windowSpeedTableStatusLR m1 : 62|2@1+ (1,0) [0|0] "" Vector__XXX
 SG_ VCLEFT_windowSpeedTableStatusLF m1 : 60|2@1+ (1,0) [0|0] "" Vector__XXX
 SG_ VCLEFT_windowVehGearStateLR m1 : 58|2@1+ (1,0) [0|0] "" Vector__XXX
 SG_ VCLEFT_windowVehGearStateLF m1 : 56|2@1+ (1,0) [0|0] "" Vector__XXX
 SG_ VCLEFT_windowPositionLR m0 : 54|9@1- (1.25,265) [0|0] "" Vector__XXX
 SG_ VCLEFT_windowPositionStateLR m1 : 52|3@1+ (1,0) [0|0] "" Vector__XXX
 SG_ VCLEFT_windowPositionStateLF m1 : 49|3@1+ (1,0) [0|0] "" Vector__XXX
 SG_ VCLEFT_windowCurrentLR m0 : 48|6@1- (0.5,0) [0|0] "" Vector__XXX
 SG_ VCLEFT_windowCtrlUnavailableLR m1 : 45|3@1+ (1,0) [0|0] "" Vector__XXX
 SG_ VCLEFT_windowControlStateLR m1 : 42|2@1+ (1,0) [0|0] "" Vector__XXX
 SG_ VCLEFT_windowDutyLR m0 : 40|6@1- (5,0) [0|0] "" Vector__XXX
 SG_ VCLEFT_windowCtrlUnavailableLF m1 : 38|3@1+ (1,0) [0|0] "" Vector__XXX
 SG_ VCLEFT_windowControlStateLF m1 : 35|2@1+ (1,0) [0|0] "" Vector__XXX
 SG_ VCLEFT_windowStateLR m0 : 33|4@1+ (1,0) [0|0] "" Vector__XXX
 SG_ VCLEFT_windowCalibratedLF m0 : 32|1@1+ (1,0) [0|0] "" Vector__XXX
 SG_ VCLEFT_windowStopReqReasonLR m1 : 31|4@1+ (1,0) [0|0] "" Vector__XXX
 SG_ VCLEFT_windowStopReasonLR m1 : 28|3@1+ (1,0) [0|0] "" Vector__XXX
 SG_ VCLEFT_windowThermalModeLR m1 : 26|2@1+ (1,0) [0|0] "" Vector__XXX
 SG_ VCLEFT_windowPositionLF m0 : 22|9@1- (1.25,265) [0|0] "" Vector__XXX
 SG_ VCLEFT_windowThermalTCLR m1 : 18|8@1+ (1,0) [0|0] "" Vector__XXX
 SG_ VCLEFT_windowCurrentLF m0 : 16|6@1- (0.5,0) [0|0] "" Vector__XXX
 SG_ VCLEFT_windowStopReqReasonLF m1 : 14|4@1+ (1,0) [0|0] "" Vector__XXX
 SG_ VCLEFT_windowTrimClearActiveRequest m0 : 14|2@1+ (1,0) [0|0] "" Vector__XXX
 SG_ VCLEFT_windowStopReasonLF m1 : 11|3@1+ (1,0) [0|0] "" Vector__XXX
 SG_ VCLEFT_windowThermalModeLF m1 : 9|2@1+ (1,0) [0|0] "" Vector__XXX
 SG_ VCLEFT_windowDutyLF m0 : 8|6@1- (5,0) [0|0] "" Vector__XXX
 SG_ VCLEFT_windowTrimClearMoveRequest m0 : 5|2@1+ (1,0) [0|0] "" Vector__XXX
 SG_ VCLEFT_windowStateLF m0 : 1|4@1+ (1,0) [0|0] "" Vector__XXX
 SG_ VCLEFT_windowThermalTCLF m1 : 1|8@1+ (1,0) [0|0] "" Vector__XXX
 SG_ VCLEFT_windowStatusIndex M : 0|1@1+ (1,0) [0|0] "" Vector__XXX

BO_ 707 VCRIGHT_windowStatus: 8 Vector__XXX
 SG_ VCRIGHT_windowCalibratedRR m0 : 63|1@1+ (1,0) [0|0] "" Vector__XXX
 SG_ VCRIGHT_windowSpeedTableStatusRR m1 : 62|2@1+ (1,0) [0|0] "" Vector__XXX
 SG_ VCRIGHT_windowSpeedTableStatusRF m1 : 60|2@1+ (1,0) [0|0] "" Vector__XXX
 SG_ VCRIGHT_windowVehGearStateRR m1 : 58|2@1+ (1,0) [0|0] "" Vector__XXX
 SG_ VCRIGHT_windowVehGearStateRF m1 : 56|2@1+ (1,0) [0|0] "" Vector__XXX
 SG_ VCRIGHT_windowPositionRR m0 : 54|9@1- (1.25,265) [0|0] "" Vector__XXX
 SG_ VCRIGHT_windowPositionStateRR m1 : 52|3@1+ (1,0) [0|0] "" Vector__XXX
 SG_ VCRIGHT_windowPositionStateRF m1 : 49|3@1+ (1,0) [0|0] "" Vector__XXX
 SG_ VCRIGHT_windowCurrentRR m0 : 48|6@1- (0.5,0) [0|0] "" Vector__XXX
 SG_ VCRIGHT_windowCtrlUnavailableRR m1 : 45|3@1+ (1,0) [0|0] "" Vector__XXX
 SG_ VCRIGHT_windowControlStateRR m1 : 42|2@1+ (1,0) [0|0] "" Vector__XXX
 SG_ VCRIGHT_windowDutyRR m0 : 40|6@1- (5,0) [0|0] "" Vector__XXX
 SG_ VCRIGHT_windowCtrlUnavailableRF m1 : 38|3@1+ (1,0) [0|0] "" Vector__XXX
 SG_ VCRIGHT_windowControlStateRF m1 : 35|2@1+ (1,0) [0|0] "" Vector__XXX
 SG_ VCRIGHT_windowStateRR m0 : 33|4@1+ (1,0) [0|0] "" Vector__XXX
 SG_ VCRIGHT_windowCalibratedRF m0 : 32|1@1+ (1,0) [0|0] "" Vector__XXX
 SG_ VCRIGHT_windowStopReqReasonRR m1 : 31|4@1+ (1,0) [0|0] "" Vector__XXX
 SG_ VCRIGHT_windowStopReasonRR m1 : 28|3@1+ (1,0) [0|0] "" Vector__XXX
 SG_ VCRIGHT_windowThermalModeRR m1 : 26|2@1+ (1,0) [0|0] "" Vector__XXX
 SG_ VCRIGHT_windowPositionRF m0 : 22|9@1- (1.25,265) [0|0] "" Vector__XXX
 SG_ VCRIGHT_windowThermalTCRR m1 : 18|8@1+ (1,0) [0|0] "" Vector__XXX
 SG_ VCRIGHT_windowCurrentRF m0 : 16|6@1- (0.5,0) [0|0] "" Vector__XXX
 SG_ VCRIGHT_windowStopReqReasonRF m1 : 14|4@1+ (1,0) [0|0] "" Vector__XXX
 SG_ VCRIGHT_windowTrimClearActiveRequest m0 : 14|2@1+ (1,0) [0|0] "" Vector__XXX
 SG_ VCRIGHT_windowStopReasonRF m1 : 11|3@1+ (1,0) [0|0] "" Vector__XXX
 SG_ VCRIGHT_windowThermalModeRF m1 : 9|2@1+ (1,0) [0|0] "" Vector__XXX
 SG_ VCRIGHT_windowDutyRF m0 : 8|6@1- (5,0) [0|0] "" Vector__XXX
 SG_ VCRIGHT_windowTrimClearMoveRequest m0 : 5|2@1+ (1,0) [0|0] "" Vector__XXX
 SG_ VCRIGHT_windowStateRF m0 : 1|4@1+ (1,0) [0|0] "" Vector__XXX
 SG_ VCRIGHT_windowThermalTCRF m1 : 1|8@1+ (1,0) [0|0] "" Vector__XXX
 SG_ VCRIGHT_windowStatusIndex M : 0|1@1+ (1,0) [0|0] "" Vector__XXX

CM_ BO_ 258 "ESP32-DualCAN Model3_VEH. Seen on this car: 8-byte frames; fit good (bits covered 100%, mux 100%, ranges 100%).";
CM_ BO_ 259 "ESP32-DualCAN Model3_VEH. Seen on this car: 8-byte frames; fit good (bits covered 100%, mux 100%, ranges 100%).";
CM_ BO_ 264 "DashKit DBC. Seen on this car: 8-byte frames; fit good (bits covered 97%, mux 100%, ranges 100%, checksum 100%). read by the app or firmware; DashKit names kept.";
CM_ BO_ 275 "ESP32-DualCAN Model3_VEH. Seen on this car: 3-byte frames; fit poor (bits covered 0%, mux 100%, ranges 100%).";
CM_ BO_ 280 "ESP32-DualCAN Model3_VEH. Seen on this car: 8-byte frames; fit good (bits covered 100%, mux 100%, ranges 100%, checksum 100%). read by the app or firmware.";
CM_ BO_ 281 "ESP32-DualCAN Model3_VEH. Seen on this car: 4-byte frames; fit ok (bits covered 80%, mux 100%, ranges 100%).";
CM_ BO_ 290 "ESP32-DualCAN Model3_VEH. Seen on this car: 8-byte frames; fit good (bits covered 100%, mux 100%, ranges 100%).";
CM_ BO_ 291 "ESP32-DualCAN Model3_VEH. Seen on this car: 8-byte frames; fit good (bits covered 100%, mux 100%, ranges 100%).";
CM_ BO_ 294 "ESP32-DualCAN Model3_VEH. Seen on this car: 5-byte frames; fit ok (bits covered 100%, mux 100%, ranges 100%, checksum 100%).";
CM_ BO_ 296 "ESP32-DualCAN Model3_VEH. Seen on this car: 6-byte frames; fit ok (bits covered 100%, mux 100%, ranges 100%).";
CM_ BO_ 297 "ESP32-DualCAN Model3_VEH. Seen on this car: 8-byte frames; fit good (bits covered 100%, mux 100%, ranges 100%). read by the app or firmware.";
CM_ BO_ 306 "DashKit DBC. Seen on this car: 6-byte frames; fit weak (bits covered 98%, mux 100%, ranges 100%). read by the app or firmware; DashKit names kept.; 1 signals past the 6 bytes this car sends were left out";
CM_ BO_ 313 "ESP32-DualCAN Model3_VEH. Seen on this car: 1-byte frames; fit poor (bits covered 0%, mux 100%, ranges 100%).";
CM_ BO_ 317 "DashKit DBC. Seen on this car: 6-byte frames; fit good (bits covered 100%, mux 100%, ranges 100%).";
CM_ BO_ 322 "ESP32-DualCAN Model3_VEH. Seen on this car: 8-byte frames; fit good (bits covered 100%, mux 100%, ranges 100%). read by the app or firmware.";
CM_ BO_ 470 "ESP32-DualCAN Model3_VEH. Seen on this car: 8-byte frames; fit good (bits covered 100%, mux 100%, ranges 100%).";
CM_ BO_ 472 "ESP32-DualCAN Model3_VEH. Seen on this car: 8-byte frames; fit good (bits covered 100%, mux 100%, ranges 100%, checksum 100%).";
CM_ BO_ 473 "ESP32-DualCAN Model3_VEH. Seen on this car: 3-byte frames; fit poor (bits covered 0%, mux 100%, ranges 100%).; 5 signals past the 3 bytes this car sends were left out";
CM_ BO_ 474 "ESP32-DualCAN Model3_VEH. Seen on this car: 8-byte frames; fit good (bits covered 100%, mux 100%, ranges 100%).";
CM_ BO_ 485 "ESP32-DualCAN Model3_VEH. Seen on this car: 8-byte frames; fit good (bits covered 100%, mux 100%, ranges 100%, checksum 100%).";
CM_ BO_ 504 "ESP32-DualCAN Model3_VEH. Seen on this car: 4-byte frames; fit poor (bits covered 0%, mux 100%, ranges 100%).";
CM_ BO_ 505 "ESP32-DualCAN Model3_VEH. Seen on this car: 8-byte frames; fit good (bits covered 100%, mux 100%, ranges 100%).";
CM_ BO_ 506 "ESP32-DualCAN Model3_VEH. Seen on this car: 3-byte frames; fit poor (bits covered 0%, mux 100%, ranges 100%).";
CM_ BO_ 507 "ESP32-DualCAN Model3_VEH. Seen on this car: 8-byte frames; fit weak (bits covered 0%, mux 100%, ranges 100%).";
CM_ BO_ 513 "ESP32-DualCAN Model3_VEH. Seen on this car: 8-byte frames; fit good (bits covered 100%, mux 100%, ranges 100%).";
CM_ BO_ 516 "ESP32-DualCAN Model3_VEH. Seen on this car: 8-byte frames; fit weak (bits covered 0%, mux 100%, ranges 100%).";
CM_ BO_ 522 "ESP32-DualCAN Model3_VEH. Seen on this car: 6-byte frames; fit ok (bits covered 100%, mux 100%, ranges 100%).";
CM_ BO_ 524 "ESP32-DualCAN Model3_VEH. Seen on this car: 8-byte frames; fit good (bits covered 100%, mux 100%, ranges 100%).";
CM_ BO_ 526 "ESP32-DualCAN Model3_VEH. Seen on this car: 3-byte frames; fit ok (bits covered 100%, mux 100%, ranges 100%, checksum 100%).";
CM_ BO_ 529 "ESP32-DualCAN Model3_VEH. Seen on this car: 6-byte frames; fit ok (bits covered 100%, mux 100%, ranges 100%, checksum 100%).";
CM_ BO_ 530 "DashKit DBC. Seen on this car: 8-byte frames; fit good (bits covered 97%, mux 100%, ranges 100%). read by the app or firmware; DashKit names kept; corrected from the logs.";
CM_ BO_ 531 "DashKit DBC. Seen on this car: 3-byte frames; fit good (bits covered 100%, mux 100%, ranges 100%, checksum 100%).";
CM_ BO_ 532 "ESP32-DualCAN Model3_VEH. Seen on this car: 8-byte frames; fit good (bits covered 100%, mux 100%, ranges 100%).";
CM_ BO_ 533 "ESP32-DualCAN Model3_VEH. Seen on this car: 1-byte frames; fit ok (bits covered 100%, mux 100%, ranges 100%).";
CM_ BO_ 535 "ESP32-DualCAN Model3_VEH. Seen on this car: 8-byte frames; fit good (bits covered 100%, mux 100%, ranges 100%).";
CM_ BO_ 536 "ESP32-DualCAN Model3_VEH. Seen on this car: 5-byte frames; fit ok (bits covered 100%, mux 100%, ranges 100%, checksum 100%).";
CM_ BO_ 537 "ESP32-DualCAN Model3_VEH. Seen on this car: 7-byte frames; fit ok (bits covered 100%, mux 100%, ranges 100%). read by the app or firmware.";
CM_ BO_ 541 "ESP32-DualCAN Model3_VEH. Seen on this car: 8-byte frames; fit good (bits covered 100%, mux 100%, ranges 100%).";
CM_ BO_ 545 "ESP32-DualCAN Model3_VEH. Seen on this car: 8-byte frames; fit good (bits covered 100%, mux 100%, ranges 100%, checksum 100%).";
CM_ BO_ 548 "ESP32-DualCAN Model3_VEH. Seen on this car: 8-byte frames; fit good (bits covered 100%, mux 100%, ranges 100%).";
CM_ BO_ 549 "ESP32-DualCAN Model3_VEH. Seen on this car: 4-byte frames; fit ok (bits covered 100%, mux 100%, ranges 100%).";
CM_ BO_ 552 "ESP32-DualCAN Model3_VEH. Seen on this car: 8-byte frames; fit good (bits covered 100%, mux 100%, ranges 100%, checksum 100%). read by the app or firmware.";
CM_ BO_ 553 "ESP32-DualCAN Model3_VEH. Seen on this car: 3-byte frames; fit ok (bits covered 100%, mux 100%, ranges 100%).";
CM_ BO_ 554 "ESP32-DualCAN Model3_VEH. Seen on this car: 4-byte frames; fit ok (bits covered 100%, mux 100%, ranges 100%).";
CM_ BO_ 555 "ESP32-DualCAN Model3_VEH. Seen on this car: 8-byte frames; fit good (bits covered 100%, mux 100%, ranges 100%).";
CM_ BO_ 562 "ESP32-DualCAN Model3_VEH. Seen on this car: 8-byte frames; fit good (bits covered 100%, mux 100%, ranges 100%).";
CM_ BO_ 564 "ESP32-DualCAN Model3_VEH. Seen on this car: 8-byte frames; fit ok (bits covered 100%, mux 100%, ranges 100%, checksum 0%).";
CM_ BO_ 568 "ESP32-DualCAN Model3_VEH. Seen on this car: 8-byte frames; fit good (bits covered 100%, mux 100%, ranges 100%, checksum 100%).";
CM_ BO_ 577 "ESP32-DualCAN Model3_VEH. Seen on this car: 7-byte frames; fit ok (bits covered 100%, mux 100%, ranges 100%).";
CM_ BO_ 578 "ESP32-DualCAN Model3_VEH. Seen on this car: 4-byte frames; fit ok (bits covered 100%, mux 100%, ranges 100%).";
CM_ BO_ 579 "ESP32-DualCAN Model3_VEH. Seen on this car: 8-byte frames; fit good (bits covered 100%, mux 100%, ranges 100%).";
CM_ BO_ 580 "ESP32-DualCAN Model3_VEH. Seen on this car: 8-byte frames; fit good (bits covered 100%, mux 100%, ranges 100%).";
CM_ BO_ 585 "ESP32-DualCAN Model3_VEH. Seen on this car: 4-byte frames; fit ok (bits covered 100%, mux 100%, ranges 100%). read by the app or firmware.";
CM_ BO_ 586 "ESP32-DualCAN Model3_VEH. Seen on this car: 1-byte frames; fit ok (bits covered 100%, mux 100%, ranges 100%).";
CM_ BO_ 594 "DashKit DBC. Seen on this car: 8-byte frames; fit good (bits covered 84%, mux 100%, ranges 100%). read by the app or firmware; DashKit names kept.";
CM_ BO_ 595 "ESP32-DualCAN Model3_VEH. Seen on this car: 8-byte frames; fit ok (bits covered 100%, mux 48%, ranges 100%).";
CM_ BO_ 599 "DashKit DBC. Seen on this car: 8-byte frames; fit ok (bits covered 58%, mux 100%, ranges 100%, checksum 100%). read by the app or firmware; DashKit names kept.";
CM_ BO_ 602 "ESP32-DualCAN Model3_VEH. Seen on this car: 6-byte frames; fit ok (bits covered 100%, mux 100%, ranges 100%).";
CM_ BO_ 603 "ESP32-DualCAN Model3_VEH. Seen on this car: 8-byte frames; fit ok (bits covered 100%, mux 100%, ranges 100%, checksum 0%).";
CM_ BO_ 605 "ESP32-DualCAN Model3_VEH. Seen on this car: 8-byte frames; fit ok (bits covered 79%, mux 100%, ranges 100%).";
CM_ BO_ 609 "ESP32-DualCAN Model3_VEH. Seen on this car: 8-byte frames; fit ok (bits covered 100%, mux 100%, ranges 100%, checksum 0%).";
CM_ BO_ 610 "ESP32-DualCAN Model3_VEH. Seen on this car: 8-byte frames; fit good (bits covered 100%, mux 100%, ranges 100%).";
CM_ BO_ 611 "ESP32-DualCAN Model3_VEH. Seen on this car: 8-byte frames; fit good (bits covered 100%, mux 100%, ranges 100%).";
CM_ BO_ 612 "ESP32-DualCAN Model3_VEH. Seen on this car: 6-byte frames; fit ok (bits covered 100%, mux 100%, ranges 100%).";
CM_ BO_ 614 "ESP32-DualCAN Model3_VEH. Seen on this car: 8-byte frames; fit good (bits covered 100%, mux 100%, ranges 100%).";
CM_ BO_ 616 "ESP32-DualCAN Model3_VEH. Seen on this car: 5-byte frames; fit ok (bits covered 100%, mux 100%, ranges 100%).";
CM_ BO_ 626 "ESP32-DualCAN Model3_VEH. Seen on this car: 8-byte frames; fit good (bits covered 100%, mux 100%, ranges 100%).";
CM_ BO_ 627 "ESP32-DualCAN Model3_VEH. Seen on this car: 8-byte frames; fit good (bits covered 100%, mux 100%, ranges 100%). read by the app or firmware.";
CM_ BO_ 630 "ESP32-DualCAN Model3_VEH. Seen on this car: 8-byte frames; fit good (bits covered 100%, mux 100%, ranges 100%).";
CM_ BO_ 633 "ESP32-DualCAN Model3_VEH. Seen on this car: 8-byte frames; fit ok (bits covered 100%, mux 100%, ranges 100%, checksum 0%).";
CM_ BO_ 637 "ESP32-DualCAN Model3_VEH. Seen on this car: 8-byte frames; fit good (bits covered 100%, mux 100%, ranges 100%).";
CM_ BO_ 642 "ESP32-DualCAN Model3_VEH. Seen on this car: 8-byte frames; fit good (bits covered 100%, mux 100%, ranges 100%).";
CM_ BO_ 643 "ESP32-DualCAN Model3_VEH. Seen on this car: 6-byte frames; fit poor (bits covered 0%, mux 100%, ranges 100%).";
CM_ BO_ 644 "ESP32-DualCAN Model3_VEH. Seen on this car: 8-byte frames; fit good (bits covered 100%, mux 100%, ranges 100%, checksum 100%).";
CM_ BO_ 645 "ESP32-DualCAN Model3_VEH. Seen on this car: 8-byte frames; fit good (bits covered 100%, mux 100%, ranges 100%).";
CM_ BO_ 646 "ESP32-DualCAN Model3_VEH. Seen on this car: 5-byte frames; fit ok (bits covered 100%, mux 100%, ranges 100%).";
CM_ BO_ 648 "ESP32-DualCAN Model3_VEH. Seen on this car: 8-byte frames; fit good (bits covered 100%, mux 100%, ranges 100%, checksum 100%). read by the app or firmware.";
CM_ BO_ 649 "ESP32-DualCAN Model3_VEH. Seen on this car: 8-byte frames; fit good (bits covered 100%, mux 100%, ranges 100%).";
CM_ BO_ 658 "ESP32-DualCAN Model3_VEH. Seen on this car: 8-byte frames; fit good (bits covered 100%, mux 100%, ranges 100%).";
CM_ BO_ 659 "ESP32-DualCAN Model3_VEH. Seen on this car: 8-byte frames; fit good (bits covered 100%, mux 100%, ranges 100%, checksum 100%).";
CM_ BO_ 660 "ESP32-DualCAN Model3_VEH. Seen on this car: 8-byte frames; fit good (bits covered 100%, mux 100%, ranges 100%).";
CM_ BO_ 661 "ESP32-DualCAN Model3_VEH. Seen on this car: 8-byte frames; fit good (bits covered 100%, mux 100%, ranges 100%).";
CM_ BO_ 664 "ESP32-DualCAN Model3_VEH. Seen on this car: 4-byte frames; fit ok (bits covered 100%, mux 100%, ranges 100%).";
CM_ BO_ 667 "ESP32-DualCAN Model3_VEH. Seen on this car: 5-byte frames; fit weak (bits covered 69%, mux 100%, ranges 100%).";
CM_ BO_ 669 "ESP32-DualCAN Model3_VEH. Seen on this car: 5-byte frames; fit ok (bits covered 100%, mux 100%, ranges 100%).";
CM_ BO_ 670 "ESP32-DualCAN Model3_VEH. Seen on this car: 8-byte frames; fit good (bits covered 100%, mux 100%, ranges 100%, checksum 100%).";
CM_ BO_ 673 "ESP32-DualCAN Model3_VEH. Seen on this car: 6-byte frames; fit ok (bits covered 100%, mux 100%, ranges 100%).";
CM_ BO_ 674 "ESP32-DualCAN Model3_VEH. Seen on this car: 7-byte frames; fit poor (bits covered 0%, mux 100%, ranges 100%).";
CM_ BO_ 675 "ESP32-DualCAN Model3_VEH. Seen on this car: 8-byte frames; fit good (bits covered 100%, mux 100%, ranges 100%).";
CM_ BO_ 676 "ESP32-DualCAN Model3_VEH. Seen on this car: 8-byte frames; fit good (bits covered 100%, mux 100%, ranges 100%).";
CM_ BO_ 678 "ESP32-DualCAN Model3_VEH. Seen on this car: 8-byte frames; fit good (bits covered 100%, mux 100%, ranges 100%).";
CM_ BO_ 679 "ESP32-DualCAN Model3_VEH. Seen on this car: 8-byte frames; fit good (bits covered 100%, mux 100%, ranges 100%).";
CM_ BO_ 680 "ESP32-DualCAN Model3_VEH. Seen on this car: 8-byte frames; fit good (bits covered 100%, mux 100%, ranges 100%, checksum 100%).";
CM_ BO_ 682 "ESP32-DualCAN Model3_VEH. Seen on this car: 3-byte frames; fit ok (bits covered 100%, mux 100%, ranges 100%, checksum 100%).";
CM_ BO_ 691 "DashKit DBC. Seen on this car: 8-byte frames; fit ok (bits covered 100%, mux 72%, ranges 94%). read by the app or firmware; DashKit names kept; corrected from the logs.";
CM_ BO_ 692 "ESP32-DualCAN Model3_VEH. Seen on this car: 6-byte frames; fit ok (bits covered 100%, mux 100%, ranges 100%).";
CM_ BO_ 694 "ESP32-DualCAN Model3_VEH. Seen on this car: 3-byte frames; fit ok (bits covered 100%, mux 100%, ranges 100%).";
CM_ BO_ 701 "ESP32-DualCAN Model3_VEH. Seen on this car: 4-byte frames; fit ok (bits covered 100%, mux 100%, ranges 100%).";
CM_ BO_ 702 "ESP32-DualCAN Model3_VEH. Seen on this car: 8-byte frames; fit good (bits covered 100%, mux 100%, ranges 100%).";
CM_ BO_ 703 "ESP32-DualCAN Model3_VEH. Seen on this car: 8-byte frames; fit good (bits covered 100%, mux 100%, ranges 100%).";
CM_ BO_ 706 "ESP32-DualCAN Model3_VEH. Seen on this car: 8-byte frames; fit good (bits covered 100%, mux 100%, ranges 100%).";
CM_ BO_ 707 "ESP32-DualCAN Model3_VEH. Seen on this car: 8-byte frames; fit good (bits covered 100%, mux 100%, ranges 100%).";
BA_DEF_ BO_  "GenMsgCycleTime" INT 0 65535;
BA_DEF_DEF_  "GenMsgCycleTime" 0;
BA_ "GenMsgCycleTime" BO_ 264 10;
BA_ "GenMsgCycleTime" BO_ 306 10;
BA_ "GenMsgCycleTime" BO_ 530 100;
BA_ "GenMsgCycleTime" BO_ 531 500;
BA_ "GenMsgCycleTime" BO_ 594 100;
BA_ "GenMsgCycleTime" BO_ 599 20;
BA_ "GenMsgCycleTime" BO_ 691 90;
VAL_ 258 VCLEFT_mirrorHeatState 0 "SNA" 1 "ON" 2 "OFF" 3 "OFF_UNAVAILABLE" 4 "FAULT" ;
VAL_ 258 VCLEFT_mirrorRecallState 0 "INIT" 1 "RECALLING_AXIS_1" 2 "RECALLING_AXIS_2" 3 "RECALLING_COMPLETE" 4 "RECALLING_FAILED" 5 "RECALLING_STOPPED" ;
VAL_ 258 VCLEFT_mirrorFoldState 0 "UNKNOWN" 1 "FOLDED" 2 "UNFOLDED" 3 "FOLDING" 4 "UNFOLDING" ;
VAL_ 258 VCLEFT_mirrorState 0 "IDLE" 1 "TILT_X" 2 "TILT_Y" 3 "FOLD_UNFOLD" 4 "RECALL" ;
VAL_ 258 VCLEFT_rearLatchStatus 0 "SNA" 1 "OPENED" 2 "CLOSED" 3 "CLOSING" 4 "OPENING" 5 "AJAR" 6 "TIMEOUT" 7 "DEFAULT" 8 "FAULT" ;
VAL_ 258 VCLEFT_frontLatchStatus 0 "SNA" 1 "OPENED" 2 "CLOSED" 3 "CLOSING" 4 "OPENING" 5 "AJAR" 6 "TIMEOUT" 7 "DEFAULT" 8 "FAULT" ;
VAL_ 258 VCLEFT_doorClosureStatusRear 0 "UNKNOWN" 1 "OPENED" 2 "CLOSED" ;
VAL_ 258 VCLEFT_doorClosureStatusFront 0 "UNKNOWN" 1 "OPENED" 2 "CLOSED" ;
VAL_ 259 VCRIGHT_mirrorRecallState 0 "INIT" 1 "RECALLING_AXIS_1" 2 "RECALLING_AXIS_2" 3 "RECALLING_COMPLETE" 4 "RECALLING_FAILED" 5 "RECALLING_STOPPED" ;
VAL_ 259 VCRIGHT_trunkLatchStatus 0 "SNA" 1 "OPENED" 2 "CLOSED" 3 "CLOSING" 4 "OPENING" 5 "AJAR" 6 "TIMEOUT" 7 "DEFAULT" 8 "FAULT" ;
VAL_ 259 VCRIGHT_mirrorFoldState 0 "UNKNOWN" 1 "FOLDED" 2 "UNFOLDED" 3 "FOLDING" 4 "UNFOLDING" ;
VAL_ 259 VCRIGHT_mirrorState 0 "IDLE" 1 "TILT_X" 2 "TILT_Y" 3 "FOLD_UNFOLD" 4 "RECALL" ;
VAL_ 259 VCRIGHT_rearLatchStatus 0 "SNA" 1 "OPENED" 2 "CLOSED" 3 "CLOSING" 4 "OPENING" 5 "AJAR" 6 "TIMEOUT" 7 "DEFAULT" 8 "FAULT" ;
VAL_ 259 VCRIGHT_frontLatchStatus 0 "SNA" 1 "OPENED" 2 "CLOSED" 3 "CLOSING" 4 "OPENING" 5 "AJAR" 6 "TIMEOUT" 7 "DEFAULT" 8 "FAULT" ;
VAL_ 259 VCRIGHT_doorClosureStatusRear 0 "UNKNOWN" 1 "OPENED" 2 "CLOSED" ;
VAL_ 259 VCRIGHT_doorClosureStatusFront 0 "UNKNOWN" 1 "OPENED" 2 "CLOSED" ;
VAL_ 264 DI_slavePedalPos 255 "SNA" ;
VAL_ 264 DI_axleSpeed -32768 "SNA" ;
VAL_ 264 DI_torqueActual -4096 "SNA" ;
VAL_ 264 DI_torqueCommand -4096 "SNA" ;
VAL_ 280 DI_vehicleAcceleration 4294965248 "SNA" ;
VAL_ 280 DI_trackModeState 0 "UNAVAILABLE" 1 "AVAILABLE" 2 "ON" ;
VAL_ 280 DI_keepDrivePowerStateRequest 0 "NO_REQUEST" 1 "KEEP_ALIVE" ;
VAL_ 280 DI_epbRequest 0 "NO_REQUEST" 1 "PARK" 2 "UNPARK" ;
VAL_ 280 DI_tractionControlMode 0 "NORMAL" 1 "SLIP_START" 2 "DEV_MODE_1" 3 "DEV_MODE_2" 4 "ROLLS_MODE" 5 "DYNO_MODE" 6 "OFFROAD_ASSIST" ;
VAL_ 280 DI_accelPedalPos 255 "SNA" ;
VAL_ 280 DI_hvilSystemStatus 0 "DISABLED" 1 "OPEN" 2 "CLOSED" 3 "SNA" ;
VAL_ 280 DI_driveBlocked 0 "NONE" 1 "FRUNK" 2 "PROX" 3 "FALCON" ;
VAL_ 280 DI_gear 0 "INVALID" 1 "P" 2 "R" 3 "N" 4 "D" 7 "SNA" ;
VAL_ 280 DI_brakePedalState 0 "OFF" 1 "ON" 2 "INVALID" ;
VAL_ 280 DI_systemState 0 "UNAVAILABLE" 1 "IDLE" 2 "STANDBY" 3 "FAULT" 4 "ABORT" 5 "ENABLE" ;
VAL_ 280 DI_immobilizerState 0 "INIT_SNA" 1 "REQUEST" 2 "AUTHENTICATING" 3 "DISARMED" 4 "IDLE" 5 "RESET" 6 "FAULT" ;
VAL_ 290 VCLEFT_rearDoorState 0 "UNKNOWN" 1 "CLOSED" 2 "WAIT_FOR_SHORT_DROP" 3 "RELEASING_LATCH" 4 "OPEN" 5 "AJAR" 6 "INIT" ;
VAL_ 290 VCLEFT_frontDoorState 0 "UNKNOWN" 1 "CLOSED" 2 "WAIT_FOR_SHORT_DROP" 3 "RELEASING_LATCH" 4 "OPEN" 5 "AJAR" 6 "INIT" ;
VAL_ 291 VCRIGHT_rearDoorState 0 "UNKNOWN" 1 "CLOSED" 2 "WAIT_FOR_SHORT_DROP" 3 "RELEASING_LATCH" 4 "OPEN" 5 "AJAR" 6 "INIT" ;
VAL_ 291 VCRIGHT_frontDoorState 0 "UNKNOWN" 1 "CLOSED" 2 "WAIT_FOR_SHORT_DROP" 3 "RELEASING_LATCH" 4 "OPEN" 5 "AJAR" 6 "INIT" ;
VAL_ 294 DIR_keepAliveRequest 0 "NO_REQUEST" 1 "KEEP_ALIVE" ;
VAL_ 294 DIR_targetFluxMode 0 "OPTIMUM" 1 "FS" 2 "FW" ;
VAL_ 296 DI_proximity 0 "SNA" 1 "DISCONNECTED" 2 "UNLATCHED" 3 "LATCHED" ;
VAL_ 296 DI_vehicleSpeedLimitReason 0 "NONE" 1 "DRIVE_UNIT_LIMIT" 2 "FACTORY_LOW_BRAKE_FLUID" 3 "FACTORY_MODE" 4 "SERVICE_MODE" 5 "MAX_CAR_CONFIG" 6 "SPINDOWN_LEARNING" 7 "TRAILER_MODE" 8 "TAS" 9 "LOAD_SHED" 10 "FRUNK_OPEN" 11 "USER" ;
VAL_ 296 DI_vehicleSpeedLimit 511 "SNA" ;
VAL_ 296 DI_vehicleSpeedLimitType 0 "NONE" 1 "USER" 2 "POWERTRAIN" ;
VAL_ 297 SCCM_steeringAngleValidity 0 "INVALID" 1 "VALID" 2 "INIT" 3 "SNA" ;
VAL_ 297 SCCM_steeringAngle 16383 "SNA" ;
VAL_ 297 SCCM_steeringAngleSensorStatus 0 "OK" 1 "INIT" 2 "ERROR" 3 "ERROR_INIT" ;
VAL_ 306 BMS_currentUnfiltered -16384 "SNA" ;
VAL_ 306 BMS_packCurrent -16384 "SNA" ;
VAL_ 317 CP_evseChargeType 2 "AC_CHARGER_PRESENT" 1 "DC_CHARGER_PRESENT" 0 "NO_CHARGER_PRESENT" ;
VAL_ 317 CP_chargeShutdownRequest 2 "EMERGENCY_SHUTDOWN_REQUESTED" 1 "GRACEFUL_SHUTDOWN_REQUESTED" 0 "NO_SHUTDOWN_REQUESTED" ;
VAL_ 317 CP_hvChargeStatus 1 "CP_CHARGE_CONNECTED" 5 "CP_CHARGE_ENABLED" 6 "CP_CHARGE_FAULTED" 0 "CP_CHARGE_INACTIVE" 2 "CP_CHARGE_STANDBY" 4 "CP_EVSE_TEST_PASSED" 3 "CP_EXT_EVSE_TEST_ACTIVE" ;
VAL_ 322 VCLEFT_liftgateLatchRequest 0 "NONE" 1 "CINCH" 2 "RELEASE_V2" 3 "FORCE_RELEASE" 4 "RESET" ;
VAL_ 322 VCLEFT_liftgateRequestSource 0 "NONE" 1 "MCU_SWITCH" 2 "EXTERIOR" 3 "SHUTFACE" 4 "KEY_TRUNK_BUTTON" 5 "VCSEC_COMMAND" 6 "PARTY" 7 "UDS" ;
VAL_ 322 VCLEFT_liftgatePhysicalChimeRequest 0 "NONE" 1 "ONE_SHORT" 2 "TWO_SHORT" 3 "THREE_SHORT" 4 "ONE_LONG" ;
VAL_ 322 VCLEFT_liftgateUIChimeRequest 0 "NONE" 1 "ONE_SHORT" 2 "TWO_SHORT" 3 "THREE_SHORT" 4 "ONE_LONG" ;
VAL_ 322 VCLEFT_liftgateMvmntNotAllowedCondition 0 "NONE" 1 "LOW_12V" 2 "VEHICLE_AT_SPEED" 3 "UNCALIBRATED" 4 "EXTERIOR_PRESS_AT_MAX_OPEN" 5 "LOCKED" ;
VAL_ 322 VCLEFT_liftgateStoppingCondition 0 "NONE" 1 "PINCH" 2 "OBSTACLE_STALL" 3 "LOW_12V" 4 "STATE_TIMEOUT" 5 "VEHICLE_AT_SPEED" 6 "OBSTACLE_CURRENT" 7 "OBSTACLE_TRAJ_POS" 8 "OBSTACLE_TRAJ_VEL" 9 "UNCALIBRATED" 10 "LATCH_FAULT" 11 "OBSTACLE_CURRENT_SPIKE" 12 "COUNT" ;
VAL_ 322 VCLEFT_liftgateState 0 "INIT" 1 "OFF" 2 "BACKOFF" 3 "OPENING" 4 "CLOSING" 5 "CLOSED" 6 "LATCH_OPENING" 7 "LATCH_CLOSING" 8 "NOT_INSTALLED" 9 "UNKNOWN" 10 "LATCH_EXIT" 11 "END_OF_TRAVEL" 12 "LATCH_ENTRY" 13 "PARTY_DANCE" ;
VAL_ 322 VCLEFT_liftgateStatusIndex 0 "0" 1 "1" 2 "INVALID" ;
VAL_ 470 DIR_currentLimit 8191 "SNA" ;
VAL_ 472 PMR_hvilSupplyState 0 "NOT_AVAILABLE" 1 "INACTIVE" 2 "ACTIVE" ;
VAL_ 472 PMR_axleSpeedQF 0 "NOT_QUALIFIED" 1 "QUALIFIED" ;
VAL_ 472 PMR_hvilStatus 0 "DISABLED" 1 "OPEN" 2 "CLOSED" 3 "SNA" ;
VAL_ 472 PMR_torqueCommand 4294963200 "SNA" ;
VAL_ 472 PMR_soptState 0 "INIT" 1 "PSTG_BRING_UP" 2 "ASC_TEST" 3 "CURRENT_TEST" 4 "TEST_PASSED" 5 "TEST_SKIPPED" 6 "TEST_FAILED" 7 "SNA" ;
VAL_ 485 PM_hvilSystemStatus 0 "DISABLED" 1 "OPEN" 2 "CLOSED" 3 "SNA" ;
VAL_ 485 PM_autoparkState 0 "UNAVAILABLE" 1 "STANDBY" 2 "STARTED" 3 "ACTIVE" 4 "COMPLETE" 5 "PAUSED" 6 "ABORTED" 7 "RESUMED" 8 "UNPARK_COMPLETE" 9 "SELFPARK_STARTED" 15 "SNA" ;
VAL_ 485 PM_cruiseState 0 "UNAVAILABLE" 1 "STANDBY" 2 "ENABLED" 3 "STANDSTILL" 4 "OVERRIDE" 5 "FAULT" 6 "PRE_FAULT" 7 "PRE_CANCEL" ;
VAL_ 504 VCLEFT_DBG_LM_SelfTest_Status 0 "IDLE" 1 "RX" ;
VAL_ 504 VCLEFT_DBG_USS_SelfTest_Status 0 "IDLE" 1 "RX" ;
VAL_ 504 VCLEFT_DBG_Eeprom_ST_Status 0 "IDLE" 1 "RX" ;
VAL_ 504 VCLEFT_DBG_Siren_ST_Status 0 "IDLE" 1 "RX" ;
VAL_ 504 VCLEFT_DBG_LM_Alarm_Status 0 "IDLE" 1 "RX" ;
VAL_ 504 VCLEFT_DBG_USS_Alarm_Status 0 "IDLE" 1 "RX" ;
VAL_ 504 VCLEFT_DBG_Veh_Settings_Status 0 "IDLE" 1 "RX" ;
VAL_ 504 VCLEFT_DBG_SelfTest_Status 0 "IDLE" 1 "RX" ;
VAL_ 504 VCLEFT_DBG_Suspensions_Status 0 "IDLE" 1 "RX" ;
VAL_ 504 VCLEFT_DBG_Window_Status 0 "IDLE" 1 "RX" ;
VAL_ 504 VCLEFT_DBG_Heater_Status 0 "IDLE" 1 "RX" ;
VAL_ 504 VCLEFT_DBG_Air_Cond_Status 0 "IDLE" 1 "RX" ;
VAL_ 504 VCLEFT_DBG_System_Status 0 "IDLE" 1 "RX" ;
VAL_ 505 VCSEC_chargeportRequestReason 0 "NONE" 1 "RKE" 2 "UHF" ;
VAL_ 505 VCSEC_snapshotRequested 0 "NONE" 1 "HANDLE_PULL_WITHOUT_AUTH" 2 "AUTHED_WITHOUT_HANDLE_PULL" 3 "AUTO_PRESENT_DOOR_CLOSE_TIMEOUT" 4 "AUTO_PRESENT_DOOR_CLOSE_WITHOUT_PEDESTRIAN_DETECTED" 5 "INTRUSION_DETECTED" 6 "TRIGGER_6" 7 "TRIGGER_7" 8 "TRIGGER_8" 9 "TRIGGER_9" 10 "TRIGGER_10" 11 "TRIGGER_11" 12 "TRIGGER_12" 13 "TRIGGER_13" 14 "TRIGGER_14" 15 "TRIGGER_15" ;
VAL_ 505 VCSEC_closeAllStatus 0 "NOT_AVAILABLE" 1 "AVAILABLE" 2 "CANCELABLE" ;
VAL_ 505 VCSEC_rearTrunkRequestReason 0 "REASON_NONE" 1 "REASON_RKE" 2 "REASON_CLOSE_ALL" 3 "REASON_AUTO_PRESENT" 4 "KEYFOB_UNLOCK_OPEN" 5 "UI_STOP_ALL" ;
VAL_ 505 VCSEC_rearRightRequestReason 0 "REASON_NONE" 1 "REASON_RKE" 2 "REASON_CLOSE_ALL" 3 "REASON_AUTO_PRESENT" 4 "KEYFOB_UNLOCK_OPEN" 5 "UI_STOP_ALL" ;
VAL_ 505 VCSEC_rearLeftRequestReason 0 "REASON_NONE" 1 "REASON_RKE" 2 "REASON_CLOSE_ALL" 3 "REASON_AUTO_PRESENT" 4 "KEYFOB_UNLOCK_OPEN" 5 "UI_STOP_ALL" ;
VAL_ 505 VCSEC_frontRightRequestReason 0 "REASON_NONE" 1 "REASON_RKE" 2 "REASON_CLOSE_ALL" 3 "REASON_AUTO_PRESENT" 4 "KEYFOB_UNLOCK_OPEN" 5 "UI_STOP_ALL" ;
VAL_ 505 VCSEC_frontLeftRequestReason 0 "REASON_NONE" 1 "REASON_RKE" 2 "REASON_CLOSE_ALL" 3 "REASON_AUTO_PRESENT" 4 "KEYFOB_UNLOCK_OPEN" 5 "UI_STOP_ALL" ;
VAL_ 505 VCSEC_rearTrunkClosureRequest 0 "NONE" 1 "MOVE" 2 "STOP" 3 "OPEN" 4 "QUICK_OPEN" 5 "OPEN_REDUCED" 6 "CLOSE" ;
VAL_ 505 VCSEC_rearRightClosureRequest 0 "NONE" 1 "MOVE" 2 "STOP" 3 "OPEN" 4 "QUICK_OPEN" 5 "OPEN_REDUCED" 6 "CLOSE" ;
VAL_ 505 VCSEC_rearLeftClosureRequest 0 "NONE" 1 "MOVE" 2 "STOP" 3 "OPEN" 4 "QUICK_OPEN" 5 "OPEN_REDUCED" 6 "CLOSE" ;
VAL_ 505 VCSEC_frontRightClosureRequest 0 "NONE" 1 "MOVE" 2 "STOP" 3 "OPEN" 4 "QUICK_OPEN" 5 "OPEN_REDUCED" 6 "CLOSE" ;
VAL_ 505 VCSEC_frontLeftClosureRequest 0 "NONE" 1 "MOVE" 2 "STOP" 3 "OPEN" 4 "QUICK_OPEN" 5 "OPEN_REDUCED" 6 "CLOSE" ;
VAL_ 505 VCSEC_chargePortRequest 0 "NONE" 1 "OPEN" 2 "CLOSE" 3 "SNA" ;
VAL_ 507 VCLEFT_TLCState_Reverse 0 "OFF_WITHOUT_LOAD" 1 "OFF_WITH_LOAD" 2 "ON_WITHOUT_LOAD" 3 "ON_WITH_LOAD" 4 "FAULT" 5 "SNA" ;
VAL_ 507 VCLEFT_TLCState_Fog 0 "OFF_WITHOUT_LOAD" 1 "OFF_WITH_LOAD" 2 "ON_WITHOUT_LOAD" 3 "ON_WITH_LOAD" 4 "FAULT" 5 "SNA" ;
VAL_ 507 VCLEFT_TLCState_Stop 0 "OFF_WITHOUT_LOAD" 1 "OFF_WITH_LOAD" 2 "ON_WITHOUT_LOAD" 3 "ON_WITH_LOAD" 4 "FAULT" 5 "SNA" ;
VAL_ 507 VCLEFT_TLCState_Tail 0 "OFF_WITHOUT_LOAD" 1 "OFF_WITH_LOAD" 2 "ON_WITHOUT_LOAD" 3 "ON_WITH_LOAD" 4 "FAULT" 5 "SNA" ;
VAL_ 507 VCLEFT_TLCState_RightTurn 0 "OFF_WITHOUT_LOAD" 1 "OFF_WITH_LOAD" 2 "ON_WITHOUT_LOAD" 3 "ON_WITH_LOAD" 4 "FAULT" 5 "SNA" ;
VAL_ 507 VCLEFT_TLCState_LeftTurn 0 "OFF_WITHOUT_LOAD" 1 "OFF_WITH_LOAD" 2 "ON_WITHOUT_LOAD" 3 "ON_WITH_LOAD" 4 "FAULT" 5 "SNA" ;
VAL_ 507 VCLEFT_TLCRightTurnVoltage 255 "SNA" ;
VAL_ 507 VCLEFT_TLCLeftTurnVoltage 255 "SNA" ;
VAL_ 507 VCLEFT_TLCTemperature 4294967168 "SNA" ;
VAL_ 507 VCLEFT_TLCStatusIndex 0 "0" 1 "1" 2 "INVALID" ;
VAL_ 513 VCFRONT_ccrExvState 0 "UNINIT" 1 "INIT_OPEN" 2 "INIT_CLOSE" 3 "READY" 4 "FAULTED" 5 "WAIT" 6 "OVERDRIVING_SHUT" 7 "READY_SHUT" 8 "CALIB_CLOSE" 9 "CALIB_CLOSE_OVERDRIVE" ;
VAL_ 513 VCFRONT_recircExvState 0 "UNINIT" 1 "INIT_OPEN" 2 "INIT_CLOSE" 3 "READY" 4 "FAULTED" 5 "WAIT" 6 "OVERDRIVING_SHUT" 7 "READY_SHUT" 8 "CALIB_CLOSE" 9 "CALIB_CLOSE_OVERDRIVE" ;
VAL_ 513 VCFRONT_cclExvState 0 "UNINIT" 1 "INIT_OPEN" 2 "INIT_CLOSE" 3 "READY" 4 "FAULTED" 5 "WAIT" 6 "OVERDRIVING_SHUT" 7 "READY_SHUT" 8 "CALIB_CLOSE" 9 "CALIB_CLOSE_OVERDRIVE" ;
VAL_ 513 VCFRONT_evapExvState 0 "UNINIT" 1 "INIT_OPEN" 2 "INIT_CLOSE" 3 "READY" 4 "FAULTED" 5 "WAIT" 6 "OVERDRIVING_SHUT" 7 "READY_SHUT" 8 "CALIB_CLOSE" 9 "CALIB_CLOSE_OVERDRIVE" ;
VAL_ 513 VCFRONT_chillerExvState 0 "UNINIT" 1 "INIT_OPEN" 2 "INIT_CLOSE" 3 "READY" 4 "FAULTED" 5 "WAIT" 6 "OVERDRIVING_SHUT" 7 "READY_SHUT" 8 "CALIB_CLOSE" 9 "CALIB_CLOSE_OVERDRIVE" ;
VAL_ 513 VCFRONT_hpReqCoolantMode 0 "ANY" 1 "SERIES_NO_BYPASS" 2 "SERIES_BYPASS" 3 "PARALLEL" 4 "AMBIENT_SOURCE" ;
VAL_ 513 VCFRONT_lccExvState 0 "UNINIT" 1 "INIT_OPEN" 2 "INIT_CLOSE" 3 "READY" 4 "FAULTED" 5 "WAIT" 6 "OVERDRIVING_SHUT" 7 "READY_SHUT" 8 "CALIB_CLOSE" 9 "CALIB_CLOSE_OVERDRIVE" ;
VAL_ 513 VCFRONT_hpBatteryLoadType 0 "NONE" 1 "BATT_HEAT" 2 "BATT_COOL" ;
VAL_ 513 VCFRONT_hpCabinLoadType 0 "NONE" 1 "CC" 2 "REHEAT" 3 "EVAP" ;
VAL_ 513 VCFRONT_pressureRefrigLiquid 511 "SNA" ;
VAL_ 513 VCFRONT_hpBlendType 0 "NONE" 1 "PARTIAL" 2 "FULL" ;
VAL_ 513 VCFRONT_hpDominantLoad 0 "NONE" 1 "EVAP" 2 "CHILLER" 3 "LOW_BOTH" 4 "LCC" 5 "CC" 6 "HIGH_BOTH" ;
VAL_ 513 VCFRONT_hpLowSideHX 0 "NONE" 1 "CHILLER" 2 "EVAP" 3 "BOTH" ;
VAL_ 513 VCFRONT_hpHighSideHX 0 "NONE" 1 "LCC" 2 "CC" 3 "BOTH" ;
VAL_ 513 VCFRONT_compFaultSeverity 0 "NONE" 1 "LOW" 2 "MEDIUM" 3 "HIGH" ;
VAL_ 513 VCFRONT_coolantValveMode 0 "SERIES" 1 "PARALLEL" 2 "BLEND" 3 "AMBIENT_SOURCE" ;
VAL_ 513 VCFRONT_radiatorFanRPMActual 1023 "SNA" ;
VAL_ 513 VCFRONT_solenoidEvapState 0 "UNDEFINED" 1 "OPENED" 2 "CLOSED" 3 "FAULTED" ;
VAL_ 513 VCFRONT_exvState 0 "UNINIT" 1 "INIT_OPEN" 2 "INIT_CLOSE" 3 "READY" 4 "FAULTED" 5 "WAIT" 6 "OVERDRIVING_SHUT" 7 "READY_SHUT" 8 "CALIB_CLOSE" 9 "CALIB_CLOSE_OVERDRIVE" ;
VAL_ 513 VCFRONT_pumpPowertrainRPMActual 1023 "SNA" ;
VAL_ 513 VCFRONT_compressorState 0 "STANDBY" 1 "READY" 2 "RUNNING" 3 "FAULT" ;
VAL_ 513 VCFRONT_pumpBatteryRPMActual 1023 "SNA" ;
VAL_ 513 VCFRONT_loggingAndVitals10HzIndex 0 "TARGETS_AND_ACTUALS_0" 1 "TARGETS_SENSORS_AND_ACTUALS_1" 2 "STATES_AND_SENSORS" 3 "EXV_FLOW" 4 "HP_AND_EXV_STATE" 5 "EXV_FLOW_TARGET" 6 "END" ;
VAL_ 516 PCS_hwVariantType 0 "48A_SINGLE_PHASE_VARIANT" 1 "32A_SINGLE_PHASE_VARIANT" 2 "THREE_PHASES_VARIANT" 3 "HW_VARIANT_TYPE_SNA" ;
VAL_ 516 PCS_chgMaxAcPowerAvailable 255 "SNA" ;
VAL_ 516 PCS_gridConfig 0 "SNA" 1 "SINGLE_PHASE" 2 "THREE_PHASE" 3 "THREE_PHASE_DELTA" ;
VAL_ 516 PCS_chgMainState 0 "INIT" 1 "IDLE" 2 "STARTUP" 3 "WAIT_FOR_LINE_VOLTAGE" 4 "QUALIFY_LINE_CONFIG" 5 "SYSTEM_CONFIG" 6 "ENABLE" 7 "SHUTDOWN" 8 "FAULTED" 9 "CLEAR_FAULTS" ;
VAL_ 522 HVP_fcLinkAllowedToEnergize 0 "NONE" 1 "AC" 2 "DC" ;
VAL_ 522 HVP_hvilDiag 0 "UNKNOWN" 1 "OK" 2 "CURRENT_SOURCE_OR_GROUND_LEAK_FAULT" 3 "INTERNAL_OPEN_FAULT" 4 "VEHICLE_OPEN_FAULT" 5 "PENTHOUSE_LID_OPEN_FAULT" 6 "UNKNOWN_LOCATION_OPEN_FAULT" 7 "VEHICLE_NODE_FAULT" 8 "NO_12V_SUPPLY" 9 "VEHICLE_OR_PENTHOUSE_LID_OPEN_FAULT" 10 "DI_STATUS_MISSING_FAULT" 11 "PM_STATUS_MISSING_FAULT" 12 "DI_OPEN_FAULT" 13 "PM_OPEN_FAULT" ;
VAL_ 522 HVP_packCtrsRequestStatus 0 "NOT_ACTIVE" 1 "ACTIVE" 2 "COMPLETED" ;
VAL_ 522 HVP_fcCtrsRequestStatus 0 "NOT_ACTIVE" 1 "ACTIVE" 2 "COMPLETED" ;
VAL_ 522 HVP_fcContactorSetState 0 "SNA" 1 "OPEN" 2 "CLOSING" 3 "BLOCKED" 4 "OPENING" 5 "CLOSED" 6 "PARTIAL_WELD" 7 "WELDED" 8 "POSITIVE_CLOSED" 9 "NEGATIVE_CLOSED" ;
VAL_ 522 HVP_fcContPositiveState 0 "SNA" 1 "OPEN" 2 "PRECHARGE" 3 "BLOCKED" 4 "PULLED_IN" 5 "OPENING" 6 "ECONOMIZED" 7 "WELDED" ;
VAL_ 522 HVP_fcContNegativeState 0 "SNA" 1 "OPEN" 2 "PRECHARGE" 3 "BLOCKED" 4 "PULLED_IN" 5 "OPENING" 6 "ECONOMIZED" 7 "WELDED" ;
VAL_ 522 HVP_packContactorSetState 0 "SNA" 1 "OPEN" 2 "CLOSING" 3 "BLOCKED" 4 "OPENING" 5 "CLOSED" 6 "PARTIAL_WELD" 7 "WELDED" 8 "POSITIVE_CLOSED" 9 "NEGATIVE_CLOSED" ;
VAL_ 522 HVP_packContPositiveState 0 "SNA" 1 "OPEN" 2 "PRECHARGE" 3 "BLOCKED" 4 "PULLED_IN" 5 "OPENING" 6 "ECONOMIZED" 7 "WELDED" ;
VAL_ 522 HVP_packContNegativeState 0 "SNA" 1 "OPEN" 2 "PRECHARGE" 3 "BLOCKED" 4 "PULLED_IN" 5 "OPENING" 6 "ECONOMIZED" 7 "WELDED" ;
VAL_ 524 VCRIGHT_hvacPerfTestState 0 "STOPPED" 1 "WAITING" 2 "BLOWING" ;
VAL_ 524 VCRIGHT_tempAmbientRaw 0 "SNA" ;
VAL_ 524 VCRIGHT_tempEvaporatorTarget 255 "SNA" ;
VAL_ 524 VCRIGHT_tempEvaporator 2047 "SNA" ;
VAL_ 529 RCM_pedProEDR2State 0 "EMPTY" 1 "STORED" 2 "LOCKED" 3 "UNAVAILABLE" ;
VAL_ 529 RCM_pedProEDR1State 0 "EMPTY" 1 "STORED" 2 "LOCKED" 3 "UNAVAILABLE" ;
VAL_ 529 RCM_driverOrientationInitStatus 0 "RCM_DRIVER_ORIENTATION_INIT_NOT_COMPLETE" 1 "RCM_DRIVER_ORIENTATION_MATCHED_LHD" 2 "RCM_DRIVER_ORIENTATION_MATCHED_RHD" 3 "RCM_DRIVER_ORIENTATION_MISMATCH_DEFAULT_LHD" 4 "RCM_DRIVER_ORIENTATION_MISMATCH_DEFAULT_RHD" 7 "SNA" ;
VAL_ 529 RCM_edr3State 0 "EMPTY" 1 "STORED" 2 "LOCKED" 3 "UNAVAILABLE" ;
VAL_ 529 RCM_imuOffsetLearnState 0 "OFFSET_LEARNING_OFF" 1 "SLOW_LEARNING_DISTANCE" 2 "FAST_LEARNING_TIME" 3 "OFFSETS_UNABLE_TO_LEARN" ;
VAL_ 529 RCM_keepPowerReason 0 "NO_KEEP_POWER_REQUEST" 1 "IN_IDLE_MODE" 2 "CRASH_ALGO_ACTIVE" 3 "EDR_STORING_TO_EEPROM" 4 "EDR_UPLOADING" 5 "CANNOT_POWER_DOWN" 6 "INITIALIZATION_PHASE" 7 "INVALID_POWER_OFF_REQUEST" 8 "KEEP_POWER_REASON_SNA" ;
VAL_ 529 RCM_edr2State 0 "EMPTY" 1 "STORED" 2 "LOCKED" 3 "UNAVAILABLE" ;
VAL_ 529 RCM_edr1State 0 "EMPTY" 1 "STORED" 2 "LOCKED" 3 "UNAVAILABLE" ;
VAL_ 529 RCM_seatTrackPositionPass 0 "RCM_SEAT_POSITION_NEAR" 1 "RCM_SEAT_POSITION_FAR" 2 "RCM_SEAT_POSITION_FAULTED" 3 "SNA" ;
VAL_ 529 RCM_seatTrackPositionDrvr 0 "RCM_SEAT_POSITION_NEAR" 1 "RCM_SEAT_POSITION_FAR" 2 "RCM_SEAT_POSITION_FAULTED" 3 "SNA" ;
VAL_ 529 RCM_vinLearnFlag 0 "RCM_VIN_NOT_STORED" 1 "RCM_VIN_STORED" 2 "RCM_VIN_STORED_MISMATCH" 3 "SNA" ;
VAL_ 529 RCM_alrSwitchStatus 0 "RCM_ALR_NOT_ENGAGED" 1 "RCM_ALR_ENGAGED" 2 "RCM_ALR_FAULTED" 3 "SNA" ;
VAL_ 529 RCM_airbagCutoffStatus 0 "RCM_PASSENGER_AIRBAG_ENABLED" 1 "RCM_PASSENGER_AIRBAG_DISABLED" 3 "SNA" ;
VAL_ 529 RCM_passAirbagIndicatorRequest 0 "RCM_PASSENGER_AIRBAG_INDICATOR_ON" 1 "RCM_PASSENGER_AIRBAG_INDICATOR_OFF" 3 "SNA" ;
VAL_ 529 RCM_warningIndicatorState 0 "RCM_WARNING_INDICATOR_OFF" 1 "RCM_WARNING_INDICATOR_ON" 3 "SNA" ;
VAL_ 529 RCM_armStatus 0 "RCM_UNARMED" 1 "RCM_ARMED" 2 "ARMED_WITH_NOFIRE_CAL" 3 "SNA" ;
VAL_ 530 BMS_ecuLogUploadRequest 0 "NONE" 1 "1" 2 "2" 3 "3" ;
VAL_ 530 BMS_chgPowerAvailable 2047 "BMS_chgPowerAvailable_SNA" ;
VAL_ 530 BMS_diLimpRequest 0 "NONE" 1 "WELDED" ;
VAL_ 530 BMS_uiChargeStatus 0 "DISCONNECTED" 1 "NO_POWER" 2 "ABOUT_TO_CHARGE" 3 "CHARGING" 4 "CHARGE_COMPLETE" 5 "CHARGE_STOPPED" ;
VAL_ 530 BMS_isolationResistance 1023 "BMS_isolationResistance_SNA" ;
VAL_ 530 BMS_hvState 0 "DOWN" 1 "COMING_UP" 2 "GOING_DOWN" 3 "UP_FOR_DRIVE" 4 "UP_FOR_CHARGE" 5 "UP_FOR_DC_CHARGE" 6 "UP" ;
VAL_ 530 BMS_state 0 "STANDBY" 1 "DRIVE" 2 "SUPPORT" 3 "CHARGE" 4 "FEIM" 5 "CLEAR_FAULT" 6 "FAULT" 7 "WELD" 8 "TEST" 9 "SNA" ;
VAL_ 530 BMS_contactorState 0 "SNA" 1 "OPEN" 2 "OPENING" 3 "CLOSING" 4 "CLOSED" 5 "WELDED" 6 "BLOCKED" ;
VAL_ 531 UI_cruiseSpeedCommand 0 "IDLE" 1 "INC_SHORT" 2 "INC_LONG" 3 "DEC_SHORT" 4 "DEC_LONG" 5 "SNAP" ;
VAL_ 531 UI_speedLimitTick 255 "SNA" ;
VAL_ 532 FC_postID 0 "MASTER" 1 "SLAVE" 2 "ID_2" 3 "ID_SNA" ;
VAL_ 532 FC_type 0 "SUPERCHARGER" 1 "CHADEMO" 2 "GB" 3 "CC_EVSE" 4 "COMBO" 5 "MC_EVSE" 6 "OTHER" 7 "SNA" ;
VAL_ 532 FC_statusCode 0 "NOTREADY_SNA" 1 "READY" 2 "UPDATE_IN_PROGRESS" 3 "DEPRECATED_3" 4 "DEPRECATED_4" 5 "INT_ISOACTIVE" 6 "EXT_ISOACTIVE" 7 "POST_OUT_OF_SERVICE" 13 "NOTCOMPATIBLE" 14 "MALFUNCTION" 15 "NODATA" ;
VAL_ 533 FC_externalIsolationResistance 255 "SNA" ;
VAL_ 535 FC_generation 0 "GENERATION_SNA" ;
VAL_ 535 FC_uiStopType 0 "SNA" 1 "TOGGLE" 2 "MOMENTARY" ;
VAL_ 535 FC_coolingType 0 "SNA" 1 "LIQUID" 2 "CONVECTION" ;
VAL_ 535 FC_brand 0 "SNA" 1 "TESLA" ;
VAL_ 535 FC_class 0 "SNA" 1 "SUPERCHARGER" 2 "URBANCHARGER" ;
VAL_ 535 FC_status3DataSelect 0 "Mux0" 1 "Mux1" ;
VAL_ 537 VCSEC_TPMSLocation0 0 "FL" 1 "FR" 2 "RL" 3 "RR" 4 "UNKNOWN" ;
VAL_ 537 VCSEC_TPMSLocation1 0 "FL" 1 "FR" 2 "RL" 3 "RR" 4 "UNKNOWN" ;
VAL_ 537 VCSEC_TPMSLocation2 0 "FL" 1 "FR" 2 "RL" 3 "RR" 4 "UNKNOWN" ;
VAL_ 537 VCSEC_TPMSLocation3 0 "FL" 1 "FR" 2 "RL" 3 "RR" 4 "UNKNOWN" ;
VAL_ 537 VCSEC_TPMSBatVoltage0 255 "SNA" ;
VAL_ 537 VCSEC_TPMSBatVoltage1 255 "SNA" ;
VAL_ 537 VCSEC_TPMSBatVoltage2 255 "SNA" ;
VAL_ 537 VCSEC_TPMSBatVoltage3 255 "SNA" ;
VAL_ 537 VCSEC_TPMSTemperature0 255 "SNA" ;
VAL_ 537 VCSEC_TPMSTemperature1 255 "SNA" ;
VAL_ 537 VCSEC_TPMSTemperature2 255 "SNA" ;
VAL_ 537 VCSEC_TPMSTemperature3 255 "SNA" ;
VAL_ 537 VCSEC_TPMSRecommendedColdPressureRear 255 "SNA" ;
VAL_ 537 VCSEC_TPMSPressure0 511 "SNA" ;
VAL_ 537 VCSEC_TPMSPressure1 511 "SNA" ;
VAL_ 537 VCSEC_TPMSPressure2 511 "SNA" ;
VAL_ 537 VCSEC_TPMSPressure3 511 "SNA" ;
VAL_ 537 VCSEC_TPMSRecommendedColdPressureFront 255 "SNA" ;
VAL_ 537 VCSEC_TPMSDataIndex 0 "0" 1 "1" 2 "2" 3 "3" 4 "RCP" 5 "4" 6 "5" 7 "6" 8 "7" 9 "8" 10 "9" ;
VAL_ 541 CP_teslaDcState 0 "INACTIVE" 1 "CONNECTED_CHARGE_BLOCKED" 2 "STANDBY" 3 "EXT_TESTS_ENABLED" 4 "EXT_TEST_ACTIVE" 5 "EXT_PRECHARGE_ACTIVE" 6 "ENABLED" 7 "EVSE_SHUTDOWN" 8 "VEH_SHUTDOWN" 9 "EMERGENCY_SHUTDOWN" 10 "FAULT" ;
VAL_ 541 CP_acChargeState 0 "INACTIVE" 1 "CONNECTED_CHARGE_BLOCKED" 2 "STANDBY" 3 "ENABLED" 4 "ONBOARD_CHARGER_SHUTDOWN" 5 "VEH_SHUTDOWN" 6 "FAULT" ;
VAL_ 541 CP_gbdcFailureReason 0 "FAILURE_NONE" 1 "ATTEMPTS_EXPIRED" 2 "SHUTDOWN_FAILURE" 3 "CRITICAL_FAILURE" ;
VAL_ 541 CP_gbdcStopChargeReason 0 "STOP_REASON_NONE" 1 "VEH_REQUESTED" 2 "EVSE_REQUESTED" 3 "COMMS_TIMEOUT" 4 "EVSE_FAULT" 5 "EVSE_CRITICAL_FAULT" 6 "LIVE_DISCONNECT" 7 "SUPERCHARGER_COMMS_TIMEOUT" ;
VAL_ 541 CP_gbState 0 "INACTIVE" 1 "WAIT_FOR_COMMS" 2 "COMMS_RECEIVED" 3 "HANDSHAKING_EXT_ISO" 4 "RECOGNITION" 5 "CHARGE_PARAM_CONFIG" 6 "VEH_PACK_PRECHARGE" 7 "READY_TO_CHARGE" 8 "CHARGING" 9 "STOP_CHARGE_REQUESTED" 10 "CHARGE_DISABLING" 11 "END_OF_CHARGE" 12 "ERROR_HANDLING" 13 "RETRY_CHARGE" 14 "FAULTED" 15 "TESTER_PRESENT" ;
VAL_ 541 CP_evseChargeType_UI 0 "NO_CHARGER_PRESENT" 1 "DC_CHARGER_PRESENT" 2 "AC_CHARGER_PRESENT" ;
VAL_ 541 CP_teslaSwcanState 0 "INACTIVE" 1 "ACCEPT" 2 "RECEIVE" 3 "ESTABLISHED" 4 "FAULT" 5 "GO_TO_SLEEP" 6 "OFFBOARD_UPDATE_IN_PROGRESS" ;
VAL_ 541 CP_iecPilotState 0 "B1" 1 "B2" 2 "B3" 3 "C1" 4 "C2" 5 "C3" 6 "E" 7 "F" 8 "NUM" 9 "SNA" ;
VAL_ 541 CP_cableType 0 "IEC" 1 "SAE" 2 "GB_AC" 3 "GB_DC" 4 "SNA" ;
VAL_ 541 CP_pilot 0 "NONE" 1 "FAULTED" 2 "LINE_CHARGE" 3 "FAST_CHARGE" 4 "IDLE" 5 "INVALID" 6 "UNUSED_6" 7 "SNA" ;
VAL_ 541 CP_proximity 0 "SNA" 1 "DISCONNECTED" 2 "UNLATCHED" 3 "LATCHED" ;
VAL_ 545 VCFRONT_uiHiCurrentLVState 0 "OFF" 1 "ON" 2 "GOING_DOWN" 3 "FAULT" ;
VAL_ 545 VCFRONT_espValveLVState 0 "OFF" 1 "ON" 2 "GOING_DOWN" 3 "FAULT" ;
VAL_ 545 VCFRONT_hcmlLVState 0 "OFF" 1 "ON" 2 "GOING_DOWN" 3 "FAULT" ;
VAL_ 545 VCFRONT_epasLVState 0 "OFF" 1 "ON" 2 "GOING_DOWN" 3 "FAULT" ;
VAL_ 545 VCFRONT_espLVState 0 "OFF" 1 "ON" 2 "GOING_DOWN" 3 "FAULT" ;
VAL_ 545 VCFRONT_parkLVState 0 "OFF" 1 "ON" 2 "GOING_DOWN" 3 "FAULT" ;
VAL_ 545 VCFRONT_vehiclePowerState 0 "OFF" 1 "CONDITIONING" 2 "ACCESSORY" 3 "DRIVE" ;
VAL_ 545 VCFRONT_LVPowerStateIndex 0 "Mux0" 1 "Mux1" ;
VAL_ 548 PCS_dcdcInitialPrechargeSubState 0 "PWR_UP_INIT" 1 "STANDBY" 2 "LV_SUPPORT_ACTIVE" 3 "FAST_DIS_HVBUS" 4 "SLOW_DIS_HVBUS" 5 "PCHG_FAST_DIS_HVBUS" 6 "PCHG_SLOW_DIS_HVBUS" 7 "PCHG_DWELL_CHARGE" 8 "PCHG_DWELL_WAIT" 9 "PCHG_DI_RECOVERY_WAIT" 10 "PCHG_ACTIVE" 11 "PCHG_FLT_FAST_DIS_HVBUS" 12 "SHUTDOWN" 13 "LV_SUPPORT_FAULTED" 14 "DIS_HVBUS_FAULTED" 15 "PCHG_FAULTED" 16 "CLEAR_FAULTS" 17 "FAULTED" 18 "NUM" ;
VAL_ 548 PCS_ecuLogUploadRequest 0 "NONE" 1 "1" 2 "2" 3 "3" ;
VAL_ 548 PCS_dcdcSubState 0 "PWR_UP_INIT" 1 "STANDBY" 2 "LV_SUPPORT_ACTIVE" 3 "FAST_DIS_HVBUS" 4 "SLOW_DIS_HVBUS" 5 "PCHG_FAST_DIS_HVBUS" 6 "PCHG_SLOW_DIS_HVBUS" 7 "PCHG_DWELL_CHARGE" 8 "PCHG_DWELL_WAIT" 9 "PCHG_DI_RECOVERY_WAIT" 10 "PCHG_ACTIVE" 11 "PCHG_FLT_FAST_DIS_HVBUS" 12 "SHUTDOWN" 13 "LV_SUPPORT_FAULTED" 14 "DIS_HVBUS_FAULTED" 15 "PCHG_FAULTED" 16 "CLEAR_FAULTS" 17 "FAULTED" 18 "NUM" ;
VAL_ 548 PCS_dcdcHvBusDischargeStatus 0 "IDLE" 1 "ACTIVE" 2 "FAULTED" ;
VAL_ 548 PCS_dcdcLvSupportStatus 0 "IDLE" 1 "ACTIVE" 2 "FAULTED" ;
VAL_ 548 PCS_dcdcPrechargeStatus 0 "IDLE" 1 "ACTIVE" 2 "FAULTED" ;
VAL_ 549 VCRIGHT_icrLVState 0 "OFF" 1 "ON" 2 "GOING_DOWN" 3 "FAULT" ;
VAL_ 549 VCRIGHT_parkLVState 0 "OFF" 1 "ON" 2 "GOING_DOWN" 3 "FAULT" ;
VAL_ 549 VCRIGHT_vehiclePowerStateDBG 0 "INIT" 1 "LOW_POWER_AWAKE" 2 "CONDITIONING" 3 "ACCESSORY" 4 "ACCESSORY_PLUS" 5 "DRIVE" 6 "OTA" 7 "WAIT_FOR_HIGH_POWER" 8 "TURN_ON_LV" 9 "SYSTEM_CHECKS" 10 "LV_ON" 11 "JUMP_START" 12 "LV_SHUTDOWN" 13 "GO_QUIET" 14 "SLEEP_SHUTDOWN" 15 "LOW_POWER_STANDBY" 16 "RESET" ;
VAL_ 549 VCRIGHT_eFuseLockoutStatus 0 "IDLE" 1 "PENDING" 2 "ACTIVE" ;
VAL_ 549 VCRIGHT_lumbarLVState 0 "OFF" 1 "ON" 2 "GOING_DOWN" 3 "FAULT" ;
VAL_ 549 VCRIGHT_rcmLVState 0 "OFF" 1 "ON" 2 "GOING_DOWN" 3 "FAULT" ;
VAL_ 549 VCRIGHT_hvcLVState 0 "OFF" 1 "ON" 2 "GOING_DOWN" 3 "FAULT" ;
VAL_ 549 VCRIGHT_tunerLVState 0 "OFF" 1 "ON" 2 "GOING_DOWN" 3 "FAULT" ;
VAL_ 549 VCRIGHT_premAudioLVState 0 "OFF" 1 "ON" 2 "GOING_DOWN" 3 "FAULT" ;
VAL_ 549 VCRIGHT_ocsLVState 0 "OFF" 1 "ON" 2 "GOING_DOWN" 3 "FAULT" ;
VAL_ 549 VCRIGHT_ptcLVState 0 "OFF" 1 "ON" 2 "GOING_DOWN" 3 "FAULT" ;
VAL_ 552 EPBR_learnedEpbConfig 0 "UNKNOWN" 1 "MODEL3_BASE" 2 "MODEL3_PERFORMANCE" 3 "MODELS_BASE" 4 "MODELY_BASE" 5 "MODELY_PERFORMANCE" 6 "MODELX_BASE" 7 "MODEL3_PERFORMANCE_V2" 8 "MODELY_PERFORMANCE_V2" 9 "MODELS_CERAMIC" ;
VAL_ 552 EPBR_esmSpeedClass 0 "STOPPED" 1 "SYSTEM_APPLY_OK" 2 "USER_APPLY_OK" 3 "FAST" 4 "UNKNOWN" ;
VAL_ 552 EPBR_internalCDPRequest 0 "NOT_REQUESTED" 1 "REQUESTED" ;
VAL_ 552 EPBR_telltaleLocal 0 "LAMP_OFF" 1 "LAMP_RED_ON" 2 "LAMP_AMBER_ON" 3 "LAMP_RED_FLASH" 7 "SNA" ;
VAL_ 552 EPBR_summonFaultReason 0 "NONE" 1 "DI_MIA" 2 "DAS_MIA" 3 "ESP_MIA" 4 "EPBM_MIA" 5 "DI_FAULT" 6 "DI_APC_FAULT" 7 "DAS_FAULT" 8 "ESP_FAULT" 9 "VEH_CAN_FAULT" 10 "EAC_NOT_ALLOWED" 11 "EPBM_REQUEST" 12 "SPEED" 13 "EXTERNAL" 14 "PARK_MIA" 15 "PM_MIA" 16 "PM_REQUEST" 17 "OOC" 18 "MISMATCH" 19 "EPB_FAULT" 20 "DI_STATE_INVALID" 21 "PASSIVE_REQUEST" 22 "EPBREMOTE_MIA" 23 "REMOTE_SUMMON_FAULTED" 24 "LOCAL_UNIT_FAULTED" 25 "REMOTE_UNIT_FAULTED" 26 "START_IN_UNAVAILABLE" 27 "INVALID_REMOTE_STATE" 28 "REMOTE_DID_NOT_START" ;
VAL_ 552 EPBR_esmOperationTrigger 0 "PBUTTON_PRESSED_STOPPED" 1 "PBUTTON_PRESSED_OKTOPARK" 2 "PBUTTON_PRESSED_FAST" 3 "PBUTTON_PRESSED_UNKNOWN" 4 "PBUTTON_RELEASED" 5 "ACTIVE_PARK_REQUEST" 6 "DI_UNPARK" 7 "TOUCHSCREEN" 8 "WINCHMODE_EXIT" 9 "WINCHMODE_ENTER" 10 "WINCHMODE_UNAVAILABLE" 11 "SERVICE" 12 "DIAG_CLOSE" 13 "DIAG_OPEN" 14 "DIAG_EXIT" 15 "USER_CONFIRMED" 16 "USER_CANCEL" 17 "SPEED_STOPPED" 18 "SPEED_OKAYTOPARK" 19 "SPEED_FAST" 20 "TIMEOUT" 21 "SAVESTATE_ON_BOOT" 22 "REAPPLY" 23 "SUMMON_COMPLETE" 24 "FAULT" 25 "SUMMON_FAULT" 26 "DISQUALIFIED" 27 "EPBM_DISQUALIFIED" 28 "ACCELERATION" 29 "SYSTEM_APPLY" 30 "DRIVER_IS_LEAVING" 31 "AUTOPARK_END" 32 "UI_DOOR_OPEN_REQUEST" 33 "TOUCHSCREEN_INVALID" ;
VAL_ 552 EPBR_csmFaultReason 0 "NONE" 1 "EPBM_DISABLED" 2 "EPBM_FAULTED" 3 "STATE_MISMATCH" 4 "TIMEOUT_CALIBRATE" 5 "APPLY_BLOCKED" 6 "RELEASE_BLOCKED" 7 "TIMEOUT_APPLY_COMPLETE" 8 "TIMEOUT_APPLY_INRUSH" 9 "TIMEOUT_EPB_WAIT_FOR_CLAMP" 10 "TIMEOUT_EPBM_WAIT_FOR_CLAMP" 11 "TIMEOUT_RELEASE_INRUSH" 12 "TIMEOUT_RELEASE_WAIT_FOR_ENDSTOP" 13 "TIMEOUT_RELEASE_NO_LOAD" 14 "TIMEOUT_RELEASE_COMPLETE" 15 "TIMEOUT_EPBM_CUTOFF" 16 "TIMEOUT_NO_RAMP" 17 "TIMEOUT_EPBM_START" 18 "MOTOR_IDLE_FAULT" 19 "MOTOR_ACTIVE_FAULT" 20 "MOTOR_NOT_READY" 21 "EPBM_MIA" 22 "NVM_MISMATCH" 23 "REMOTE_MIA" ;
VAL_ 552 EPBR_summonState 0 "INIT" 1 "IDLE" 2 "ARMED" 3 "ACTIVE" 4 "COMPLETE" 5 "FAULT" 6 "UNAVAILABLE" ;
VAL_ 552 EPBR_unitFaultStatus 0 "NOMINAL" 1 "RETRY" 2 "FAULT" 3 "FAULT_IDLE" ;
VAL_ 552 EPBR_unitStatus 0 "UNKNOWN" 1 "OPEN" 2 "DYNAMIC" 3 "PARK" 4 "START" 5 "SERVICE" 6 "WINCHMODE" 7 "WINCHMODE_RELEASING" 8 "PARKING" 9 "DYNAMIC_APPLYING" 10 "RELEASING" 11 "SERVICE_RELEASING" 12 "PARK_PENDING" 13 "WINCHMODE_PENDING" 14 "SUMMON" 15 "SUMMON_RELEASING" 16 "SUMMON_PARKING" 17 "EXTERNAL_DYNAMIC" 18 "RELEASING_FOR_EXTERNAL_PARK" 19 "EXTERNAL_PARKING" 20 "DYNAMIC_PARKING" 21 "FREE_ROLL_MODE" 22 "COUNT" ;
VAL_ 553 SCCM_parkButtonStatus 0 "NOT_PRESSED" 1 "PRESSED" 2 "INIT" 3 "SNA" ;
VAL_ 553 SCCM_rightStalkStatus 0 "IDLE" 1 "UP_1" 2 "UP_2" 3 "DOWN_1" 4 "DOWN_2" 5 "INIT" 6 "SNA" ;
VAL_ 554 HVP_dcLinkVoltageFiltered 4294966746 "SNA" ;
VAL_ 554 HVP_pcsControlRequest 0 "SHUTDOWN" 1 "SUPPORT" 2 "PRECHARGE" 3 "DISCHARGE" ;
VAL_ 564 DCDC_type 0 "US_TESLA" 1 "EURO_IEC" 2 "GB" 3 "IEC_CCS" ;
VAL_ 568 UI_nextBranchDist 31 "SNA" ;
VAL_ 568 UI_countryCode 0 "UNKNOWN" 1023 "SNA" ;
VAL_ 568 UI_mapSpeedLimitType 1 "REGULAR" 2 "ADVISORY" 3 "DEPENDENT" 4 "BUMPS" 7 "UNKNOWN_SNA" ;
VAL_ 568 UI_mapSpeedLimit 0 "UNKNOWN" 1 "LESS_OR_EQ_5" 2 "LESS_OR_EQ_7" 3 "LESS_OR_EQ_10" 4 "LESS_OR_EQ_15" 5 "LESS_OR_EQ_20" 6 "LESS_OR_EQ_25" 7 "LESS_OR_EQ_30" 8 "LESS_OR_EQ_35" 9 "LESS_OR_EQ_40" 10 "LESS_OR_EQ_45" 11 "LESS_OR_EQ_50" 12 "LESS_OR_EQ_55" 13 "LESS_OR_EQ_60" 14 "LESS_OR_EQ_65" 15 "LESS_OR_EQ_70" 16 "LESS_OR_EQ_75" 17 "LESS_OR_EQ_80" 18 "LESS_OR_EQ_85" 19 "LESS_OR_EQ_90" 20 "LESS_OR_EQ_95" 21 "LESS_OR_EQ_100" 22 "LESS_OR_EQ_105" 23 "LESS_OR_EQ_110" 24 "LESS_OR_EQ_115" 25 "LESS_OR_EQ_120" 26 "LESS_OR_EQ_130" 27 "LESS_OR_EQ_140" 28 "LESS_OR_EQ_150" 29 "LESS_OR_EQ_160" 30 "UNLIMITED" 31 "SNA" ;
VAL_ 568 UI_mapSpeedUnits 0 "MPH" 1 "KPH" ;
VAL_ 568 UI_inSuperchargerGeofence 0 "FALSE" 1 "TRUE" ;
VAL_ 568 UI_roadClass 0 "UNKNOWN_INVALID_SNA" 1 "CLASS_1_MAJOR" 2 "CLASS_2" 3 "CLASS_3" 4 "CLASS_4" 5 "CLASS_5" 6 "CLASS_6_MINOR" ;
VAL_ 568 UI_mapSpeedLimitDependency 0 "NONE" 1 "SCHOOL" 2 "RAIN" 3 "SNOW" 4 "TIME" 5 "SEASON" 6 "LANE" 7 "SNA" ;
VAL_ 577 VCFRONT_coolantAirPurgeBatState 0 "INACTIVE" 1 "ACTIVE" 2 "COMPLETE" 3 "INTERRUPTED" 4 "PENDING" ;
VAL_ 577 VCFRONT_wasteHeatRequestType 0 "NONE" 1 "PARTIAL" 2 "FULL" 3 "BURN_IN" ;
VAL_ 577 VCFRONT_coolantFlowPTReason 0 "NONE" 1 "COOLANT_AIR_PURGE" 2 "NO_FLOW_REQ" 3 "OVERRIDE_BATT" 4 "ACTIVE_MANAGER_BATT" 5 "PASSIVE_MANAGER_BATT" 6 "BMS_FLOW_REQ" 7 "DAS_FLOW_REQ" 8 "OVERRIDE_PT" 9 "ACTIVE_MANAGER_PT" 10 "PASSIVE_MANAGER_PT" 11 "PCS_FLOW_REQ" 12 "DIR_FLOW_REQ" 13 "DIF_FLOW_REQ" 14 "DIRER_FLOW_REQ" 15 "DIREL_FLOW_REQ" 16 "MCU_FLOW_REQ" 17 "HP_FLOW_REQ" 18 "UI_FLOW_REQ" 19 "BMS_PPR_FLOW_REQ" 20 "DI_PPR_FLOW_REQ" ;
VAL_ 577 VCFRONT_coolantFlowBatReason 0 "NONE" 1 "COOLANT_AIR_PURGE" 2 "NO_FLOW_REQ" 3 "OVERRIDE_BATT" 4 "ACTIVE_MANAGER_BATT" 5 "PASSIVE_MANAGER_BATT" 6 "BMS_FLOW_REQ" 7 "DAS_FLOW_REQ" 8 "OVERRIDE_PT" 9 "ACTIVE_MANAGER_PT" 10 "PASSIVE_MANAGER_PT" 11 "PCS_FLOW_REQ" 12 "DIR_FLOW_REQ" 13 "DIF_FLOW_REQ" 14 "DIRER_FLOW_REQ" 15 "DIREL_FLOW_REQ" 16 "MCU_FLOW_REQ" 17 "HP_FLOW_REQ" 18 "UI_FLOW_REQ" 19 "BMS_PPR_FLOW_REQ" 20 "DI_PPR_FLOW_REQ" ;
VAL_ 578 VCLEFT_vehiclePowerStateDBG 0 "INIT" 1 "LOW_POWER_AWAKE" 2 "CONDITIONING" 3 "ACCESSORY" 4 "ACCESSORY_PLUS" 5 "DRIVE" 6 "OTA" 7 "WAIT_FOR_HIGH_POWER" 8 "TURN_ON_LV" 9 "SYSTEM_CHECKS" 10 "LV_ON" 11 "JUMP_START" 12 "LV_SHUTDOWN" 13 "GO_QUIET" 14 "SLEEP_SHUTDOWN" 15 "LOW_POWER_STANDBY" 16 "RESET" ;
VAL_ 578 VCLEFT_lumbarLVState 0 "OFF" 1 "ON" 2 "GOING_DOWN" 3 "FAULT" ;
VAL_ 578 VCLEFT_rcmLVState 0 "OFF" 1 "ON" 2 "GOING_DOWN" 3 "FAULT" ;
VAL_ 579 VCRIGHT_hvacModelInitStatus 0 "NOT_INIT_WAIT_FOR_SENSORS" 1 "NOT_INIT_WAIT_FOR_GTW" 2 "INIT_FROM_SENSORS" 3 "INIT_FROM_SENSORS_PREDICTION_ERROR" 4 "INIT_FORWARD_CALC" 5 "INIT_WAITING_FOR_SENSORS" ;
VAL_ 579 VCRIGHT_hvacDuctTargetRight 255 "SNA" ;
VAL_ 579 VCRIGHT_hvacSecondRowState 0 "AUTO" 1 "OFF" 2 "LOW" 3 "MED" 4 "HIGH" ;
VAL_ 579 VCRIGHT_tempDuctRightLower 255 "SNA" ;
VAL_ 579 VCRIGHT_hvacVentStatus 0 "BOTH" 1 "LEFT" 2 "RIGHT" ;
VAL_ 579 VCRIGHT_hvacPowerState 0 "OFF" 1 "ON" 2 "PRECONDITION" 3 "OVERHEAT_PROTECT_FANONLY" 4 "OVERHEAT_PROTECT" ;
VAL_ 579 VCRIGHT_hvacACRunning 0 "OFF" 1 "ON" ;
VAL_ 579 VCRIGHT_hvacDuctTargetLeft 255 "SNA" ;
VAL_ 579 VCRIGHT_hvacRecirc 0 "AUTO" 1 "RECIRC" 2 "FRESH" ;
VAL_ 579 VCRIGHT_tempDuctLeftLower 255 "SNA" ;
VAL_ 579 VCRIGHT_hvacBlowerSegment 0 "OFF" 1 "1" 2 "2" 3 "3" 4 "4" 5 "5" 6 "6" 7 "7" 8 "8" 9 "9" 10 "10" 11 "11" ;
VAL_ 579 VCRIGHT_hvacAirDistributionMode 0 "NONE" 1 "FLOOR" 2 "PANEL" 3 "PANEL_FLOOR" 4 "DEFROST" 5 "DEFROST_FLOOR" 6 "DEFROST_PANEL" 7 "DEFROST_PANEL_FLOOR" ;
VAL_ 579 VCRIGHT_solarLoadOnVehicle 255 "SNA" ;
VAL_ 579 VCRIGHT_hvacAirflowReason 0 "HVAC_OFF" 1 "MANUAL_FAN_SPEED" 2 "UI_SHORTCUT" 3 "CABIN_TEMPERATURE_CONTROL" 4 "MINIMUM_AUTO_AIRFLOW" 5 "STRATIFICATION_GLASS_ROOF" 6 "STRATIFICATION_INTERIOR_SURFACES" 7 "OCCUPANT_CONVECTION_REQUIREMENT" 8 "COLD_DUCT_LOCKOUT" 9 "CABIN_PURGE" 10 "CABIN_OVERHEAT_PROTECT" 11 "SCREEN_PROTECTION" 12 "EVAP_DRYING" 13 "EVAP_OIL_PURGE" 14 "BIOWEAPON_DEFENSE" 15 "NONE" ;
VAL_ 579 VCRIGHT_tempDuctRight 255 "SNA" ;
VAL_ 579 VCRIGHT_autoDefogStatus 0 "NONE" 1 "DEFOG" 2 "INTERMEDIATE_DEFOG" ;
VAL_ 579 VCRIGHT_hvacEvapInletTempEstimate 1023 "SNA" ;
VAL_ 579 VCRIGHT_hvacFrontLeftSeatHeatStatus 0 "OFF" 1 "LEVEL1" 2 "LEVEL2" 3 "LEVEL3" ;
VAL_ 579 VCRIGHT_tempDuctLeft 255 "SNA" ;
VAL_ 579 VCRIGHT_tempDuctLeftUpper 255 "SNA" ;
VAL_ 579 VCRIGHT_tempDuctRightUpper 255 "SNA" ;
VAL_ 579 VCRIGHT_hvacSeatFrontLeftTempTarget 0 "OFF" ;
VAL_ 579 VCRIGHT_hvacFrontRightSeatHeatStatus 0 "OFF" 1 "LEVEL1" 2 "LEVEL2" 3 "LEVEL3" ;
VAL_ 579 VCRIGHT_hvacStatusIndex 0 "STATUS_UI" 1 "STATUS_VCFRONT" 2 "TARGETS_AND_MASS_FLOW" 3 "TEMPERATURES" 4 "TEMPERATURES_2" 5 "SEAT_CLIMATE" 6 "END" ;
VAL_ 580 FC_minVoltageLimit 8191 "SNA" ;
VAL_ 580 FC_maxVoltageLimit 8191 "SNA" ;
VAL_ 580 FC_currentLimit 8191 "SNA" ;
VAL_ 580 FC_powerLimit 8191 "SNA" ;
VAL_ 585 SCCM_turnIndicatorStalkStatus 0 "IDLE" 1 "UP_0_5" 2 "UP_1" 3 "UP_1_5" 4 "UP_2" 5 "DOWN_0_5" 6 "DOWN_1" 7 "DOWN_1_5" 8 "DOWN_2" 9 "SNA" ;
VAL_ 585 SCCM_washWipeButtonStatus 0 "NOT_PRESSED" 1 "1ST_DETENT" 2 "2ND_DETENT" 3 "SNA" ;
VAL_ 585 SCCM_highBeamStalkStatus 0 "IDLE" 1 "PULL" 2 "PUSH" 3 "SNA" ;
VAL_ 594 BMS_powerLimitsState 0 "NOT_CALCULATED_FOR_DRIVE" 1 "CALCULATED_FOR_DRIVE" ;
VAL_ 595 UI_hvacReqActiveVents 0 "BOTH" 1 "LEFT" 2 "RIGHT" ;
VAL_ 595 UI_ventPanelRightLateralMode 0 "SINGLE" 1 "SPLIT" ;
VAL_ 595 UI_ventPanelLeftLateralMode 0 "SINGLE" 1 "SPLIT" ;
VAL_ 595 UI_ventPanelControlRequestIndex 0 "0" 1 "1" ;
VAL_ 599 DI_uiSpeedUnits 0 "MPH" 1 "KPH" ;
VAL_ 599 DI_uiSpeed 255 "SNA" ;
VAL_ 599 DI_vehicleSpeed 4095 "SNA" ;
VAL_ 602 VCSEC_TPMSDisplayHardWarningIndicationRR 0 "NOT_INDICATED" 1 "INDICATED" ;
VAL_ 602 VCSEC_TPMSDisplayHardWarningIndicationRL 0 "NOT_INDICATED" 1 "INDICATED" ;
VAL_ 602 VCSEC_TPMSDisplayHardWarningIndicationFR 0 "NOT_INDICATED" 1 "INDICATED" ;
VAL_ 602 VCSEC_TPMSDisplayHardWarningIndicationFL 0 "NOT_INDICATED" 1 "INDICATED" ;
VAL_ 602 VCSEC_TPMSDisplaySoftWarningIndicationRR 0 "NOT_INDICATED" 1 "INDICATED" ;
VAL_ 602 VCSEC_TPMSDisplaySoftWarningIndicationRL 0 "NOT_INDICATED" 1 "INDICATED" ;
VAL_ 602 VCSEC_TPMSDisplaySoftWarningIndicationFR 0 "NOT_INDICATED" 1 "INDICATED" ;
VAL_ 602 VCSEC_TPMSDisplaySoftWarningIndicationFL 0 "NOT_INDICATED" 1 "INDICATED" ;
VAL_ 602 VCSEC_TPMSTellTale 0 "OFF" 1 "SOLID" 2 "FLASHING" ;
VAL_ 602 VCSEC_TPMSDisplayPressureRR 255 "SNA" ;
VAL_ 602 VCSEC_TPMSDisplayPressureRL 255 "SNA" ;
VAL_ 602 VCSEC_TPMSDisplayPressureFR 255 "SNA" ;
VAL_ 602 VCSEC_TPMSDisplayPressureFL 255 "SNA" ;
VAL_ 603 APP_sentryState 0 "OFF" 1 "IDLE" 2 "ARMED" 3 "AWARE" 4 "PANIC" 5 "QUIET" 6 "SNA" ;
VAL_ 603 APP_fsdRevokeStrikeoutCount 7 "SNA" ;
VAL_ 603 APP_fsdSuspendState 0 "NOT_SUSPENDED" 1 "SUSPENDED" 3 "SNA" ;
VAL_ 603 APP_summonUnavailableReason 0 "UNKNOWN" 1 "NONE" 2 "NOT_IN_PARK" 3 "CAMERA_STREAM" 4 "CAMERA_BLOCKED" 5 "ULTRASONIC_BLOCKED" 6 "ULTRASONIC_FAULT" 7 "CRUISE_UNAVAILABLE" 8 "EAC_UNAVAILABLE" 9 "PUBLIC_ROAD" 10 "POOR_CONNECTION" 11 "PHONE_GPS_UNAVAILABLE" 12 "EGO_GPS_UNAVAILABLE" 13 "PHONE_IS_TOO_FAR" 14 "END_OF_LEASH" 15 "CAMERA_NOT_CALIBRATED" 16 "VISION_HEALTH_CRITICAL" 17 "ULTRASONIC_STALE" 18 "ALL_SENSORS_OCCLUDED" 19 "PUBLIC_ROAD_BOUNDARIES_NOT_VALID" 20 "NO_CONTEXT" ;
VAL_ 603 APP_clipRecordingStatus 0 "NO_DRIVE" 1 "IDLE" 2 "RECORDING" 3 "TRIGGERED" 4 "FAULTED" ;
VAL_ 603 APP_factorySummonStatus 0 "SNA" 1 "ACTIVE" 2 "AVAILABLE" 3 "UNAVAILABLE_NO_QR_INSTRUCTION" 4 "UNAVAILABLE_GOAL_TOO_FAR" 5 "UNAVAILABLE_NO_GPS" 6 "UNAVAILABLE_VEHICLE_SPEED_INVALID" 7 "UNAVAILABLE_HEADING_NOT_INITIALIZED" 8 "END_OF_ROUTE" ;
VAL_ 603 APP_fusedState 0 "UNKNOWN" 1 "UNFUSED" 2 "FUSED" 3 "SNA" ;
VAL_ 603 APP_watchdogState 0 "UNKNOWN" 1 "DEGRADED" 2 "CRITICAL" 3 "HEALTHY" 7 "SNA" ;
VAL_ 605 CP_coldWeatherMode 0 "NONE" 1 "LATCH_MITIGATION" ;
VAL_ 605 CP_inductiveSensorState 0 "INIT" 1 "POLL" 2 "SHUTDOWN" 3 "PAUSE" 4 "WAIT_FOR_INIT" 5 "FAULT" 6 "RESET" 7 "CONFIG" ;
VAL_ 605 CP_doorPresenceState 0 "INIT" 1 "INIT_FROM_CHARGE" 2 "INIT_FROM_DRIVE" 3 "PRESENT" 4 "NOT_PRESENT" 5 "OFF_DRIVE" 6 "OFF_CHARGE" 7 "FAULT" ;
VAL_ 605 CP_faultLineSensed 0 "CLEARED" 1 "SET" ;
VAL_ 605 CP_ledColor 0 "OFF" 1 "RED" 2 "GREEN" 3 "BLUE" 4 "WHITE" 5 "FLASHING_GREEN" 6 "FLASHING_AMBER" 7 "AMBER" 8 "RAVE" 9 "DEBUG" 10 "FLASHING_BLUE" ;
VAL_ 605 CP_latchControlState 0 "latchInit" 1 "latchIdle" 2 "latchDisengageRequested" 3 "latchDisengaging" 4 "latchDisengaged" 5 "latchEngaging" ;
VAL_ 605 CP_chargeCableState 0 "UNKNOWN_SNA" 1 "NOT_CONNECTED" 2 "CONNECTED" ;
VAL_ 605 CP_doorControlState 0 "doorInit" 1 "doorIdle" 2 "doorOpenRequested" 3 "doorOpening" 4 "doorSenseOpen" 5 "doorClosing" 6 "doorSenseClosed" ;
VAL_ 605 CP_latchState 0 "SNA" 1 "DISENGAGED" 2 "ENGAGED" 3 "BLOCKING" ;
VAL_ 605 CP_type 0 "US_TESLA" 1 "EURO_IEC" 2 "GB" 3 "IEC_CCS" ;
VAL_ 609 VCFRONT_LVBatteryType 0 "CATL_LI_ION" 1 "UNKNOWN" ;
VAL_ 609 VCFRONT_LVBatteryStatusForDrive 0 "NOT_READY_FOR_DRIVE" 1 "READY_FOR_DRIVE" 2 "EXIT_DRIVE_REQUESTED" ;
VAL_ 609 VCFRONT_IBSVoltage 4095 "SNA" ;
VAL_ 609 VCFRONT_silentWakeIBSCurrent 4095 "SNA" ;
VAL_ 609 VCFRONT_LVBatterySupportRqrdTrigger 0 "NONE" 1 "IBS_FILTERED_VOLTAGE" 2 "PACK_FILTERED_VOLTAGE" 4 "IBS_RAW_VOLTAGE" 8 "PACK_RAW_VOLTAGE" 16 "VBAT_RAW_VOLTAGE" 32 "UNKNOWN_VOLTAGE" 64 "AH_COUNT" 128 "PERIODIC_CHARGE" 256 "POWER_ON_RESET" 512 "EXIT_TRANSPORT_MODE" 1024 "POST_OTA" ;
VAL_ 609 VCFRONT_IBSVoltageRawDBG 4095 "IBS_VOLTAGE_SNA" ;
VAL_ 609 VCFRONT_LVBMS_LVBusVoltageSourceDBG 0 "NONE" 1 "IBS" 2 "VBAT_MONITOR" 3 "LVBMS" ;
VAL_ 609 VCFRONT_IBSTemperature 32767 "IBS_TEMPERATURE_SNA" ;
VAL_ 609 VCFRONT_batterySMState 0 "INIT" 1 "CHARGE" 2 "DISCHARGE" 3 "STANDBY" 4 "RESISTANCE_ESTIMATION" 5 "OTA_STANDBY" 6 "DISCONNECTED_BATTERY_TEST" 7 "SHORTED_CELL_TEST" 8 "FAULT" 9 "RECOVERY" ;
VAL_ 609 VCFRONT_IBSVoltageFiltered 4095 "IBS_VOLTAGE_SNA" ;
VAL_ 609 VCFRONT_voltageProfile 0 "CHARGE" 1 "FLOAT" 2 "REDUCED_FLOAT" 3 "ALWAYS_CLOSED_CONTACTORS" ;
VAL_ 609 VCFRONT_12VBatteryStatusIndex 0 "Mux0" 1 "Mux1" 2 "Mux2" ;
VAL_ 610 VCLEFT_steeringColumnLastRequest 0 "SNA" 1 "NONE" 2 "UP" 3 "DOWN" 4 "IN" 5 "OUT" ;
VAL_ 610 VCLEFT_steeringColumnSMState 0 "SNA" 1 "RECALL" 2 "CALIBRATE" 3 "MANUAL_CONTROL" ;
VAL_ 611 VCRIGHT_hvacIntakeActuatorState 0 "BRAKING" 1 "RUNNING" 2 "COASTING" ;
VAL_ 611 VCRIGHT_hvacLowerModeActState 0 "BRAKING" 1 "RUNNING" 2 "COASTING" ;
VAL_ 611 VCRIGHT_hvacUpperModeActState 0 "BRAKING" 1 "RUNNING" 2 "COASTING" ;
VAL_ 611 VCRIGHT_hvacRHVaneActuatorState 0 "BRAKING" 1 "RUNNING" 2 "COASTING" ;
VAL_ 611 VCRIGHT_hvacLHVaneActuatorState 0 "BRAKING" 1 "RUNNING" 2 "COASTING" ;
VAL_ 611 VCRIGHT_hvacRHBleedActuatorState 0 "BRAKING" 1 "RUNNING" 2 "COASTING" ;
VAL_ 611 VCRIGHT_hvacLHBleedActuatorState 0 "BRAKING" 1 "RUNNING" 2 "COASTING" ;
VAL_ 611 VCRIGHT_logging10HzIndex 0 "HVAC_ACTUATOR_TARGETS_1" 1 "HVAC_ACTUATOR_TARGETS_2" 2 "HVAC_ACTUATOR_POSITIONS_1" 3 "HVAC_ACTUATOR_POSITIONS_2" 4 "END" ;
VAL_ 614 DIR_drivePowerMax 511 "SNA" ;
VAL_ 614 DIR_elecPower 4294966272 "SNA" ;
VAL_ 616 DI_sysRegenPowerMax 255 "SNA" ;
VAL_ 616 DI_primaryUnitSiliconType 0 "MOSFET" 1 "IGBT" ;
VAL_ 616 DI_sysDrivePowerMax 511 "SNA" ;
VAL_ 626 VCLEFT_epbmSystemStatus 0 "UNKNOWN" 1 "RELEASED" 2 "PARKED" 3 "DYNAMIC" 4 "PARKING" 5 "RELEASING" 6 "FAULT" 7 "FAULT_SECURE" 8 "MISMATCH" ;
VAL_ 626 VCLEFT_epbFaultStatus 0 "NOMINAL" 1 "RETRY" 2 "FAULT" 3 "FAULT_IDLE" ;
VAL_ 626 VCLEFT_epbmFaultStatus 0 "NOMINAL" 1 "RETRY" 2 "FAULT" 3 "FAULT_IDLE" ;
VAL_ 626 VCLEFT_epbUnitStatus 0 "UNKNOWN" 1 "OPEN" 2 "DYNAMIC" 3 "PARK" 4 "START" 5 "SERVICE" 6 "WINCHMODE" 7 "WINCHMODE_RELEASING" 8 "PARKING" 9 "DYNAMIC_APPLYING" 10 "RELEASING" 11 "SERVICE_RELEASING" 12 "PARK_PENDING" 13 "WINCHMODE_PENDING" 14 "SUMMON" 15 "SUMMON_RELEASING" 16 "SUMMON_PARKING" 17 "EXTERNAL_DYNAMIC" 18 "RELEASING_FOR_EXTERNAL_PARK" 19 "EXTERNAL_PARKING" 20 "DYNAMIC_PARKING" 21 "FREE_ROLL_MODE" 22 "COUNT" ;
VAL_ 626 VCLEFT_epbmSummonState 0 "INIT" 1 "IDLE" 2 "ARMED" 3 "ACTIVE" 4 "COMPLETE" 5 "FAULT" 6 "UNAVAILABLE" ;
VAL_ 626 VCLEFT_epbSummonState 0 "INIT" 1 "IDLE" 2 "ARMED" 3 "ACTIVE" 4 "COMPLETE" 5 "FAULT" 6 "UNAVAILABLE" ;
VAL_ 626 VCLEFT_summonFaultReason 0 "NONE" 1 "DI_MIA" 2 "DAS_MIA" 3 "ESP_MIA" 4 "EPBM_MIA" 5 "DI_FAULT" 6 "DI_APC_FAULT" 7 "DAS_FAULT" 8 "ESP_FAULT" 9 "VEH_CAN_FAULT" 10 "EAC_NOT_ALLOWED" 11 "EPBM_REQUEST" 12 "SPEED" 13 "EXTERNAL" 14 "PARK_MIA" 15 "PM_MIA" 16 "PM_REQUEST" 17 "OOC" 18 "MISMATCH" 19 "EPB_FAULT" 20 "DI_STATE_INVALID" 21 "PASSIVE_REQUEST" 22 "EPBREMOTE_MIA" 23 "REMOTE_SUMMON_FAULTED" 24 "LOCAL_UNIT_FAULTED" 25 "REMOTE_UNIT_FAULTED" 26 "START_IN_UNAVAILABLE" 27 "INVALID_REMOTE_STATE" 28 "REMOTE_DID_NOT_START" ;
VAL_ 626 VCLEFT_epbmCaliperState 0 "UNSAVED" 1 "UNKNOWN" 2 "REAPPLY" 3 "PARK" 4 "OPEN" 5 "SERVICE" 6 "WINCHMODE" ;
VAL_ 626 VCLEFT_epbmDebugIndex 0 "STATES" 1 "TRANSITIONS" ;
VAL_ 627 UI_driveStateRequest 0 "IDLE" 1 "START" ;
VAL_ 627 UI_domeLightSwitch 0 "OFF" 1 "ON" 2 "AUTO" ;
VAL_ 627 UI_wiperRequest 0 "SNA" 1 "OFF" 2 "AUTO" 3 "SLOW_INTERMITTENT" 4 "FAST_INTERMITTENT" 5 "SLOW_CONTINUOUS" 6 "FAST_CONTINUOUS" ;
VAL_ 627 UI_remoteClosureRequest 0 "IDLE" 1 "REAR_TRUNK_MOVE" 2 "FRONT_TRUNK_MOVE" 3 "SNA" ;
VAL_ 627 UI_rearRightSeatHeatReq 0 "OFF" 1 "LEVEL1" 2 "LEVEL2" 3 "LEVEL3" ;
VAL_ 627 UI_rearCenterSeatHeatReq 0 "OFF" 1 "LEVEL1" 2 "LEVEL2" 3 "LEVEL3" ;
VAL_ 627 UI_rearLeftSeatHeatReq 0 "OFF" 1 "LEVEL1" 2 "LEVEL2" 3 "LEVEL3" ;
VAL_ 627 UI_frontRightSeatHeatReq 0 "OFF" 1 "LEVEL1" 2 "LEVEL2" 3 "LEVEL3" ;
VAL_ 627 UI_frontLeftSeatHeatReq 0 "OFF" 1 "LEVEL1" 2 "LEVEL2" 3 "LEVEL3" ;
VAL_ 627 UI_displayBrightnessLevel 255 "SNA" ;
VAL_ 627 UI_remoteStartRequest 0 "IDLE" 1 "START" 4 "SNA" ;
VAL_ 627 UI_mirrorFoldRequest 0 "IDLE" 1 "RETRACT" 2 "PRESENT" 3 "SNA" ;
VAL_ 627 UI_lockRequest 0 "IDLE" 1 "LOCK" 2 "UNLOCK" 3 "REMOTE_UNLOCK" 4 "REMOTE_LOCK" 7 "SNA" ;
VAL_ 627 UI_steeringButtonMode 0 "OFF" 1 "STEERING_COLUMN_ADJ" 2 "MIRROR_LEFT" 3 "MIRROR_RIGHT" 4 "HEADLIGHT_LEFT" 5 "HEADLIGHT_RIGHT" 6 "WIPERS" ;
VAL_ 627 UI_steeringBacklightEnabled 0 "DISABLED" 1 "ENABLED" ;
VAL_ 627 UI_wiperMode 0 "SNA" 1 "SERVICE" 2 "NORMAL" 3 "PARK" ;
VAL_ 627 UI_frunkRequest 0 "NONE" 1 "MOVE" 2 "STOP" 3 "SNA" ;
VAL_ 627 UI_powerStateRequest 0 "IDLE" 1 "ACCESSORY" 2 "ACCESSORY_PLUS" 3 "DRIVE_SUMMON" ;
VAL_ 633 DIR_gateDriveSupplyState 0 "DOWN" 1 "RISING" 2 "UP" 3 "FALLING" ;
VAL_ 633 DIR_gateDriveState 0 "INIT" 1 "SELFTEST" 2 "CONFIGURING" 3 "CONFIGURED" 4 "NOT_CONFIGURED" ;
VAL_ 633 DIR_powerStageSafeState 0 "NONE" 1 "ALL_OFF" 2 "3PS_HIGH" 3 "3PS_LOW" ;
VAL_ 633 DIR_vBatQF 0 "NOT_QUALIFIED" 1 "QUALIFIED" ;
VAL_ 633 DIR_hvilSupplyState 0 "NOT_AVAILABLE" 1 "INACTIVE" 2 "ACTIVE" ;
VAL_ 633 DIR_hvilStatus 0 "DISABLED" 1 "OPEN" 2 "CLOSED" 3 "SNA" ;
VAL_ 642 VCLEFT_hvacBlowerIDc 127 "SNA" ;
VAL_ 642 VCLEFT_hvacBlowerFETTemp 127 "SNA" ;
VAL_ 642 VCLEFT_hvacBlowerTorque 1023 "SNA" ;
VAL_ 642 VCLEFT_hvacBlowerRPMTarget 1023 "SNA" ;
VAL_ 642 VCLEFT_hvacBlowerOutputDuty 127 "SNA" ;
VAL_ 644 UI_closureEasterEggStatus 0 "IDLE" 1 "REQ_RECD_WAITING_STANDARD" 2 "REQ_RECD_WAITING_DYNAMIC" 3 "PLAYING" ;
VAL_ 644 UI_serviceModePlus 0 "DISABLED" 1 "ENABLED" ;
VAL_ 644 UI_diagnosticsAllowed 0 "NOT_ALLOWED" 1 "ALLOWED" ;
VAL_ 644 UI_serviceMode 0 "DISABLED" 1 "ENABLED" ;
VAL_ 644 UI_showroomMode 0 "DISABLED" 1 "ENABLED" ;
VAL_ 644 UI_transportMode 0 "DISABLED" 1 "ENABLED" ;
VAL_ 644 UI_factoryMode 0 "DISABLED" 1 "ENABLED" ;
VAL_ 645 UI_driverProfileRecallIndex 0 "SNA" 1 "1" 2 "2" 3 "3" 4 "4" 5 "5" ;
VAL_ 646 UI_driverProfileSelectionType 0 "MANUAL" 1 "AUTOMATIC" 2 "NONE" ;
VAL_ 648 EPBL_learnedEpbConfig 0 "UNKNOWN" 1 "MODEL3_BASE" 2 "MODEL3_PERFORMANCE" 3 "MODELS_BASE" 4 "MODELY_BASE" 5 "MODELY_PERFORMANCE" 6 "MODELX_BASE" 7 "MODEL3_PERFORMANCE_V2" 8 "MODELY_PERFORMANCE_V2" 9 "MODELS_CERAMIC" ;
VAL_ 648 EPBL_esmSpeedClass 0 "STOPPED" 1 "SYSTEM_APPLY_OK" 2 "USER_APPLY_OK" 3 "FAST" 4 "UNKNOWN" ;
VAL_ 648 EPBL_internalCDPRequest 0 "NOT_REQUESTED" 1 "REQUESTED" ;
VAL_ 648 EPBL_telltaleLocal 0 "LAMP_OFF" 1 "LAMP_RED_ON" 2 "LAMP_AMBER_ON" 3 "LAMP_RED_FLASH" 7 "SNA" ;
VAL_ 648 EPBL_summonFaultReason 0 "NONE" 1 "DI_MIA" 2 "DAS_MIA" 3 "ESP_MIA" 4 "EPBM_MIA" 5 "DI_FAULT" 6 "DI_APC_FAULT" 7 "DAS_FAULT" 8 "ESP_FAULT" 9 "VEH_CAN_FAULT" 10 "EAC_NOT_ALLOWED" 11 "EPBM_REQUEST" 12 "SPEED" 13 "EXTERNAL" 14 "PARK_MIA" 15 "PM_MIA" 16 "PM_REQUEST" 17 "OOC" 18 "MISMATCH" 19 "EPB_FAULT" 20 "DI_STATE_INVALID" 21 "PASSIVE_REQUEST" 22 "EPBREMOTE_MIA" 23 "REMOTE_SUMMON_FAULTED" 24 "LOCAL_UNIT_FAULTED" 25 "REMOTE_UNIT_FAULTED" 26 "START_IN_UNAVAILABLE" 27 "INVALID_REMOTE_STATE" 28 "REMOTE_DID_NOT_START" ;
VAL_ 648 EPBL_esmOperationTrigger 0 "PBUTTON_PRESSED_STOPPED" 1 "PBUTTON_PRESSED_OKTOPARK" 2 "PBUTTON_PRESSED_FAST" 3 "PBUTTON_PRESSED_UNKNOWN" 4 "PBUTTON_RELEASED" 5 "ACTIVE_PARK_REQUEST" 6 "DI_UNPARK" 7 "TOUCHSCREEN" 8 "WINCHMODE_EXIT" 9 "WINCHMODE_ENTER" 10 "WINCHMODE_UNAVAILABLE" 11 "SERVICE" 12 "DIAG_CLOSE" 13 "DIAG_OPEN" 14 "DIAG_EXIT" 15 "USER_CONFIRMED" 16 "USER_CANCEL" 17 "SPEED_STOPPED" 18 "SPEED_OKAYTOPARK" 19 "SPEED_FAST" 20 "TIMEOUT" 21 "SAVESTATE_ON_BOOT" 22 "REAPPLY" 23 "SUMMON_COMPLETE" 24 "FAULT" 25 "SUMMON_FAULT" 26 "DISQUALIFIED" 27 "EPBM_DISQUALIFIED" 28 "ACCELERATION" 29 "SYSTEM_APPLY" 30 "DRIVER_IS_LEAVING" 31 "AUTOPARK_END" 32 "UI_DOOR_OPEN_REQUEST" 33 "TOUCHSCREEN_INVALID" ;
VAL_ 648 EPBL_csmFaultReason 0 "NONE" 1 "EPBM_DISABLED" 2 "EPBM_FAULTED" 3 "STATE_MISMATCH" 4 "TIMEOUT_CALIBRATE" 5 "APPLY_BLOCKED" 6 "RELEASE_BLOCKED" 7 "TIMEOUT_APPLY_COMPLETE" 8 "TIMEOUT_APPLY_INRUSH" 9 "TIMEOUT_EPB_WAIT_FOR_CLAMP" 10 "TIMEOUT_EPBM_WAIT_FOR_CLAMP" 11 "TIMEOUT_RELEASE_INRUSH" 12 "TIMEOUT_RELEASE_WAIT_FOR_ENDSTOP" 13 "TIMEOUT_RELEASE_NO_LOAD" 14 "TIMEOUT_RELEASE_COMPLETE" 15 "TIMEOUT_EPBM_CUTOFF" 16 "TIMEOUT_NO_RAMP" 17 "TIMEOUT_EPBM_START" 18 "MOTOR_IDLE_FAULT" 19 "MOTOR_ACTIVE_FAULT" 20 "MOTOR_NOT_READY" 21 "EPBM_MIA" 22 "NVM_MISMATCH" 23 "REMOTE_MIA" ;
VAL_ 648 EPBL_summonState 0 "INIT" 1 "IDLE" 2 "ARMED" 3 "ACTIVE" 4 "COMPLETE" 5 "FAULT" 6 "UNAVAILABLE" ;
VAL_ 648 EPBL_unitFaultStatus 0 "NOMINAL" 1 "RETRY" 2 "FAULT" 3 "FAULT_IDLE" ;
VAL_ 648 EPBL_unitStatus 0 "UNKNOWN" 1 "OPEN" 2 "DYNAMIC" 3 "PARK" 4 "START" 5 "SERVICE" 6 "WINCHMODE" 7 "WINCHMODE_RELEASING" 8 "PARKING" 9 "DYNAMIC_APPLYING" 10 "RELEASING" 11 "SERVICE_RELEASING" 12 "PARK_PENDING" 13 "WINCHMODE_PENDING" 14 "SUMMON" 15 "SUMMON_RELEASING" 16 "SUMMON_PARKING" 17 "EXTERNAL_DYNAMIC" 18 "RELEASING_FOR_EXTERNAL_PARK" 19 "EXTERNAL_PARKING" 20 "DYNAMIC_PARKING" 21 "FREE_ROLL_MODE" 22 "COUNT" ;
VAL_ 649 VCLEFT_hvacBlowerITerm 127 "SNA" ;
VAL_ 649 VCLEFT_hvacBlowerCBCCtrlState 0 "ERROR" 1 "IDLE" 2 "OFFLINE" 3 "ONLINE" 4 "COUNT" ;
VAL_ 649 VCLEFT_hvacBlowerCBCEstState 0 "ERROR" 1 "IDLE" 2 "ROVERL" 3 "RS" 4 "RAMPUP" 5 "IDRATED" 6 "RATEDFLUX_OL" 7 "RATEDFLUX" 8 "RAMPDOWN" 9 "LOCKROTOR" 10 "INDUCTANCE_EST" 11 "ROTOR_RESISTANCE" 12 "MOTOR_IDENTIFIED" 13 "ONLINE" 14 "COUNT" ;
VAL_ 649 VCLEFT_hvacBlower_IO_CBC_Status 0 "IDLE" 1 "RX" ;
VAL_ 649 VCLEFT_hvacBlowerIPhase2 255 "SNA" ;
VAL_ 649 VCLEFT_hvacBlowerIPhase1 255 "SNA" ;
VAL_ 649 VCLEFT_hvacBlowerIPhase0 255 "SNA" ;
VAL_ 649 VCLEFT_hvacBlowerRs 255 "SNA" ;
VAL_ 649 VCLEFT_logging10HzIndex 0 "Mux0" 1 "Mux1" ;
VAL_ 659 UI_selfParkTune 15 "SNA" ;
VAL_ 659 UI_redLightStopSignEnable 0 "RLSSW_OFF" 1 "RLSSW_ON" 3 "SNA" ;
VAL_ 659 UI_pedalMap_epas 0 "CHILL" 1 "SPORT" 2 "PERFORMANCE" ;
VAL_ 659 UI_pedalSafetyEnable 0 "PEDAL_SAFETY_OFF" 1 "PEDAL_SAFETY_ON" 3 "SNA" ;
VAL_ 659 UI_ldwEnable 0 "NO_HAPTIC" 1 "LDW_TRIGGERS_HAPTIC" 3 "SNA" ;
VAL_ 659 UI_latControlEnable 0 "OFF" 1 "ON" 2 "UNAVAILABLE" 3 "SNA" ;
VAL_ 659 UI_fcwSensitivity 0 "AEB_SENSITIVITY_EARLY" 1 "AEB_SENSITIVITY_AVERAGE" 2 "AEB_SENSITIVITY_LATE" 3 "SNA" ;
VAL_ 659 UI_fcwEnable 0 "FCW_OFF" 1 "FCW_ON" 3 "SNA" ;
VAL_ 659 UI_bsdEnable 0 "BSD_OFF" 1 "BSD_ON" 3 "SNA" ;
VAL_ 659 UI_autoParkRequest 0 "NONE" 1 "PARK_LEFT_PARALLEL" 2 "PARK_LEFT_CROSS" 3 "PARK_RIGHT_PARALLEL" 4 "PARK_RIGHT_CROSS" 5 "PARALLEL_PULL_OUT_TO_LEFT" 6 "PARALLEL_PULL_OUT_TO_RIGHT" 7 "ABORT" 8 "COMPLETE" 9 "SEARCH" 10 "PAUSE" 11 "RESUME" 12 "BEGIN_PARKING" 15 "SNA" ;
VAL_ 659 UI_autoLaneChangeEnable 0 "OFF" 1 "ON" 3 "SNA" ;
VAL_ 659 UI_ahlbEnable 0 "AHLB_OFF" 1 "AHLB_ON" 3 "SNA" ;
VAL_ 659 UI_aesEnable 0 "AES_OFF" 1 "AES_ON" 3 "SNA" ;
VAL_ 659 UI_aebEnable 0 "AEB_OFF" 1 "AEB_ON" 3 "SNA" ;
VAL_ 659 UI_accOvertakeEnable 0 "ACC_OVERTAKE_OFF" 1 "ACC_OVERTAKE_ON" 3 "SNA" ;
VAL_ 659 UI_distanceUnits 0 "KM" 1 "MILES" ;
VAL_ 659 UI_trailerMode 0 "OFF" 1 "ON" ;
VAL_ 659 UI_zeroSpeedConfirmed 0 "CANCELED" 1 "CONFIRMED" 2 "UNUSED" 3 "SNA" ;
VAL_ 659 UI_winchModeRequest 0 "IDLE" 1 "ENTER" 2 "EXIT" ;
VAL_ 659 UI_parkBrakeRequest 0 "IDLE" 1 "PRESSED" 3 "SNA" ;
VAL_ 659 UI_tractionControlMode 0 "NORMAL_SELECTED" 1 "SLIP_START_SELECTED" 2 "DEV_MODE_1_SELECTED" 3 "DEV_MODE_2_SELECTED" 4 "ROLLS_MODE_SELECTED" 5 "DYNO_MODE_SELECTED" 6 "OFFROAD_ASSIST_SELECTED" ;
VAL_ 659 UI_steeringTuneRequest 0 "COMFORT" 1 "STANDARD" 2 "SPORT" ;
VAL_ 660 UI_windowRequest 0 "IDLE" 1 "GOTO_PERCENT" 2 "GOTO_VENT" 3 "GOTO_CLOSED" 5 "GOTO_CLOSED_CARWASH" 6 "GOTO_PERCENT_RELATIVE" ;
VAL_ 660 UI_packTempLoggingRequest 0 "FALSE" 1 "TRUE" ;
VAL_ 660 UI_lightFlashRequest 0 "INACTIVE" 1 "HOMELINK" 2 "MOBILE_APP" 3 "SENTRY" ;
VAL_ 676 PCS_dcdcBusbarTemp 511 "SNA" ;
VAL_ 676 PCS_ambientTemp 4294966273 "SNA" ;
VAL_ 676 PCS_dcdcTemp 4294966273 "SNA" ;
VAL_ 676 PCS_chgPhCTemp 4294966273 "SNA" ;
VAL_ 676 PCS_chgPhBTemp 4294966273 "SNA" ;
VAL_ 676 PCS_chgPhATemp 4294966273 "SNA" ;
VAL_ 679 CMPD_wasteHeatState 0 "OFF" 1 "ACTIVE" 2 "NOT_AVAILABLE" 3 "UNUSED" ;
VAL_ 679 CMPD_state 0 "INIT" 1 "RUNNING" 2 "STANDBY" 3 "FAULT" 4 "IDLE" 15 "SNA" ;
VAL_ 680 EPBL_brakeDiscWipeRequest 0 "NONE" 1 "LIGHT" 2 "STRONG" 3 "SNA" ;
VAL_ 680 EPBL_cdpRequest 0 "NOT_REQUESTED" 1 "REQUESTED" ;
VAL_ 680 EPBL_telltale 0 "LAMP_OFF" 1 "LAMP_RED_ON" 2 "LAMP_AMBER_ON" 3 "LAMP_RED_FLASH" 7 "SNA" ;
VAL_ 680 EPBL_freeRollModeStatus 0 "UNAVAILABLE" 1 "AVAILABLE" 2 "ENABLED" ;
VAL_ 680 EPBL_systemStatus 0 "UNKNOWN" 1 "RELEASED" 2 "PARKED" 3 "DYNAMIC" 4 "PARKING" 5 "RELEASING" 6 "FAULT" 7 "FAULT_SECURE" 8 "MISMATCH" ;
VAL_ 691 VCRIGHT_cabinTempBreathLevel 255 "SNA" ;
VAL_ 691 VCRIGHT_cabinTempTopPadAir 240 "SNA" ;
VAL_ 691 VCRIGHT_solarLoadOnVehicle 255 "SNA" ;
VAL_ 691 VCRIGHT_cabinTempInteriorSunnyL3 240 "SNA" ;
VAL_ 691 VCRIGHT_cabinTempSideGlassRight 255 "SNA" ;
VAL_ 691 VCRIGHT_hvacAirflowReason 0 "HVAC_OFF" 1 "MANUAL_FAN_SPEED" 2 "UI_SHORTCUT" 3 "CABIN_TEMPERATURE_CONTROL" 4 "MINIMUM_AUTO_AIRFLOW" 5 "STRATIFICATION_GLASS_ROOF" 6 "STRATIFICATION_INTERIOR_SURFACES" 7 "OCCUPANT_CONVECTION_REQUIREMENT" 8 "COLD_DUCT_LOCKOUT" 9 "CABIN_PURGE" 10 "CABIN_OVERHEAT_PROTECT" 11 "SCREEN_PROTECTION" 12 "EVAP_DRYING" 13 "NONE" ;
VAL_ 691 VCRIGHT_solarLoadLeftOccupant 255 "SNA" ;
VAL_ 691 VCRIGHT_cabinTempInteriorL3 240 "SNA" ;
VAL_ 691 VCRIGHT_cabinTempInteriorSunnyL2 240 "SNA" ;
VAL_ 691 VCRIGHT_cabinTempSideGlassLeft 255 "SNA" ;
VAL_ 691 VCRIGHT_solarLoadRightOccupant 255 "SNA" ;
VAL_ 691 VCRIGHT_cabinTempInteriorSunny 240 "SNA" ;
VAL_ 691 VCRIGHT_convectionDeliveredRight 255 "SNA" ;
VAL_ 691 VCRIGHT_hvacAirFlowModeRow2 0 "NONE" 1 "FLOOR" 2 "PANEL" 3 "PANEL_FLOOR" 4 "DEFROST" 5 "DEFROST_FLOOR" 6 "DEFROST_PANEL" 7 "DEFROST_PANEL_FLOOR" ;
VAL_ 691 VCRIGHT_tempIncarCabinMid 250 "SNA" ;
VAL_ 691 VCRIGHT_tempHtrSurfaceModeledR 511 "SNA" ;
VAL_ 691 VCRIGHT_hvacAirFlowModeRow1 0 "NONE" 1 "FLOOR" 2 "PANEL" 3 "PANEL_FLOOR" 4 "DEFROST" 5 "DEFROST_FLOOR" 6 "DEFROST_PANEL" 7 "DEFROST_PANEL_FLOOR" ;
VAL_ 691 VCRIGHT_cabinTempInterior 240 "SNA" ;
VAL_ 691 VCRIGHT_cabinTempInteriorL2 240 "SNA" ;
VAL_ 691 VCRIGHT_convectionDeliveredLeft 255 "SNA" ;
VAL_ 691 VCRIGHT_hvacAutoTransitionReason 0 "NONE" 1 "HUMIDITY_HIGH" 2 "HUMIDITY_MODERATE" 3 "HUMIDITY_LOW" 4 "TEMP_TARGET_BELOW_THRESHOLD" 5 "TEMP_TARGET_ABOVE_THRESHOLD" 6 "EXCESS_OCCUPANT_CONVECTION" 7 "OCCUPANT_CONVECTION_REQUIREMENT" 8 "TEMP_TARGET_LOW" 9 "DUCTS_COLD" 10 "BI_LEVEL_LANDING" 11 "DEFOG_OVERRIDE" 12 "SET_TEMP_LO" 13 "SET_TEMP_HI" 14 "CABIN_PURGE" 15 "EVAP_DRYING" 16 "HVAC_OFF" 17 "END" ;
VAL_ 691 VCRIGHT_tempHtrSurfaceModeledL 511 "SNA" ;
VAL_ 691 VCRIGHT_solarLoadOnVehFiltered 255 "SNA" ;
VAL_ 691 VCRIGHT_cabinTempWindshield 255 "SNA" ;
VAL_ 691 VCRIGHT_convectionTargetRight 255 "SNA" ;
VAL_ 691 VCRIGHT_tempIncarCabinDeep 255 "SNA" ;
VAL_ 691 VCRIGHT_tempDuctModeledRight 511 "SNA" ;
VAL_ 691 VCRIGHT_cabinTempGlassRoof 255 "SNA" ;
VAL_ 691 VCRIGHT_convectionTargetLeft 255 "SNA" ;
VAL_ 691 VCRIGHT_tempIncarCabinProbe 255 "SNA" ;
VAL_ 691 VCRIGHT_tempDuctModeledLeft 511 "SNA" ;
VAL_ 691 VCRIGHT_logging1HzIndex 0 "HVAC_TEMP_SENSORS_AND_ESTIMATES_1" 1 "HVAC_TEMP_SENSORS_AND_ESTIMATES_2" 2 "HVAC_HUMIDITY_HEATER" 3 "HVAC_STATUS_AIRFLOW" 4 "HVAC_COMFORT_SOLAR" 5 "HEATER_AND_DUCT_TARGETS" 6 "HVAC_ACTUATOR_VOLTAGES" 7 "HVAC_ACTUATOR_ENDSTOP" 8 "HVAC_ACTUATOR_ZEROSTOP" 9 "HVAC_MISCELLANEOUS_1" 10 "HVAC_MISCELLANEOUS_2" 11 "END" ;
VAL_ 694 DI_vehicleHoldTelltaleOn 0 "OFF" 1 "ON" ;
VAL_ 694 DI_btcStateUI 0 "OFF" 1 "ON" ;
VAL_ 694 DI_ptcStateGlobalUI 0 "FAULTED" 1 "BACKUP" 2 "ON" 3 "SNA" ;
VAL_ 694 DI_tractionControlModeUI 0 "NORMAL" 1 "SLIP_START" 2 "DEV_MODE_1" 3 "DEV_MODE_2" 4 "ROLLS_MODE" 5 "DYNO_MODE" 6 "OFFROAD_ASSIST" ;
VAL_ 694 DI_tcTelltaleOn 0 "OFF" 1 "ON" ;
VAL_ 694 DI_tcTelltaleFlash 0 "OFF" 1 "ON" ;
VAL_ 694 DI_vdcTelltaleOn 0 "OFF" 1 "ON" ;
VAL_ 694 DI_vdcTelltaleFlash 0 "OFF" 1 "ON" ;
VAL_ 702 FC_minVoltageLimit_value 4294934528 "SNA" ;
VAL_ 702 FC_currentLimit_value 4294934528 "SNA" ;
VAL_ 702 FC_powerLimit_value 4294934528 "SNA" ;
VAL_ 706 VCLEFT_windowPositionStateLR 0 "UNKNOWN" 1 "CLOSED" 2 "CRACKED" 3 "VENT" 4 "PARTIAL_OPEN" 5 "FULL_OPEN" 6 "CLOSED_TRIM_CLEAR" ;
VAL_ 706 VCLEFT_windowPositionStateLF 0 "UNKNOWN" 1 "CLOSED" 2 "CRACKED" 3 "VENT" 4 "PARTIAL_OPEN" 5 "FULL_OPEN" 6 "CLOSED_TRIM_CLEAR" ;
VAL_ 706 VCLEFT_windowCtrlUnavailableLR 0 "NONE" 1 "UNEXPECTED" 2 "SWITCH_PRESSED" 3 "PINCH" 4 "THERMAL_LIMIT" 5 "UNCALIBRATED" 6 "VEHICLE_IN_DRIVE" 7 "WINDOW_MOVING" ;
VAL_ 706 VCLEFT_windowControlStateLR 0 "IDLE" 1 "CLOSING" 2 "GOING_TO_POSITION" ;
VAL_ 706 VCLEFT_windowCtrlUnavailableLF 0 "NONE" 1 "UNEXPECTED" 2 "SWITCH_PRESSED" 3 "PINCH" 4 "THERMAL_LIMIT" 5 "UNCALIBRATED" 6 "VEHICLE_IN_DRIVE" 7 "WINDOW_MOVING" ;
VAL_ 706 VCLEFT_windowControlStateLF 0 "IDLE" 1 "CLOSING" 2 "GOING_TO_POSITION" ;
VAL_ 706 VCLEFT_windowStateLR 0 "STOPPED" 1 "MOVING_UP" 2 "MOVING_DOWN" 3 "BACKOFF" 4 "SHORT_DROP" 5 "SHORT_DROP_REVERSE" 6 "MOVING_AUTO_UP" 7 "MOVING_AUTO_DOWN" 8 "BACKDRIVE" ;
VAL_ 706 VCLEFT_windowStopReqReasonLR 0 "NONE" 1 "SWITCH_CANCEL_AUTO_MOVEMENT" 2 "SWITCH_RELEASED" 3 "REAR_LOCKOUT" 4 "THERMAL" 5 "STALL" 6 "STATE_TIMEOUT" 7 "FULL_OPEN_SOFT_STOP" 8 "EXTERNAL_REQUEST" ;
VAL_ 706 VCLEFT_windowStopReasonLR 0 "NONE" 1 "DOOR_OPEN_TRIM_PROTECT" 2 "NEW_REQUEST" 3 "TARGET_REACHED" 4 "STOP_REQUEST" 5 "FULL_OPEN_SOFT_STOP" 6 "STATE_TIMEOUT" ;
VAL_ 706 VCLEFT_windowThermalModeLR 0 "SNA" 1 "NORMAL" 2 "ALERT" 3 "CRITICAL" ;
VAL_ 706 VCLEFT_windowStopReqReasonLF 0 "NONE" 1 "SWITCH_CANCEL_AUTO_MOVEMENT" 2 "SWITCH_RELEASED" 3 "REAR_LOCKOUT" 4 "THERMAL" 5 "STALL" 6 "STATE_TIMEOUT" 7 "FULL_OPEN_SOFT_STOP" 8 "EXTERNAL_REQUEST" ;
VAL_ 706 VCLEFT_windowStopReasonLF 0 "NONE" 1 "DOOR_OPEN_TRIM_PROTECT" 2 "NEW_REQUEST" 3 "TARGET_REACHED" 4 "STOP_REQUEST" 5 "FULL_OPEN_SOFT_STOP" 6 "STATE_TIMEOUT" ;
VAL_ 706 VCLEFT_windowThermalModeLF 0 "SNA" 1 "NORMAL" 2 "ALERT" 3 "CRITICAL" ;
VAL_ 706 VCLEFT_windowStateLF 0 "STOPPED" 1 "MOVING_UP" 2 "MOVING_DOWN" 3 "BACKOFF" 4 "SHORT_DROP" 5 "SHORT_DROP_REVERSE" 6 "MOVING_AUTO_UP" 7 "MOVING_AUTO_DOWN" 8 "BACKDRIVE" ;
VAL_ 706 VCLEFT_windowStatusIndex 0 "Mux0" 1 "Mux1" ;
VAL_ 707 VCRIGHT_windowPositionStateRR 0 "UNKNOWN" 1 "CLOSED" 2 "CRACKED" 3 "VENT" 4 "PARTIAL_OPEN" 5 "FULL_OPEN" 6 "CLOSED_TRIM_CLEAR" ;
VAL_ 707 VCRIGHT_windowPositionStateRF 0 "UNKNOWN" 1 "CLOSED" 2 "CRACKED" 3 "VENT" 4 "PARTIAL_OPEN" 5 "FULL_OPEN" 6 "CLOSED_TRIM_CLEAR" ;
VAL_ 707 VCRIGHT_windowCtrlUnavailableRR 0 "NONE" 1 "UNEXPECTED" 2 "SWITCH_PRESSED" 3 "PINCH" 4 "THERMAL_LIMIT" 5 "UNCALIBRATED" 6 "VEHICLE_IN_DRIVE" 7 "WINDOW_MOVING" ;
VAL_ 707 VCRIGHT_windowControlStateRR 0 "IDLE" 1 "CLOSING" 2 "GOING_TO_POSITION" ;
VAL_ 707 VCRIGHT_windowCtrlUnavailableRF 0 "NONE" 1 "UNEXPECTED" 2 "SWITCH_PRESSED" 3 "PINCH" 4 "THERMAL_LIMIT" 5 "UNCALIBRATED" 6 "VEHICLE_IN_DRIVE" 7 "WINDOW_MOVING" ;
VAL_ 707 VCRIGHT_windowControlStateRF 0 "IDLE" 1 "CLOSING" 2 "GOING_TO_POSITION" ;
VAL_ 707 VCRIGHT_windowStateRR 0 "STOPPED" 1 "MOVING_UP" 2 "MOVING_DOWN" 3 "BACKOFF" 4 "SHORT_DROP" 5 "SHORT_DROP_REVERSE" 6 "MOVING_AUTO_UP" 7 "MOVING_AUTO_DOWN" 8 "BACKDRIVE" ;
VAL_ 707 VCRIGHT_windowStopReqReasonRR 0 "NONE" 1 "SWITCH_CANCEL_AUTO_MOVEMENT" 2 "SWITCH_RELEASED" 3 "REAR_LOCKOUT" 4 "THERMAL" 5 "STALL" 6 "STATE_TIMEOUT" 7 "FULL_OPEN_SOFT_STOP" 8 "EXTERNAL_REQUEST" ;
VAL_ 707 VCRIGHT_windowStopReasonRR 0 "NONE" 1 "DOOR_OPEN_TRIM_PROTECT" 2 "NEW_REQUEST" 3 "TARGET_REACHED" 4 "STOP_REQUEST" 5 "FULL_OPEN_SOFT_STOP" 6 "STATE_TIMEOUT" ;
VAL_ 707 VCRIGHT_windowThermalModeRR 0 "SNA" 1 "NORMAL" 2 "ALERT" 3 "CRITICAL" ;
VAL_ 707 VCRIGHT_windowStopReqReasonRF 0 "NONE" 1 "SWITCH_CANCEL_AUTO_MOVEMENT" 2 "SWITCH_RELEASED" 3 "REAR_LOCKOUT" 4 "THERMAL" 5 "STALL" 6 "STATE_TIMEOUT" 7 "FULL_OPEN_SOFT_STOP" 8 "EXTERNAL_REQUEST" ;
VAL_ 707 VCRIGHT_windowStopReasonRF 0 "NONE" 1 "DOOR_OPEN_TRIM_PROTECT" 2 "NEW_REQUEST" 3 "TARGET_REACHED" 4 "STOP_REQUEST" 5 "FULL_OPEN_SOFT_STOP" 6 "STATE_TIMEOUT" ;
VAL_ 707 VCRIGHT_windowThermalModeRF 0 "SNA" 1 "NORMAL" 2 "ALERT" 3 "CRITICAL" ;
VAL_ 707 VCRIGHT_windowStateRF 0 "STOPPED" 1 "MOVING_UP" 2 "MOVING_DOWN" 3 "BACKOFF" 4 "SHORT_DROP" 5 "SHORT_DROP_REVERSE" 6 "MOVING_AUTO_UP" 7 "MOVING_AUTO_DOWN" 8 "BACKDRIVE" ;
VAL_ 707 VCRIGHT_windowStatusIndex 0 "Mux0" 1 "Mux1" ;
